VERSION ""

NS_ :

BS_:

BU_: IVI

BO_ 1629 AVM_A6: 6 Vector__XXX
  SG_ FAP_ChangeViewRequest : 0|1@0+ (1,0) [0|0] "" IVI
  SG_ FAP_FramePattern : 7|7@0+ (1,0) [0|127] "wu" IVI
  SG_ FAP_SwitchGrayOutRequest02 : 8|1@0+ (1,0) [0|0] "" IVI
  SG_ FAP_SwitchGrayOutRequest01 : 9|1@0+ (1,0) [0|0] "" IVI
  SG_ FAP_GuideDisplayRequest : 15|6@0+ (1,0) [0|63] "wu" IVI
  SG_ FAP_SwitchGrayOutRequest04 : 16|1@0+ (1,0) [0|0] "" IVI
  SG_ FAP_SwitchGrayOutRequest03 : 17|1@0+ (1,0) [0|0] "" IVI
  SG_ FAP_MessageDisplayRequest : 23|6@0+ (1,0) [0|63] "wu" IVI
  SG_ FAP_SwitchGrayOutRequest06 : 24|1@0+ (1,0) [0|0] "" IVI
  SG_ FAP_SwitchGrayOutRequest05 : 25|1@0+ (1,0) [0|0] "" IVI
  SG_ FAP_ParkingTypeRequest : 31|6@0+ (1,0) [0|63] "wu" IVI
  SG_ FAP_SwitchGrayOutRequest08 : 32|1@0+ (1,0) [0|0] "" IVI
  SG_ FAP_SwitchGrayOutRequest07 : 33|1@0+ (1,0) [0|0] "" IVI
  SG_ FAP_PopupDisplayRequest : 39|6@0+ (1,0) [0|63] "wu" IVI
  SG_ FAP_SwitchGrayOutRequest12 : 41|1@0+ (1,0) [0|0] "" IVI
  SG_ FAP_SwitchGrayOutRequest11 : 42|1@0+ (1,0) [0|0] "" IVI
  SG_ FAP_SwitchGrayOutRequest10 : 43|1@0+ (1,0) [0|0] "" IVI
  SG_ FAP_SwitchGrayOutRequest09 : 44|1@0+ (1,0) [0|0] "" IVI
  SG_ FAP_CameraIndicatorRequest : 47|3@0+ (1,0) [0|0] "" IVI

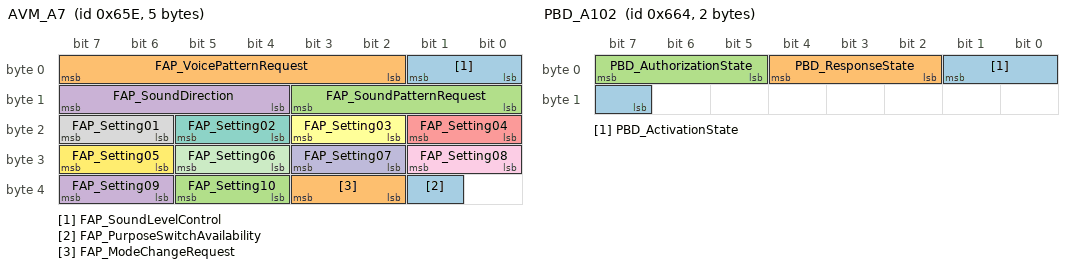
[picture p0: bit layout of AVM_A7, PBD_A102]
BO_ 1630 AVM_A7: 5 Vector__XXX
  SG_ FAP_SoundLevelControl : 1|2@0+ (1,0) [0|0] "" IVI
  SG_ FAP_VoicePatternRequest : 7|6@0+ (1,0) [0|63] "wu" IVI
  SG_ FAP_SoundPatternRequest : 11|4@0+ (1,0) [0|0] "" IVI
  SG_ FAP_SoundDirection : 15|4@0+ (1,0) [0|0] "" IVI
  SG_ FAP_Setting04 : 17|2@0+ (1,0) [0|0] "" IVI
  SG_ FAP_Setting03 : 19|2@0+ (1,0) [0|0] "" IVI
  SG_ FAP_Setting02 : 21|2@0+ (1,0) [0|0] "" IVI
  SG_ FAP_Setting01 : 23|2@0+ (1,0) [0|0] "" IVI
  SG_ FAP_Setting08 : 25|2@0+ (1,0) [0|0] "" IVI
  SG_ FAP_Setting07 : 27|2@0+ (1,0) [0|0] "" IVI
  SG_ FAP_Setting06 : 29|2@0+ (1,0) [0|0] "" IVI
  SG_ FAP_Setting05 : 31|2@0+ (1,0) [0|0] "" IVI
  SG_ FAP_PurposeSwitchAvailability : 33|1@0+ (1,0) [0|0] "" IVI
  SG_ FAP_ModeChangeRequest : 35|2@0+ (1,0) [0|0] "" IVI
  SG_ FAP_Setting10 : 37|2@0+ (1,0) [0|0] "" IVI
  SG_ FAP_Setting09 : 39|2@0+ (1,0) [0|0] "" IVI

BO_ 1634 VDC_R14: 6 Vector__XXX
  SG_ LateralTilt_MMI : 7|7@0+ (1,-60) [-60|60] "°" IVI
  SG_ LongitudinalTilt_MMI : 15|7@0+ (1,-60) [-60|60] "°" IVI

BO_ 1636 PBD_A102: 2 Vector__XXX
  SG_ PBD_ActivationState : 1|3@0+ (1,0) [0|0] "" IVI
  SG_ PBD_ResponseState : 4|3@0+ (1,0) [0|0] "" IVI
  SG_ PBD_AuthorizationState : 7|3@0+ (1,0) [0|0] "" IVI

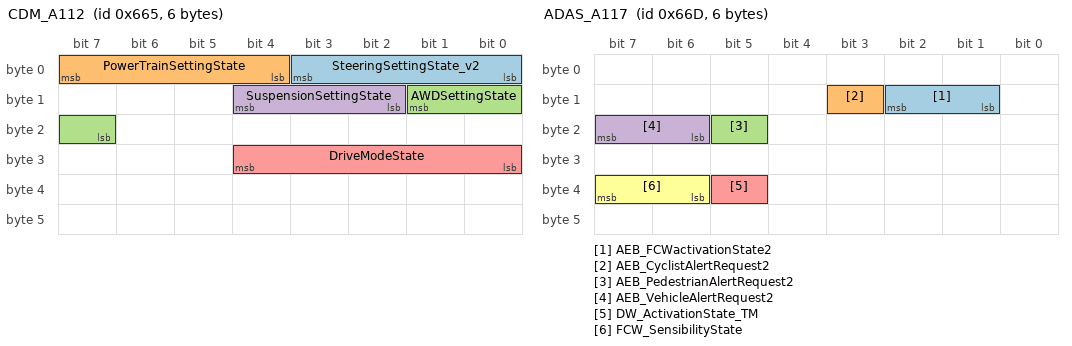
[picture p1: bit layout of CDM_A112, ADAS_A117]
BO_ 1637 CDM_A112: 6 Vector__XXX
  SG_ SteeringSettingState_v2 : 3|4@0+ (1,0) [0|0] "" IVI
  SG_ PowerTrainSettingState : 7|4@0+ (1,0) [0|0] "" IVI
  SG_ AWDSettingState : 9|3@0+ (1,0) [0|0] "" IVI
  SG_ SuspensionSettingState : 12|3@0+ (1,0) [0|0] "" IVI
  SG_ DriveModeState : 28|5@0+ (1,0) [0|0] "" IVI

BO_ 1639 HEVC_A113: 8 Vector__XXX
  SG_ AllRouteSegmentsRequest : 53|1@0+ (1,0) [0|0] "" IVI

BO_ 1640 HEVC_A114: 8 Vector__XXX
  SG_ ChargeSpotPowerLevel : 43|9@0+ (0.3,0) [0|150] "kW" IVI
  SG_ SCdurabilityInhibition : 57|1@0+ (1,0) [0|0] "" IVI

BO_ 1645 ADAS_A117: 6 Vector__XXX
  SG_ AEB_FCWactivationState2 : 10|2@0+ (1,0) [0|0] "" IVI
  SG_ AEB_CyclistAlertRequest2 : 11|1@0+ (1,0) [0|0] "" IVI
  SG_ AEB_PedestrianAlertRequest2 : 21|1@0+ (1,0) [0|0] "" IVI
  SG_ AEB_VehicleAlertRequest2 : 23|2@0+ (1,0) [0|0] "" IVI
  SG_ DW_ActivationState_TM : 37|1@0+ (1,0) [0|0] "" IVI
  SG_ FCW_SensibilityState : 39|2@0+ (1,0) [0|0] "" IVI

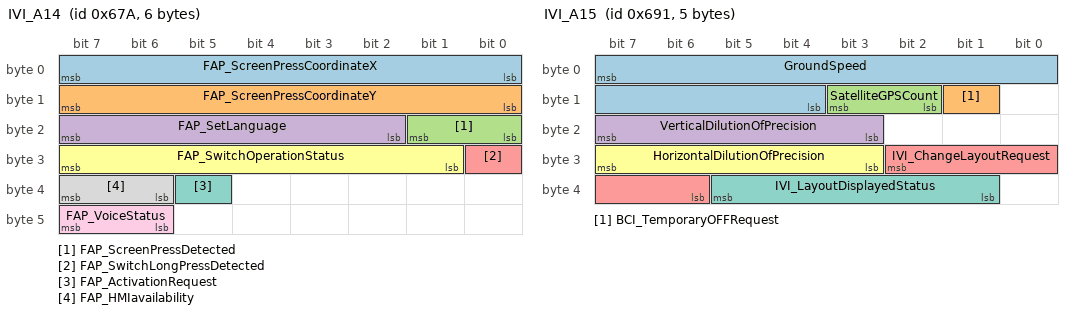
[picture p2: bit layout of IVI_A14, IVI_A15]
BO_ 1658 IVI_A14: 6 IVI
  SG_ FAP_ScreenPressCoordinateX : 7|8@0+ (1,0) [0|255] "wu" Vector__XXX
  SG_ FAP_ScreenPressCoordinateY : 15|8@0+ (1,0) [0|255] "wu" Vector__XXX
  SG_ FAP_ScreenPressDetected : 17|2@0+ (1,0) [0|0] "" Vector__XXX
  SG_ FAP_SetLanguage : 23|6@0+ (1,0) [0|63] "wu" Vector__XXX
  SG_ FAP_SwitchLongPressDetected : 24|1@0+ (1,0) [0|0] "" Vector__XXX
  SG_ FAP_SwitchOperationStatus : 31|7@0+ (1,0) [0|127] "wu" Vector__XXX
  SG_ FAP_ActivationRequest : 37|1@0+ (1,0) [0|0] "" Vector__XXX
  SG_ FAP_HMIavailability : 39|2@0+ (1,0) [0|0] "" Vector__XXX
  SG_ FAP_VoiceStatus : 47|2@0+ (1,0) [0|0] "" Vector__XXX

BO_ 1659 HFM_A102: 3 Vector__XXX
  SG_ UserIdentification_IKeyLink : 7|3@0+ (1,0) [0|0] "" IVI

BO_ 1660 HVAC_A102: 8 Vector__XXX
  SG_ RearSeatsLockStatus : 1|2@0+ (1,0) [0|0] "" IVI
  SG_ SecondRowRightSeatStatus : 4|3@0+ (1,0) [0|0] "" IVI
  SG_ SecondRowLeftSeatStatus : 7|3@0+ (1,0) [0|0] "" IVI
  SG_ ClimAutoRecyclingDisplayStatus : 8|1@0+ (1,0) [0|0] "" IVI
  SG_ ClimACDisplayStatus : 9|1@0+ (1,0) [0|0] "" IVI
  SG_ ThirdRowRightSeatStatus : 12|3@0+ (1,0) [0|0] "" IVI
  SG_ ThirdRowLeftSeatStatus : 15|3@0+ (1,0) [0|0] "" IVI
  SG_ ClimEVHeaterDisplayStatus : 16|1@0+ (1,0) [0|0] "" IVI
  SG_ ClimDriverZoneDisplayStatus : 17|1@0+ (1,0) [0|0] "" IVI
  SG_ ClimDriverZoneDisplay : 19|2@0+ (1,0) [0|0] "" IVI
  SG_ ClimClearnessDisplayStatus : 20|1@0+ (1,0) [0|0] "" IVI
  SG_ ClimBlowingLevelDisplayStatus : 21|1@0+ (1,0) [0|0] "" IVI
  SG_ ClimBlowingAutoDisplay : 23|2@0+ (1,0) [0|0] "" IVI
  SG_ ClimHumidityDisplayStatus : 24|1@0+ (1,0) [0|0] "" IVI
  SG_ ClimForestSettingDisplayStatus : 25|1@0+ (1,0) [0|0] "" IVI
  SG_ ClimForestDisplayStatus : 26|1@0+ (1,0) [0|0] "" IVI
  SG_ ClimForestDisplay : 28|2@0+ (1,0) [0|0] "" IVI
  SG_ ClimFlowDistrDisplayStatus : 29|1@0+ (1,0) [0|0] "" IVI
  SG_ ClimEVHeaterDisplay : 31|2@0+ (1,0) [0|0] "" IVI
  SG_ ClimLinkDefrostAndClearnesDisp : 33|2@0+ (1,0) [0|0] "" IVI
  SG_ ClimHumiditySensorSensitivDisp : 36|3@0+ (1,0) [0|0] "" IVI
  SG_ ClimHumidityDisplay : 39|3@0+ (1,0) [0|0] "" IVI
  SG_ ClimRightAutoDisplay : 41|2@0+ (1,0) [0|0] "" IVI
  SG_ ClimOFFModeDisplayStatus : 42|1@0+ (1,0) [0|0] "" IVI
  SG_ ClimLinkMaxFanSpeedAutoDisplay : 45|3@0+ (1,0) [0|0] "" IVI
  SG_ ClimLinkFreshRecyAndAutoDisplay : 47|2@0+ (1,0) [0|0] "" IVI
  SG_ ClimRightFlowDistrDisplayStatus : 48|1@0+ (1,0) [0|0] "" IVI
  SG_ ClimRightBlowingLevelDispStatus : 49|1@0+ (1,0) [0|0] "" IVI
  SG_ ClimRightBlowingLevelDisplay : 53|4@0+ (1,0) [0|0] "" IVI
  SG_ ClimRightBlowingAutoDisplay : 55|2@0+ (1,0) [0|0] "" IVI
  SG_ ClimTempDisplayStatus : 56|1@0+ (1,0) [0|0] "" IVI
  SG_ ClimSyncDisplayStatus : 57|1@0+ (1,0) [0|0] "" IVI
  SG_ ClimSyncDisplay : 59|2@0+ (1,0) [0|0] "" IVI
  SG_ ClimRightTempDisplayStatus : 60|1@0+ (1,0) [0|0] "" IVI
  SG_ ClimRightFlowDistrDisplay : 63|3@0+ (1,0) [0|0] "" IVI

BO_ 1661 IVI_N104: 7 IVI
  SG_ AltitudePosition : 7|16@0+ (0.1,-500) [-500|3000] "m" Vector__XXX
  SG_ ITM_FrontLeftSeatHeatPush : 16|1@0+ (1,0) [0|1] "-" Vector__XXX
  SG_ ITM_FrontLeftSeatDownPush : 17|1@0+ (1,0) [0|1] "" Vector__XXX
  SG_ ITM_ForcedRecyclingLongPush : 18|1@0+ (1,0) [0|1] "-" Vector__XXX
  SG_ ITM_ForcedFreshLongPush : 19|1@0+ (1,0) [0|1] "-" Vector__XXX
  SG_ ITM_AirIntakeOperationType : 21|2@0+ (1,0) [0|0] "" Vector__XXX
  SG_ ITM_AirIntakeModePush : 22|1@0+ (1,0) [0|1] "-" Vector__XXX
  SG_ ITM_AirIntakeModeLongPush : 23|1@0+ (1,0) [0|1] "-" Vector__XXX
  SG_ ITM_FrontRightSeatUpPush : 26|1@0+ (1,0) [0|1] "" Vector__XXX
  SG_ ITM_FrontRightSeatOFFPush : 27|1@0+ (1,0) [0|1] "-" Vector__XXX
  SG_ ITM_FrontRightSeatHeatPush : 28|1@0+ (1,0) [0|1] "-" Vector__XXX
  SG_ ITM_FrontRightSeatDownPush : 29|1@0+ (1,0) [0|1] "" Vector__XXX
  SG_ ITM_FrontLeftSeatUpPush : 30|1@0+ (1,0) [0|1] "" Vector__XXX
  SG_ ITM_FrontLeftSeatOFFPush : 31|1@0+ (1,0) [0|1] "-" Vector__XXX
  SG_ ITM_SecondRowRightSeatDownPush : 32|1@0+ (1,0) [0|1] "" Vector__XXX
  SG_ ITM_SecondRowLeftSeatUpPush : 33|1@0+ (1,0) [0|1] "" Vector__XXX
  SG_ ITM_SecondRowLeftSeatOFFPush : 34|1@0+ (1,0) [0|1] "-" Vector__XXX
  SG_ ITM_SecondRowLeftSeatHeatPush : 35|1@0+ (1,0) [0|1] "-" Vector__XXX
  SG_ ITM_SecondRowLeftSeatDownPush : 36|1@0+ (1,0) [0|1] "" Vector__XXX
  SG_ ITM_RecyclingModeRequest : 39|3@0+ (1,0) [0|0] "" Vector__XXX
  SG_ ITM_ThirdRowRightSeatDownPush : 40|1@0+ (1,0) [0|1] "" Vector__XXX
  SG_ ITM_ThirdRowLeftSeatUpPush : 41|1@0+ (1,0) [0|1] "" Vector__XXX
  SG_ ITM_ThirdRowLeftSeatOFFPush : 42|1@0+ (1,0) [0|1] "-" Vector__XXX
  SG_ ITM_ThirdRowLeftSeatHeatPush : 43|1@0+ (1,0) [0|1] "-" Vector__XXX
  SG_ ITM_ThirdRowLeftSeatDownPush : 44|1@0+ (1,0) [0|1] "" Vector__XXX
  SG_ ITM_SecondRowRightSeatUpPush : 45|1@0+ (1,0) [0|1] "" Vector__XXX
  SG_ ITM_SecondRowRightSeatOFFPush : 46|1@0+ (1,0) [0|1] "-" Vector__XXX
  SG_ ITM_SecondRowRightSeatHeatPush : 47|1@0+ (1,0) [0|1] "-" Vector__XXX
  SG_ ITM_ThirdRowRightSeatUpPush : 53|1@0+ (1,0) [0|1] "" Vector__XXX
  SG_ ITM_ThirdRowRightSeatOFFPush : 54|1@0+ (1,0) [0|1] "-" Vector__XXX
  SG_ ITM_ThirdRowRightSeatHeatPush : 55|1@0+ (1,0) [0|1] "-" Vector__XXX

BO_ 1662 IVI_A102: 8 IVI
  SG_ PassengerSeatMemoRecall : 4|3@0+ (1,0) [0|0] "" Vector__XXX
  SG_ PassengerSeatMemoRequest : 7|3@0+ (1,0) [0|0] "" Vector__XXX
  SG_ SecondRowRightSeatRequest : 11|4@0+ (1,0) [0|0] "" Vector__XXX
  SG_ SecondRowLeftSeatRequest : 15|4@0+ (1,0) [0|0] "" Vector__XXX
  SG_ ThirdRowRightSeatRequest : 19|4@0+ (1,0) [0|0] "" Vector__XXX
  SG_ ThirdRowLeftSeatRequest : 23|4@0+ (1,0) [0|0] "" Vector__XXX
  SG_ ClimClearnessPush : 24|1@0+ (1,0) [0|1] "-" Vector__XXX
  SG_ ClimACPush : 25|1@0+ (1,0) [0|1] "-" Vector__XXX
  SG_ WirelessChargeActivationReq : 27|2@0+ (1,0) [0|0] "" Vector__XXX
  SG_ RearSeatsLockRequest : 31|2@0+ (1,0) [0|0] "" Vector__XXX
  SG_ ClimHumiditySensorSensitivitReq : 34|3@0+ (1,0) [0|0] "" Vector__XXX
  SG_ ClimForestPush : 35|1@0+ (1,0) [0|1] "" Vector__XXX
  SG_ ClimForcedRecyclingPush : 36|1@0+ (1,0) [0|1] "-" Vector__XXX
  SG_ ClimForcedFreshPush : 37|1@0+ (1,0) [0|1] "-" Vector__XXX
  SG_ ClimEVHeaterPush : 38|1@0+ (1,0) [0|1] "-" Vector__XXX
  SG_ ClimDriverZonePush : 39|1@0+ (1,0) [0|1] "" Vector__XXX
  SG_ ClimRightFlowDistrDefPush : 40|1@0+ (1,0) [0|1] "-" Vector__XXX
  SG_ TimeFormatDisplay : 43|1@0+ (1,0) [0|0] "" Vector__XXX
  SG_ ClimFPrightBlowingRequest : 47|4@0+ (1,0) [0|0] "" Vector__XXX
  SG_ ClimRightFlowDistrVentPush : 48|1@0+ (1,0) [0|1] "-" Vector__XXX
  SG_ ClimRightFlowDistrFeetPush : 49|1@0+ (1,0) [0|1] "-" Vector__XXX
  SG_ ClimLinkPriorityFLSeatAutoReq : 52|3@0+ (1,0) [0|0] "" Vector__XXX
  SG_ ClimLinkMaxFanSpeedAutoReq : 55|3@0+ (1,0) [0|0] "" Vector__XXX
  SG_ ClimLinkDefrostAndClearnesPush : 56|1@0+ (1,0) [0|1] "" Vector__XXX
  SG_ ClimRightAutoNormalPush : 57|1@0+ (1,0) [0|1] "-" Vector__XXX
  SG_ FrontRightSeatAutoPush : 58|1@0+ (1,0) [0|1] "-" Vector__XXX
  SG_ FrontLeftSeatAutoPush : 59|1@0+ (1,0) [0|1] "-" Vector__XXX
  SG_ ClimSyncPush : 60|1@0+ (1,0) [0|1] "-" Vector__XXX
  SG_ ClimLinkPriorityFRSeatAutoReq : 63|3@0+ (1,0) [0|0] "" Vector__XXX

BO_ 1677 IVI_A6: 3 IVI
  SG_ DistanceToDestination : 7|12@0+ (20,0) [0|81880] "m" Vector__XXX
  SG_ TimeToDestination : 11|10@0+ (10,0) [0|10220] "s" Vector__XXX

BO_ 1681 IVI_A15: 5 IVI
  SG_ GroundSpeed : 7|12@0+ (0.05,0) [0|150] "Kph" Vector__XXX
  SG_ BCI_TemporaryOFFRequest : 9|1@0+ (1,0) [0|0] "" Vector__XXX
  SG_ SatelliteGPSCount : 11|2@0+ (1,0) [0|3] "wu" Vector__XXX
  SG_ VerticalDilutionOfPrecision : 23|5@0+ (0.1,0) [0|3.1] "wu" Vector__XXX
  SG_ IVI_ChangeLayoutRequest : 26|5@0+ (1,0) [0|0] "" Vector__XXX
  SG_ HorizontalDilutionOfPrecision : 31|5@0+ (0.1,0) [0|3.1] "wu" Vector__XXX
  SG_ IVI_LayoutDisplayedStatus : 37|5@0+ (1,0) [0|0] "" Vector__XXX

BO_ 1682 HVAC_A6: 2 Vector__XXX
  SG_ ClimHeatedSteeringWheelDisplay : 5|2@0+ (1,0) [0|0] "" IVI
  SG_ ClimDualModeDisplay_v2 : 7|2@0+ (1,0) [0|0] "" IVI

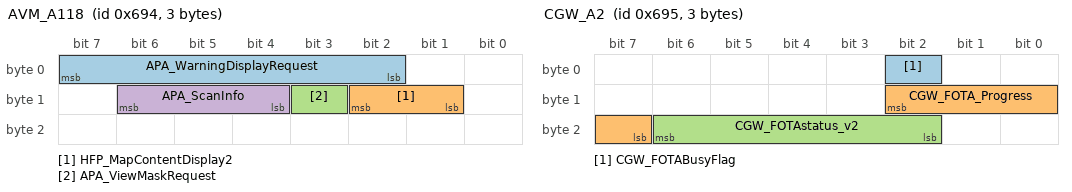
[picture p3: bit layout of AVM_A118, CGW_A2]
BO_ 1684 AVM_A118: 3 Vector__XXX
  SG_ APA_WarningDisplayRequest : 7|6@0+ (1,0) [0|0] "" IVI
  SG_ HFP_MapContentDisplay2 : 10|2@0+ (1,0) [0|0] "" IVI
  SG_ APA_ViewMaskRequest : 11|1@0+ (1,0) [0|0] "" IVI
  SG_ APA_ScanInfo : 14|3@0+ (1,0) [0|0] "" IVI

BO_ 1685 CGW_A2: 3 Vector__XXX
  SG_ CGW_FOTABusyFlag : 2|1@0+ (1,0) [0|0] "" IVI
  SG_ CGW_FOTA_Progress : 10|4@0+ (10,0) [0|100] "%" IVI
  SG_ CGW_FOTAstatus_v2 : 22|5@0+ (1,0) [0|0] "" IVI

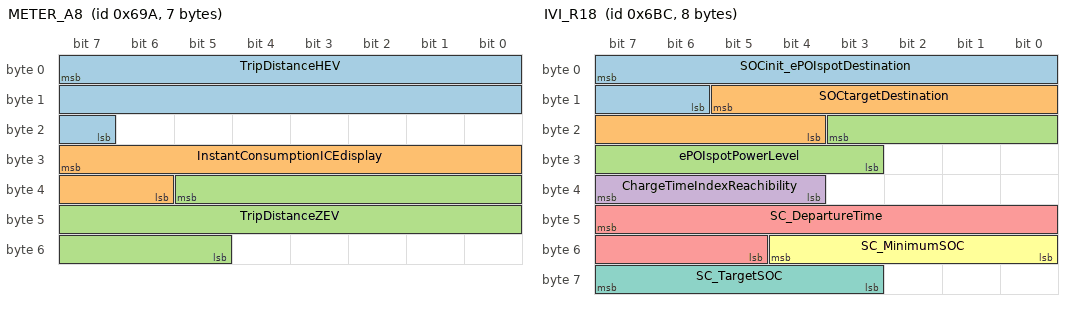
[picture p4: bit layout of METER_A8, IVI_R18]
BO_ 1690 METER_A8: 7 Vector__XXX
  SG_ TripDistanceHEV : 7|17@0+ (0.1,0) [0|10000] "-" IVI
  SG_ InstantConsumptionICEdisplay : 31|10@0+ (0.1,0) [0|102.3] "" IVI
  SG_ TripDistanceZEV : 37|17@0+ (0.1,0) [0|10000] "-" IVI

BO_ 1695 VehicleID_CANHS_R_01: 4 Vector__XXX
  SG_ VehicleID : 7|32@0+ (1,0) [0|0] "" IVI

BO_ 1697 ADASISv2_A106: 8 IVI
  SG_ ADASISv2_METADATA : 7|64@0+ (1,0) [0|0] "" Vector__XXX

BO_ 1703 BCM_R14: 6 Vector__XXX
  SG_ ProgrammedChargeStatus : 45|2@0+ (1,0) [0|0] "" IVI

BO_ 1724 IVI_R18: 8 IVI
  SG_ SOCinit_ePOIspotDestination : 7|10@0+ (0.1,0) [0|100] "%" Vector__XXX
  SG_ SOCtargetDestination : 13|10@0+ (0.1,0) [0|100] "%" Vector__XXX
  SG_ ePOIspotPowerLevel : 19|9@0+ (0.2,0) [0|100] "kW" Vector__XXX
  SG_ ChargeTimeIndexReachibility : 39|4@0+ (1,0) [0|0] "" Vector__XXX
  SG_ SC_DepartureTime : 47|11@0+ (5,0) [0|10080] "min" Vector__XXX
  SG_ SC_MinimumSOC : 52|5@0+ (5,0) [0|100] "%" Vector__XXX
  SG_ SC_TargetSOC : 63|5@0+ (5,0) [0|100] "%" Vector__XXX

BO_ 1742 ADAS_A124: 7 Vector__XXX
  SG_ PreferedLaneAssist_State : 37|2@0+ (1,0) [0|0] "" IVI

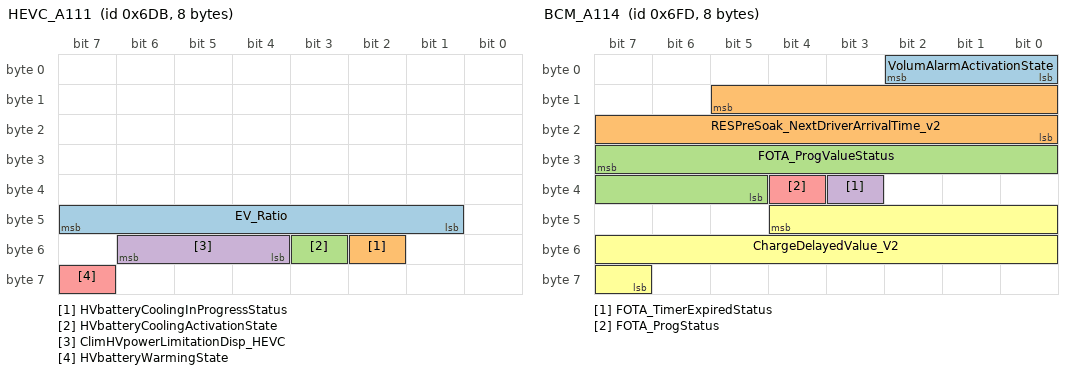
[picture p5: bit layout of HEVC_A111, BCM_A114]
BO_ 1755 HEVC_A111: 8 Vector__XXX
  SG_ EV_Ratio : 47|7@0+ (1,0) [0|100] "%" IVI
  SG_ HVbatteryCoolingInProgressStatus : 50|1@0+ (1,0) [0|0] "" IVI
  SG_ HVbatteryCoolingActivationState : 51|1@0+ (1,0) [0|0] "" IVI
  SG_ ClimHVpowerLimitationDisp_HEVC : 54|3@0+ (1,0) [0|0] "" IVI
  SG_ HVbatteryWarmingState : 63|1@0+ (1,0) [0|0] "" IVI

BO_ 1779 IVI_R8: 8 IVI
  SG_ ChargeCal1DurationChange_MMI : 7|11@0+ (1,0) [0|1440] "min" Vector__XXX
  SG_ ChargeCal1BeginHourChange_MMI : 12|5@0+ (1,0) [0|23] "h" Vector__XXX
  SG_ ChargeCal1TuesdayChange_MMI : 16|1@0+ (1,0) [0|0] "" Vector__XXX
  SG_ ChargeCal1MondayChange_MMI : 17|1@0+ (1,0) [0|0] "" Vector__XXX
  SG_ ChargeCal1BeginMinChange_MMI : 23|6@0+ (1,0) [0|59] "min" Vector__XXX
  SG_ ChargeCal1SundayChange_MMI : 27|1@0+ (1,0) [0|0] "" Vector__XXX
  SG_ ChargeCal1SaturdayChange_MMI : 28|1@0+ (1,0) [0|0] "" Vector__XXX
  SG_ ChargeCal1FridayChange_MMI : 29|1@0+ (1,0) [0|0] "" Vector__XXX
  SG_ ChargeCal1ThursdayChange_MMI : 30|1@0+ (1,0) [0|0] "" Vector__XXX
  SG_ ChargeCal1WednesdayChange_MMI : 31|1@0+ (1,0) [0|0] "" Vector__XXX
  SG_ ChargeCal2DurationChange_MMI : 39|11@0+ (1,0) [0|1440] "min" Vector__XXX
  SG_ ChargeCal2BeginHourChange_MMI : 44|5@0+ (1,0) [0|23] "h" Vector__XXX
  SG_ ChargeCal2TuesdayChange_MMI : 48|1@0+ (1,0) [0|0] "" Vector__XXX
  SG_ ChargeCal2MondayChange_MMI : 49|1@0+ (1,0) [0|0] "" Vector__XXX
  SG_ ChargeCal2BeginMinChange_MMI : 55|6@0+ (1,0) [0|59] "min" Vector__XXX
  SG_ ChargeCalAllChange_MMI : 58|2@0+ (1,0) [0|0] "" Vector__XXX
  SG_ ChargeCal2SundayChange_MMI : 59|1@0+ (1,0) [0|0] "" Vector__XXX
  SG_ ChargeCal2SaturdayChange_MMI : 60|1@0+ (1,0) [0|0] "" Vector__XXX
  SG_ ChargeCal2FridayChange_MMI : 61|1@0+ (1,0) [0|0] "" Vector__XXX
  SG_ ChargeCal2ThursdayChange_MMI : 62|1@0+ (1,0) [0|0] "" Vector__XXX
  SG_ ChargeCal2WednesdayChange_MMI : 63|1@0+ (1,0) [0|0] "" Vector__XXX

BO_ 1780 IVI_R9: 8 IVI
  SG_ ChargeCal3DurationChange_MMI : 7|11@0+ (1,0) [0|1440] "min" Vector__XXX
  SG_ ChargeCal3BeginHourChange_MMI : 12|5@0+ (1,0) [0|23] "h" Vector__XXX
  SG_ ChargeCal3TuesdayChange_MMI : 16|1@0+ (1,0) [0|0] "" Vector__XXX
  SG_ ChargeCal3MondayChange_MMI : 17|1@0+ (1,0) [0|0] "" Vector__XXX
  SG_ ChargeCal3BeginMinChange_MMI : 23|6@0+ (1,0) [0|59] "min" Vector__XXX
  SG_ ChargeCal3SundayChange_MMI : 27|1@0+ (1,0) [0|0] "" Vector__XXX
  SG_ ChargeCal3SaturdayChange_MMI : 28|1@0+ (1,0) [0|0] "" Vector__XXX
  SG_ ChargeCal3FridayChange_MMI : 29|1@0+ (1,0) [0|0] "" Vector__XXX
  SG_ ChargeCal3ThursdayChange_MMI : 30|1@0+ (1,0) [0|0] "" Vector__XXX
  SG_ ChargeCal3WednesdayChange_MMI : 31|1@0+ (1,0) [0|0] "" Vector__XXX
  SG_ ChargeCal4DurationChange_MMI : 39|11@0+ (1,0) [0|1440] "min" Vector__XXX
  SG_ ChargeCal4BeginHourChange_MMI : 44|5@0+ (1,0) [0|23] "h" Vector__XXX
  SG_ ChargeCal4TuesdayChange_MMI : 48|1@0+ (1,0) [0|0] "" Vector__XXX
  SG_ ChargeCal4MondayChange_MMI : 49|1@0+ (1,0) [0|0] "" Vector__XXX
  SG_ ChargeCal4BeginMinChange_MMI : 55|6@0+ (1,0) [0|59] "min" Vector__XXX
  SG_ ChargeCal4SundayChange_MMI : 59|1@0+ (1,0) [0|0] "" Vector__XXX
  SG_ ChargeCal4SaturdayChange_MMI : 60|1@0+ (1,0) [0|0] "" Vector__XXX
  SG_ ChargeCal4FridayChange_MMI : 61|1@0+ (1,0) [0|0] "" Vector__XXX
  SG_ ChargeCal4ThursdayChange_MMI : 62|1@0+ (1,0) [0|0] "" Vector__XXX
  SG_ ChargeCal4WednesdayChange_MMI : 63|1@0+ (1,0) [0|0] "" Vector__XXX

BO_ 1781 IVI_R10: 8 IVI
  SG_ ChargeCal5DurationChange_MMI : 7|11@0+ (1,0) [0|1440] "min" Vector__XXX
  SG_ ChargeCal5BeginHourChange_MMI : 12|5@0+ (1,0) [0|23] "h" Vector__XXX
  SG_ ChargeCal5TuesdayChange_MMI : 16|1@0+ (1,0) [0|0] "" Vector__XXX
  SG_ ChargeCal5MondayChange_MMI : 17|1@0+ (1,0) [0|0] "" Vector__XXX
  SG_ ChargeCal5BeginMinChange_MMI : 23|6@0+ (1,0) [0|59] "min" Vector__XXX
  SG_ ChargeDelayedRequestValue : 26|11@0+ (1,1) [1|1440] "min" Vector__XXX
  SG_ ChargeCal5SundayChange_MMI : 27|1@0+ (1,0) [0|0] "" Vector__XXX
  SG_ ChargeCal5SaturdayChange_MMI : 28|1@0+ (1,0) [0|0] "" Vector__XXX
  SG_ ChargeCal5FridayChange_MMI : 29|1@0+ (1,0) [0|0] "" Vector__XXX
  SG_ ChargeCal5ThursdayChange_MMI : 30|1@0+ (1,0) [0|0] "" Vector__XXX
  SG_ ChargeCal5WednesdayChange_MMI : 31|1@0+ (1,0) [0|0] "" Vector__XXX
  SG_ EcoTripResetRequest : 40|1@0+ (1,0) [0|0] "" Vector__XXX
  SG_ SC_UserElecPriceSetNbSlot : 45|5@0+ (1,0) [0|24] "" Vector__XXX
  SG_ ChargeDelayedRequest : 46|1@0+ (1,0) [0|0] "" Vector__XXX
  SG_ ChargeAlwaysRequest : 47|1@0+ (1,0) [0|0] "" Vector__XXX
  SG_ SC_UserElecPriceSetSlotDuration : 55|5@0+ (30,0) [0|720] "min" Vector__XXX
  SG_ SC_UserElecPriceSetRelativeCost : 62|4@0+ (1,0) [0|15] "" Vector__XXX
  SG_ FuelSaveClearHistoRequest : 63|1@0+ (1,0) [0|0] "" Vector__XXX

BO_ 1782 IVI_R11: 7 IVI
  SG_ PreSoakCal1ArrivalHourChange_MMI : 1|5@0+ (1,0) [0|23] "h" Vector__XXX
  SG_ PreSoakCal1ArrivalMinChange_MMI : 7|6@0+ (1,0) [0|59] "min" Vector__XXX
  SG_ PreSoakCal1FridayChange_MMI : 8|1@0+ (1,0) [0|0] "" Vector__XXX
  SG_ PreSoakCal1ThursdayChange_MMI : 9|1@0+ (1,0) [0|0] "" Vector__XXX
  SG_ PreSoakCal1WednesdayChange_MMI : 10|1@0+ (1,0) [0|0] "" Vector__XXX
  SG_ PreSoakCal1TuesdayChange_MMI : 11|1@0+ (1,0) [0|0] "" Vector__XXX
  SG_ PreSoakCal1MondayChange_MMI : 12|1@0+ (1,0) [0|0] "" Vector__XXX
  SG_ PreSoakCal2ArrivalMinChange_MMI : 21|6@0+ (1,0) [0|59] "min" Vector__XXX
  SG_ PreSoakCal1SundayChange_MMI : 22|1@0+ (1,0) [0|0] "" Vector__XXX
  SG_ PreSoakCal1SaturdayChange_MMI : 23|1@0+ (1,0) [0|0] "" Vector__XXX
  SG_ PreSoakCal2WednesdayChange_MMI : 24|1@0+ (1,0) [0|0] "" Vector__XXX
  SG_ PreSoakCal2TuesdayChange_MMI : 25|1@0+ (1,0) [0|0] "" Vector__XXX
  SG_ PreSoakCal2MondayChange_MMI : 26|1@0+ (1,0) [0|0] "" Vector__XXX
  SG_ PreSoakCal2ArrivalHourChange_MMI : 31|5@0+ (1,0) [0|23] "h" Vector__XXX
  SG_ PreSoakCal3ArrivalMinChange_MMI : 35|6@0+ (1,0) [0|59] "min" Vector__XXX
  SG_ PreSoakCal2SundayChange_MMI : 36|1@0+ (1,0) [0|0] "" Vector__XXX
  SG_ PreSoakCal2SaturdayChange_MMI : 37|1@0+ (1,0) [0|0] "" Vector__XXX
  SG_ PreSoakCal2FridayChange_MMI : 38|1@0+ (1,0) [0|0] "" Vector__XXX
  SG_ PreSoakCal2ThursdayChange_MMI : 39|1@0+ (1,0) [0|0] "" Vector__XXX
  SG_ PreSoakCal3MondayChange_MMI : 40|1@0+ (1,0) [0|0] "" Vector__XXX
  SG_ PreSoakCal3ArrivalHourChange_MMI : 45|5@0+ (1,0) [0|23] "h" Vector__XXX
  SG_ PreSoakCalAllChange_MMI : 49|2@0+ (1,0) [0|0] "" Vector__XXX
  SG_ PreSoakCal3SundayChange_MMI : 50|1@0+ (1,0) [0|0] "" Vector__XXX
  SG_ PreSoakCal3SaturdayChange_MMI : 51|1@0+ (1,0) [0|0] "" Vector__XXX
  SG_ PreSoakCal3FridayChange_MMI : 52|1@0+ (1,0) [0|0] "" Vector__XXX
  SG_ PreSoakCal3ThursdayChange_MMI : 53|1@0+ (1,0) [0|0] "" Vector__XXX
  SG_ PreSoakCal3WednesdayChange_MMI : 54|1@0+ (1,0) [0|0] "" Vector__XXX
  SG_ PreSoakCal3TuesdayChange_MMI : 55|1@0+ (1,0) [0|0] "" Vector__XXX

BO_ 1783 IVI_R12: 7 IVI
  SG_ PreSoakCal4ArrivalHourChange_MMI : 1|5@0+ (1,0) [0|23] "h" Vector__XXX
  SG_ PreSoakCal4ArrivalMinChange_MMI : 7|6@0+ (1,0) [0|59] "min" Vector__XXX
  SG_ PreSoakCal4FridayChange_MMI : 8|1@0+ (1,0) [0|0] "" Vector__XXX
  SG_ PreSoakCal4ThursdayChange_MMI : 9|1@0+ (1,0) [0|0] "" Vector__XXX
  SG_ PreSoakCal4WednesdayChange_MMI : 10|1@0+ (1,0) [0|0] "" Vector__XXX
  SG_ PreSoakCal4TuesdayChange_MMI : 11|1@0+ (1,0) [0|0] "" Vector__XXX
  SG_ PreSoakCal4MondayChange_MMI : 12|1@0+ (1,0) [0|0] "" Vector__XXX
  SG_ PreSoakCal5ArrivalMinChange_MMI : 21|6@0+ (1,0) [0|59] "min" Vector__XXX
  SG_ PreSoakCal4SundayChange_MMI : 22|1@0+ (1,0) [0|0] "" Vector__XXX
  SG_ PreSoakCal4SaturdayChange_MMI : 23|1@0+ (1,0) [0|0] "" Vector__XXX
  SG_ PreSoakCal5WednesdayChange_MMI : 24|1@0+ (1,0) [0|0] "" Vector__XXX
  SG_ PreSoakCal5TuesdayChange_MMI : 25|1@0+ (1,0) [0|0] "" Vector__XXX
  SG_ PreSoakCal5MondayChange_MMI : 26|1@0+ (1,0) [0|0] "" Vector__XXX
  SG_ PreSoakCal5ArrivalHourChange_MMI : 31|5@0+ (1,0) [0|23] "h" Vector__XXX
  SG_ GainECOdistanceDisplay : 35|13@0+ (0.1,0) [0|800] "wu" Vector__XXX
  SG_ PreSoakCal5SundayChange_MMI : 36|1@0+ (1,0) [0|0] "" Vector__XXX
  SG_ PreSoakCal5SaturdayChange_MMI : 37|1@0+ (1,0) [0|0] "" Vector__XXX
  SG_ PreSoakCal5FridayChange_MMI : 38|1@0+ (1,0) [0|0] "" Vector__XXX
  SG_ PreSoakCal5ThursdayChange_MMI : 39|1@0+ (1,0) [0|0] "" Vector__XXX

BO_ 1789 BCM_A114: 8 Vector__XXX
  SG_ VolumAlarmActivationState : 2|3@0+ (1,0) [0|0] "" IVI
  SG_ RESPreSoak_NextDriverArrivalTime_v2 : 13|14@0+ (1,0) [0|10080] "min" IVI
  SG_ FOTA_ProgValueStatus : 31|11@0+ (1,0) [0|1440] "min" IVI
  SG_ FOTA_TimerExpiredStatus : 35|1@0+ (1,0) [0|0] "" IVI
  SG_ FOTA_ProgStatus : 36|1@0+ (1,0) [0|0] "" IVI
  SG_ ChargeDelayedValue_V2 : 44|14@0+ (1,0) [0|10080] "min" IVI

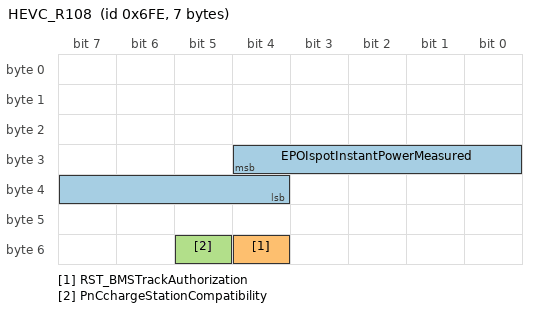
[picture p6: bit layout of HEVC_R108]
BO_ 1790 HEVC_R108: 7 Vector__XXX
  SG_ EPOIspotInstantPowerMeasured : 28|9@0+ (0.2,0) [0|100] "kW" IVI
  SG_ RST_BMSTrackAuthorization : 52|1@0+ (1,0) [0|0] "" IVI
  SG_ PnCchargeStationCompatibility : 53|1@0+ (1,0) [0|0] "" IVI

BO_ 1791 HEVC_R109: 8 Vector__XXX
  SG_ FuelSaveSinceClearHistoZEV : 28|14@0+ (0.1,0) [0|1024] "" IVI

BO_ 1812 DTOOL_to_CPANEL: 8 Vector__XXX
  SG_ DTOOL_to_CPANEL : 7|64@0+ (1,0) [0|0] "" IVI

BO_ 1844 CPANEL_to_DTOOL: 8 IVI
  SG_ CPANEL_to_DTOOL : 7|64@0+ (1,0) [0|0] "" Vector__XXX

BO_ 1863 DTOOL_to_NAV: 8 Vector__XXX
  SG_ DTOOL_to_NAV : 7|64@0+ (1,0) [0|0] "" IVI

BO_ 1895 NAV_to_DTOOL: 8 IVI
  SG_ NAV_to_DTOOL : 7|64@0+ (1,0) [0|0] "" Vector__XXX

BO_ 2563507968 SIGMA_CDMTriggerFrame: 7 Vector__XXX
  SG_ SIGMA_CDM : 4|29@0+ (1,0) [0|0] "" IVI
  SG_ SIGMA_DTCCDM : 39|24@0+ (1,0) [0|0] "" IVI

BO_ 2563508019 SIGMA_PBDTriggerFrame: 7 Vector__XXX
  SG_ SIGMA_PBD : 4|29@0+ (1,0) [0|0] "" IVI
  SG_ SIGMA_DTCPBD : 39|24@0+ (1,0) [0|0] "" IVI

BO_ 2563508021 SIGMA_RADARTriggerFrame: 7 Vector__XXX
  SG_ SIGMA_RADAR : 4|29@0+ (1,0) [0|0] "" IVI
  SG_ SIGMA_DTCRADAR : 39|24@0+ (1,0) [0|0] "" IVI

BO_ 2563508022 SIGMA_PSCUTriggerFrame: 7 Vector__XXX
  SG_ SIGMA_PSCU : 4|29@0+ (1,0) [0|0] "" IVI
  SG_ SIGMA_DTCPSCU : 39|24@0+ (1,0) [0|0] "" IVI

BO_ 2563508030 SIGMA_SRad_RLTriggerFrame: 7 Vector__XXX
  SG_ SIGMA_SRad_RL : 4|29@0+ (1,0) [0|0] "" IVI
  SG_ SIGMA_DTCSRad_RL : 39|24@0+ (1,0) [0|0] "" IVI

BO_ 2563508042 SIGMA_ANCTriggerFrame: 7 Vector__XXX
  SG_ SIGMA_ANC : 4|29@0+ (1,0) [0|0] "" IVI
  SG_ SIGMA_DTCANC : 39|24@0+ (1,0) [0|0] "" IVI

BO_ 2563508064 SIGMA_VDCTriggerFrame: 7 Vector__XXX
  SG_ SIGMA_VDC : 4|29@0+ (1,0) [0|0] "" IVI
  SG_ SIGMA_DTCVDC : 39|24@0+ (1,0) [0|0] "" IVI

BO_ 2563508066 SIGMA_EPSTriggerFrame: 7 Vector__XXX
  SG_ SIGMA_EPS : 4|29@0+ (1,0) [0|0] "" IVI
  SG_ SIGMA_DTCEPS : 39|24@0+ (1,0) [0|0] "" IVI

BO_ 2563508067 SIGMA_METERTriggerFrame: 7 Vector__XXX
  SG_ SIGMA_METER : 4|29@0+ (1,0) [0|0] "" IVI
  SG_ SIGMA_DTCMETER : 39|24@0+ (1,0) [0|0] "" IVI

BO_ 2563508068 SIGMA_HVACTriggerFrame: 7 Vector__XXX
  SG_ SIGMA_HVAC : 4|29@0+ (1,0) [0|0] "" IVI
  SG_ SIGMA_DTCHVAC : 39|24@0+ (1,0) [0|0] "" IVI

BO_ 2563508069 SIGMA_BCMTriggerFrame: 7 Vector__XXX
  SG_ SIGMA_BCM : 4|29@0+ (1,0) [0|0] "" IVI
  SG_ SIGMA_DTCBCM : 39|24@0+ (1,0) [0|0] "" IVI

BO_ 2563508071 SIGMA_IVITriggerFrame: 7 IVI
  SG_ SIGMA_IVI : 4|29@0+ (1,0) [0|0] "" Vector__XXX
  SG_ SIGMA_DTCIVI : 39|24@0+ (1,0) [0|0] "" Vector__XXX

BO_ 2563508072 SIGMA_4WDTriggerFrame: 7 Vector__XXX
  SG_ SIGMA_4WD : 4|29@0+ (1,0) [0|0] "" IVI
  SG_ SIGMA_DTC4WD : 39|24@0+ (1,0) [0|0] "" IVI

BO_ 2563508077 SIGMA_USMTriggerFrame: 7 Vector__XXX
  SG_ SIGMA_USM : 4|29@0+ (1,0) [0|0] "" IVI
  SG_ SIGMA_DTCUSM : 39|24@0+ (1,0) [0|0] "" IVI

BO_ 2563508078 SIGMA_SONARTriggerFrame: 7 Vector__XXX
  SG_ SIGMA_SONAR : 4|29@0+ (1,0) [0|0] "" IVI
  SG_ SIGMA_DTCSONAR : 39|24@0+ (1,0) [0|0] "" IVI

BO_ 2563508079 SIGMA_DSMUTriggerFrame: 7 Vector__XXX
  SG_ SIGMA_DSMU : 4|29@0+ (1,0) [0|0] "" IVI
  SG_ SIGMA_DTCDSMU : 39|24@0+ (1,0) [0|0] "" IVI

BO_ 2563508082 SIGMA_ACUTriggerFrame: 7 Vector__XXX
  SG_ SIGMA_ACU : 4|29@0+ (1,0) [0|0] "" IVI
  SG_ SIGMA_DTCACU : 39|24@0+ (1,0) [0|0] "" IVI

BO_ 2563508093 SIGMA_ADASTriggerFrame: 7 Vector__XXX
  SG_ SIGMA_ADAS : 4|29@0+ (1,0) [0|0] "" IVI
  SG_ SIGMA_DTCADAS : 39|24@0+ (1,0) [0|0] "" IVI

BO_ 2563508099 SIGMA_A_IVCTriggerFrame: 7 Vector__XXX
  SG_ SIGMA_A_IVC : 4|29@0+ (1,0) [0|0] "" IVI
  SG_ SIGMA_DTCA_IVC : 39|24@0+ (1,0) [0|0] "" IVI

BO_ 2563508108 SIGMA_INV_METriggerFrame: 7 Vector__XXX
  SG_ SIGMA_INV_ME : 4|29@0+ (1,0) [0|0] "" IVI
  SG_ SIGMA_DTCINV_ME : 39|24@0+ (1,0) [0|0] "" IVI

BO_ 2563508115 SIGMA_OBC_ACTriggerFrame: 7 Vector__XXX
  SG_ SIGMA_OBC_AC : 4|29@0+ (1,0) [0|0] "" IVI
  SG_ SIGMA_DTCOBC_AC : 39|24@0+ (1,0) [0|0] "" IVI

BO_ 2563508122 SIGMA_HEVCTriggerFrame: 7 Vector__XXX
  SG_ SIGMA_HEVC : 4|29@0+ (1,0) [0|0] "" IVI
  SG_ SIGMA_DTCHEVC : 39|24@0+ (1,0) [0|0] "" IVI

BO_ 2563508130 SIGMA_AUDIOampTriggerFrame: 7 Vector__XXX
  SG_ SIGMA_AUDIOamp : 4|29@0+ (1,0) [0|0] "" IVI
  SG_ SIGMA_DTCAUDIOamp : 39|24@0+ (1,0) [0|0] "" IVI

BO_ 2563508133 SIGMA_HNSTriggerFrame: 7 Vector__XXX
  SG_ SIGMA_HNS : 4|29@0+ (1,0) [0|0] "" IVI
  SG_ SIGMA_DTCHNS : 39|24@0+ (1,0) [0|0] "" IVI

BO_ 2563508153 SIGMA_HFMTriggerFrame: 7 Vector__XXX
  SG_ SIGMA_HFM : 4|29@0+ (1,0) [0|0] "" IVI
  SG_ SIGMA_DTCHFM : 39|24@0+ (1,0) [0|0] "" IVI

BO_ 2563508154 SIGMA_AVMTriggerFrame: 7 Vector__XXX
  SG_ SIGMA_AVM : 4|29@0+ (1,0) [0|0] "" IVI
  SG_ SIGMA_DTCAVM : 39|24@0+ (1,0) [0|0] "" IVI

BO_ 2563508157 SIGMA_SCUTriggerFrame: 7 Vector__XXX
  SG_ SIGMA_SCU : 4|29@0+ (1,0) [0|0] "" IVI
  SG_ SIGMA_DTCSCU : 39|24@0+ (1,0) [0|0] "" IVI

BO_ 2563508181 SIGMA_SRad_RRTriggerFrame: 7 Vector__XXX
  SG_ SIGMA_SRad_RR : 4|29@0+ (1,0) [0|0] "" IVI
  SG_ SIGMA_DTCSRad_RR : 39|24@0+ (1,0) [0|0] "" IVI

BO_ 2563508189 SIGMA_FrCameraTriggerFrame: 7 Vector__XXX
  SG_ SIGMA_FrCamera : 4|29@0+ (1,0) [0|0] "" IVI
  SG_ SIGMA_DTCFrCamera : 39|24@0+ (1,0) [0|0] "" IVI

BO_ 2563508200 SIGMA_ECMTriggerFrame: 7 Vector__XXX
  SG_ SIGMA_ECM : 4|29@0+ (1,0) [0|0] "" IVI
  SG_ SIGMA_DTCECM : 39|24@0+ (1,0) [0|0] "" IVI

BO_ 2563508201 SIGMA_ATCUTriggerFrame: 7 Vector__XXX
  SG_ SIGMA_ATCU : 4|29@0+ (1,0) [0|0] "" IVI
  SG_ SIGMA_DTCATCU : 39|24@0+ (1,0) [0|0] "" IVI

BO_ 2563508205 SIGMA_BMS_HVTriggerFrame: 7 Vector__XXX
  SG_ SIGMA_BMS_HV : 4|29@0+ (1,0) [0|0] "" IVI
  SG_ SIGMA_DTCBMS_HV : 39|24@0+ (1,0) [0|0] "" IVI

BO_ 2563508207 SIGMA_INV_HSGTriggerFrame: 7 Vector__XXX
  SG_ SIGMA_INV_HSG : 4|29@0+ (1,0) [0|0] "" IVI
  SG_ SIGMA_DTCINV_HSG : 39|24@0+ (1,0) [0|0] "" IVI

BO_ 2563567883 SIGMA_BMS_12VTriggerFrame: 7 Vector__XXX
  SG_ SIGMA_BMS_12V : 4|29@0+ (1,0) [0|0] "" IVI
  SG_ SIGMA_DTCBMS_12V : 39|24@0+ (1,0) [0|0] "" IVI

BO_ 2563567951 SIGMA_EPS_subTriggerFrame: 7 Vector__XXX
  SG_ SIGMA_EPS_sub : 4|29@0+ (1,0) [0|0] "" IVI
  SG_ SIGMA_DTCEPS_sub : 39|24@0+ (1,0) [0|0] "" IVI

BO_ 2563567968 SIGMA_HUDTriggerFrame: 7 Vector__XXX
  SG_ SIGMA_HUD : 4|29@0+ (1,0) [0|0] "" IVI
  SG_ SIGMA_DTCHUD : 39|24@0+ (1,0) [0|0] "" IVI

BO_ 2563568024 SIGMA_HPCUTriggerFrame: 7 Vector__XXX
  SG_ SIGMA_HPCU : 4|29@0+ (1,0) [0|0] "" IVI
  SG_ SIGMA_DTCHPCU : 39|24@0+ (1,0) [0|0] "" IVI

BO_ 2563568093 SIGMA_DCDC_HVTriggerFrame: 7 Vector__XXX
  SG_ SIGMA_DCDC_HV : 4|29@0+ (1,0) [0|0] "" IVI
  SG_ SIGMA_DTCDCDC_HV : 39|24@0+ (1,0) [0|0] "" IVI

BO_ 2563568098 SIGMA_EBATriggerFrame: 7 Vector__XXX
  SG_ SIGMA_EBA : 4|29@0+ (1,0) [0|0] "" IVI
  SG_ SIGMA_DTCEBA : 39|24@0+ (1,0) [0|0] "" IVI

BO_ 2563568101 SIGMA_INV_RETriggerFrame: 7 Vector__XXX
  SG_ SIGMA_INV_RE : 4|29@0+ (1,0) [0|0] "" IVI
  SG_ SIGMA_DTCINV_RE : 39|24@0+ (1,0) [0|0] "" IVI

BO_ 2563568148 SIGMA_BSGTriggerFrame: 7 Vector__XXX
  SG_ SIGMA_BSG : 4|29@0+ (1,0) [0|0] "" IVI
  SG_ SIGMA_DTCBSG : 39|24@0+ (1,0) [0|0] "" IVI

BO_ 2563568163 SIGMA_SRad_FL_TriggerFrame: 7 Vector__XXX
  SG_ SIGMA_SRad_FL : 4|29@0+ (1,0) [0|0] "" IVI
  SG_ SIGMA_DTCSRad_FL : 39|24@0+ (1,0) [0|0] "" IVI

BO_ 2563568164 SIGMA_SRad_FRTriggerFrame: 7 Vector__XXX
  SG_ SIGMA_SRad_FR : 4|29@0+ (1,0) [0|0] "" IVI
  SG_ SIGMA_DTCSRad_FR : 39|24@0+ (1,0) [0|0] "" IVI

BO_ 2563568233 SIGMA_DMCTriggerFrame: 7 Vector__XXX
  SG_ SIGMA_DMC : 4|29@0+ (1,0) [0|0] "" IVI
  SG_ SIGMA_DTCDMC : 39|24@0+ (1,0) [0|0] "" IVI

BO_ 2563568236 SIGMA_SRVMTriggerFrame: 7 Vector__XXX
  SG_ SIGMA_SRVM : 4|29@0+ (1,0) [0|0] "" IVI
  SG_ SIGMA_DTCSRVM : 39|24@0+ (1,0) [0|0] "" IVI

BO_ 2563568288 SIGMA_BLM_RPKTriggerFrame: 7 Vector__XXX
  SG_ SIGMA_BLM_RPK : 4|29@0+ (1,0) [0|0] "" IVI
  SG_ SIGMA_DTCBLM_RPK : 39|24@0+ (1,0) [0|0] "" IVI

BO_ 2563568290 SIGMA_SCCMTriggerFrame: 7 Vector__XXX
  SG_ SIGMA_SCCM : 4|29@0+ (1,0) [0|0] "" IVI
  SG_ SIGMA_DTCSCCM : 39|24@0+ (1,0) [0|0] "" IVI

BO_ 2609102848 CGW_WakeUpFrame_extd: 2 Vector__XXX
  SG_ CGW_WakeUp_Signal : 7|16@0+ (1,0) [0|0] "" IVI

BO_ 2615050482 FTOOLS_IVCtoSWMC: 8 Vector__XXX
  SG_ FTOOLS_IVCtoSWMC : 7|64@0+ (1,0) [0|0] "" IVI

BO_ 2615070962 FTOOLS_SWMCtoCGW: 8 IVI
  SG_ FTOOLS_SWMCtoCGW : 7|64@0+ (1,0) [0|0] "" Vector__XXX

BO_ 2615079552 FTOOLS_SWMCtoIVC: 8 IVI
  SG_ FTOOLS_SWMCtoIVC : 7|64@0+ (1,0) [0|0] "" Vector__XXX

BO_ 2615079632 FTOOLS_CGWtoSWMC: 8 Vector__XXX
  SG_ FTOOLS_CGWtoSWMC : 7|64@0+ (1,0) [0|0] "" IVI

BA_DEF_ BO_  "CANFD_BRS" ENUM "0","1";
BA_DEF_ BO_  "GenMsgSendType" STRING;
BA_DEF_ SG_  "Unavailable_Value" STRING;
BA_DEF_ BO_  "VFrameFormat" ENUM "StandardCAN","ExtendedCAN","reserved","reserved","reserved","reserved","reserved","reserved","reserved","reserved","reserved","reserved","reserved","reserved","StandardCAN_FD","ExtendedCAN_FD";
BA_DEF_ BO_  "GenMsgCycleTime" INT 0 50000;
BA_DEF_ BO_  "Exclusion_time" INT 0 50000;
BA_DEF_ SG_  "Event" STRING;
BA_DEF_ BO_  "Optional_Frame" STRING;

BA_DEF_DEF_  "CANFD_BRS" "0";
BA_DEF_DEF_  "Event" "false";
BA_DEF_DEF_  "GenMsgCycleTime" 0;
BA_DEF_DEF_  "Optional_Frame" "false";
BA_DEF_DEF_  "VFrameFormat" "StandardCAN";
BA_ "Exclusion_time" BO_ 1629 20;
BA_ "GenMsgCycleTime" BO_ 1629 500;
BA_ "GenMsgSendType" BO_ 1629 "Periodic and Event";
BA_ "Exclusion_time" BO_ 1630 20;
BA_ "GenMsgCycleTime" BO_ 1630 500;
BA_ "GenMsgSendType" BO_ 1630 "Periodic and Event";
BA_ "Exclusion_time" BO_ 1634 100;
BA_ "GenMsgCycleTime" BO_ 1634 500;
BA_ "GenMsgSendType" BO_ 1634 "Periodic and Event";
BA_ "Exclusion_time" BO_ 1636 100;
BA_ "GenMsgCycleTime" BO_ 1636 1000;
BA_ "GenMsgSendType" BO_ 1636 "Periodic and Event";
BA_ "Exclusion_time" BO_ 1637 20;
BA_ "GenMsgCycleTime" BO_ 1637 1000;
BA_ "GenMsgSendType" BO_ 1637 "Periodic and Event";
BA_ "Exclusion_time" BO_ 1639 100;
BA_ "GenMsgCycleTime" BO_ 1639 1000;
BA_ "GenMsgSendType" BO_ 1639 "Periodic and Event";
BA_ "Exclusion_time" BO_ 1640 100;
BA_ "GenMsgCycleTime" BO_ 1640 1000;
BA_ "GenMsgSendType" BO_ 1640 "Periodic and Event";
BA_ "Exclusion_time" BO_ 1645 20;
BA_ "GenMsgCycleTime" BO_ 1645 1000;
BA_ "GenMsgSendType" BO_ 1645 "Periodic and Event";
BA_ "Exclusion_time" BO_ 1658 20;
BA_ "GenMsgCycleTime" BO_ 1658 500;
BA_ "GenMsgSendType" BO_ 1658 "Periodic and Event";
BA_ "Exclusion_time" BO_ 1659 20;
BA_ "GenMsgCycleTime" BO_ 1659 1000;
BA_ "GenMsgSendType" BO_ 1659 "Periodic and Event";
BA_ "Exclusion_time" BO_ 1660 50;
BA_ "GenMsgCycleTime" BO_ 1660 1000;
BA_ "GenMsgSendType" BO_ 1660 "Periodic and Event";
BA_ "Exclusion_time" BO_ 1661 20;
BA_ "GenMsgCycleTime" BO_ 1661 1000;
BA_ "GenMsgSendType" BO_ 1661 "Periodic and Event";
BA_ "Exclusion_time" BO_ 1662 50;
BA_ "GenMsgCycleTime" BO_ 1662 1000;
BA_ "GenMsgSendType" BO_ 1662 "Periodic and Event";
BA_ "GenMsgCycleTime" BO_ 1677 500;
BA_ "GenMsgSendType" BO_ 1677 "Periodic";
BA_ "Exclusion_time" BO_ 1681 20;
BA_ "GenMsgCycleTime" BO_ 1681 500;
BA_ "GenMsgSendType" BO_ 1681 "Periodic and Event";
BA_ "Exclusion_time" BO_ 1682 100;
BA_ "GenMsgCycleTime" BO_ 1682 1000;
BA_ "GenMsgSendType" BO_ 1682 "Periodic and Event";
BA_ "Exclusion_time" BO_ 1684 100;
BA_ "GenMsgCycleTime" BO_ 1684 3000;
BA_ "GenMsgSendType" BO_ 1684 "Periodic and Event";
BA_ "Exclusion_time" BO_ 1685 100;
BA_ "GenMsgCycleTime" BO_ 1685 500;
BA_ "GenMsgSendType" BO_ 1685 "Periodic and Event";
BA_ "GenMsgCycleTime" BO_ 1690 500;
BA_ "GenMsgSendType" BO_ 1690 "Periodic";
BA_ "GenMsgCycleTime" BO_ 1695 1000;
BA_ "GenMsgSendType" BO_ 1695 "Periodic";
BA_ "GenMsgCycleTime" BO_ 1697 3000;
BA_ "GenMsgSendType" BO_ 1697 "Periodic";
BA_ "Exclusion_time" BO_ 1703 100;
BA_ "GenMsgCycleTime" BO_ 1703 3000;
BA_ "GenMsgSendType" BO_ 1703 "Periodic and Event";
BA_ "Exclusion_time" BO_ 1724 100;
BA_ "GenMsgCycleTime" BO_ 1724 3000;
BA_ "GenMsgSendType" BO_ 1724 "Periodic and Event";
BA_ "Exclusion_time" BO_ 1742 20;
BA_ "GenMsgCycleTime" BO_ 1742 3000;
BA_ "GenMsgSendType" BO_ 1742 "Periodic and Event";
BA_ "Exclusion_time" BO_ 1755 100;
BA_ "GenMsgCycleTime" BO_ 1755 3000;
BA_ "GenMsgSendType" BO_ 1755 "Periodic and Event";
BA_ "Exclusion_time" BO_ 1779 100;
BA_ "GenMsgCycleTime" BO_ 1779 3000;
BA_ "GenMsgSendType" BO_ 1779 "Periodic and Event";
BA_ "Exclusion_time" BO_ 1780 100;
BA_ "GenMsgCycleTime" BO_ 1780 3000;
BA_ "GenMsgSendType" BO_ 1780 "Periodic and Event";
BA_ "Exclusion_time" BO_ 1781 100;
BA_ "GenMsgCycleTime" BO_ 1781 3000;
BA_ "GenMsgSendType" BO_ 1781 "Periodic and Event";
BA_ "Exclusion_time" BO_ 1782 100;
BA_ "GenMsgCycleTime" BO_ 1782 3000;
BA_ "GenMsgSendType" BO_ 1782 "Periodic and Event";
BA_ "Exclusion_time" BO_ 1783 100;
BA_ "GenMsgCycleTime" BO_ 1783 3000;
BA_ "GenMsgSendType" BO_ 1783 "Periodic and Event";
BA_ "Exclusion_time" BO_ 1789 100;
BA_ "GenMsgCycleTime" BO_ 1789 3000;
BA_ "GenMsgSendType" BO_ 1789 "Periodic and Event";
BA_ "Exclusion_time" BO_ 1790 10;
BA_ "GenMsgCycleTime" BO_ 1790 3000;
BA_ "GenMsgSendType" BO_ 1790 "Periodic and Event";
BA_ "Exclusion_time" BO_ 1791 100;
BA_ "GenMsgCycleTime" BO_ 1791 3000;
BA_ "GenMsgSendType" BO_ 1791 "Periodic and Event";
BA_ "GenMsgSendType" BO_ 1812 "Diagnostic";
BA_ "GenMsgSendType" BO_ 1844 "Diagnostic";
BA_ "GenMsgSendType" BO_ 1863 "Diagnostic";
BA_ "GenMsgSendType" BO_ 1895 "Diagnostic";
BA_ "GenMsgSendType" BO_ 2563507968 "Event";
BA_ "VFrameFormat" BO_ 2563507968 1;
BA_ "GenMsgSendType" BO_ 2563508019 "Event";
BA_ "VFrameFormat" BO_ 2563508019 1;
BA_ "GenMsgSendType" BO_ 2563508021 "Event";
BA_ "VFrameFormat" BO_ 2563508021 1;
BA_ "GenMsgSendType" BO_ 2563508022 "Event";
BA_ "VFrameFormat" BO_ 2563508022 1;
BA_ "GenMsgSendType" BO_ 2563508030 "Event";
BA_ "VFrameFormat" BO_ 2563508030 1;
BA_ "GenMsgSendType" BO_ 2563508042 "Event";
BA_ "VFrameFormat" BO_ 2563508042 1;
BA_ "GenMsgSendType" BO_ 2563508064 "Event";
BA_ "VFrameFormat" BO_ 2563508064 1;
BA_ "GenMsgSendType" BO_ 2563508066 "Event";
BA_ "VFrameFormat" BO_ 2563508066 1;
BA_ "GenMsgSendType" BO_ 2563508067 "Event";
BA_ "VFrameFormat" BO_ 2563508067 1;
BA_ "GenMsgSendType" BO_ 2563508068 "Event";
BA_ "GenMsgSendType" BO_ 2563508069 "Event";
BA_ "VFrameFormat" BO_ 2563508069 1;
BA_ "GenMsgSendType" BO_ 2563508071 "Event";
BA_ "VFrameFormat" BO_ 2563508071 1;
BA_ "GenMsgSendType" BO_ 2563508072 "Event";
BA_ "GenMsgSendType" BO_ 2563508077 "Event";
BA_ "VFrameFormat" BO_ 2563508077 1;
BA_ "GenMsgSendType" BO_ 2563508078 "Event";
BA_ "GenMsgSendType" BO_ 2563508079 "Event";
BA_ "VFrameFormat" BO_ 2563508079 1;
BA_ "GenMsgSendType" BO_ 2563508082 "Event";
BA_ "VFrameFormat" BO_ 2563508082 1;
BA_ "GenMsgSendType" BO_ 2563508093 "Event";
BA_ "VFrameFormat" BO_ 2563508093 1;
BA_ "GenMsgSendType" BO_ 2563508099 "Event";
BA_ "VFrameFormat" BO_ 2563508099 1;
BA_ "GenMsgSendType" BO_ 2563508108 "Event";
BA_ "GenMsgSendType" BO_ 2563508115 "Event";
BA_ "GenMsgSendType" BO_ 2563508122 "Event";
BA_ "GenMsgSendType" BO_ 2563508130 "Event";
BA_ "VFrameFormat" BO_ 2563508130 1;
BA_ "GenMsgSendType" BO_ 2563508133 "Event";
BA_ "GenMsgSendType" BO_ 2563508153 "Event";
BA_ "VFrameFormat" BO_ 2563508153 1;
BA_ "GenMsgSendType" BO_ 2563508154 "Event";
BA_ "GenMsgSendType" BO_ 2563508157 "Event";
BA_ "GenMsgSendType" BO_ 2563508181 "Event";
BA_ "VFrameFormat" BO_ 2563508181 1;
BA_ "GenMsgSendType" BO_ 2563508189 "Event";
BA_ "VFrameFormat" BO_ 2563508189 1;
BA_ "GenMsgSendType" BO_ 2563508200 "Event";
BA_ "VFrameFormat" BO_ 2563508200 1;
BA_ "GenMsgSendType" BO_ 2563508201 "Event";
BA_ "VFrameFormat" BO_ 2563508201 1;
BA_ "GenMsgSendType" BO_ 2563508205 "Event";
BA_ "GenMsgSendType" BO_ 2563508207 "Event";
BA_ "GenMsgSendType" BO_ 2563567883 "Event";
BA_ "VFrameFormat" BO_ 2563567883 1;
BA_ "GenMsgSendType" BO_ 2563567951 "Event";
BA_ "GenMsgSendType" BO_ 2563567968 "Event";
BA_ "GenMsgSendType" BO_ 2563568024 "Event";
BA_ "GenMsgSendType" BO_ 2563568093 "Event";
BA_ "GenMsgSendType" BO_ 2563568098 "Event";
BA_ "VFrameFormat" BO_ 2563568098 1;
BA_ "GenMsgSendType" BO_ 2563568101 "Event";
BA_ "GenMsgSendType" BO_ 2563568148 "Event";
BA_ "GenMsgSendType" BO_ 2563568163 "Event";
BA_ "VFrameFormat" BO_ 2563568163 1;
BA_ "GenMsgSendType" BO_ 2563568164 "Event";
BA_ "VFrameFormat" BO_ 2563568164 1;
BA_ "GenMsgSendType" BO_ 2563568233 "Event";
BA_ "GenMsgSendType" BO_ 2563568236 "Event";
BA_ "VFrameFormat" BO_ 2563568236 1;
BA_ "GenMsgSendType" BO_ 2563568288 "Event";
BA_ "GenMsgSendType" BO_ 2563568290 "Event";
BA_ "VFrameFormat" BO_ 2563568290 1;
BA_ "GenMsgSendType" BO_ 2609102848 "Event";
BA_ "VFrameFormat" BO_ 2609102848 1;
BA_ "Exclusion_time" BO_ 2615050482 10;
BA_ "GenMsgSendType" BO_ 2615050482 "Event";
BA_ "VFrameFormat" BO_ 2615050482 1;
BA_ "Exclusion_time" BO_ 2615070962 10;
BA_ "GenMsgSendType" BO_ 2615070962 "Event";
BA_ "VFrameFormat" BO_ 2615070962 1;
BA_ "Exclusion_time" BO_ 2615079552 10;
BA_ "GenMsgSendType" BO_ 2615079552 "Event";
BA_ "VFrameFormat" BO_ 2615079552 1;
BA_ "Exclusion_time" BO_ 2615079632 10;
BA_ "GenMsgSendType" BO_ 2615079632 "Event";
BA_ "VFrameFormat" BO_ 2615079632 1;
BA_ "Event" SG_ 1629 FAP_ChangeViewRequest "true";
BA_ "Event" SG_ 1629 FAP_ChangeViewRequest "true";
BA_ "Event" SG_ 1629 FAP_ChangeViewRequest "true";
BA_ "Event" SG_ 1629 FAP_ChangeViewRequest "true";
BA_ "Unavailable_Value" SG_ 1629 FAP_ChangeViewRequest "0b0";
BA_ "Event" SG_ 1629 FAP_FramePattern "true";
BA_ "Event" SG_ 1629 FAP_FramePattern "true";
BA_ "Event" SG_ 1629 FAP_FramePattern "true";
BA_ "Event" SG_ 1629 FAP_FramePattern "true";
BA_ "Unavailable_Value" SG_ 1629 FAP_FramePattern "0x00";
BA_ "Event" SG_ 1629 FAP_SwitchGrayOutRequest02 "true";
BA_ "Event" SG_ 1629 FAP_SwitchGrayOutRequest02 "true";
BA_ "Event" SG_ 1629 FAP_SwitchGrayOutRequest02 "true";
BA_ "Event" SG_ 1629 FAP_SwitchGrayOutRequest02 "true";
BA_ "Unavailable_Value" SG_ 1629 FAP_SwitchGrayOutRequest02 "0b0";
BA_ "Event" SG_ 1629 FAP_SwitchGrayOutRequest01 "true";
BA_ "Event" SG_ 1629 FAP_SwitchGrayOutRequest01 "true";
BA_ "Event" SG_ 1629 FAP_SwitchGrayOutRequest01 "true";
BA_ "Event" SG_ 1629 FAP_SwitchGrayOutRequest01 "true";
BA_ "Unavailable_Value" SG_ 1629 FAP_SwitchGrayOutRequest01 "0b0";
BA_ "Event" SG_ 1629 FAP_GuideDisplayRequest "true";
BA_ "Event" SG_ 1629 FAP_GuideDisplayRequest "true";
BA_ "Event" SG_ 1629 FAP_GuideDisplayRequest "true";
BA_ "Event" SG_ 1629 FAP_GuideDisplayRequest "true";
BA_ "Unavailable_Value" SG_ 1629 FAP_GuideDisplayRequest "0x00";
BA_ "Event" SG_ 1629 FAP_SwitchGrayOutRequest04 "true";
BA_ "Event" SG_ 1629 FAP_SwitchGrayOutRequest04 "true";
BA_ "Event" SG_ 1629 FAP_SwitchGrayOutRequest04 "true";
BA_ "Event" SG_ 1629 FAP_SwitchGrayOutRequest04 "true";
BA_ "Unavailable_Value" SG_ 1629 FAP_SwitchGrayOutRequest04 "0b0";
BA_ "Event" SG_ 1629 FAP_SwitchGrayOutRequest03 "true";
BA_ "Event" SG_ 1629 FAP_SwitchGrayOutRequest03 "true";
BA_ "Event" SG_ 1629 FAP_SwitchGrayOutRequest03 "true";
BA_ "Event" SG_ 1629 FAP_SwitchGrayOutRequest03 "true";
BA_ "Unavailable_Value" SG_ 1629 FAP_SwitchGrayOutRequest03 "0b0";
BA_ "Event" SG_ 1629 FAP_MessageDisplayRequest "true";
BA_ "Event" SG_ 1629 FAP_MessageDisplayRequest "true";
BA_ "Event" SG_ 1629 FAP_MessageDisplayRequest "true";
BA_ "Event" SG_ 1629 FAP_MessageDisplayRequest "true";
BA_ "Unavailable_Value" SG_ 1629 FAP_MessageDisplayRequest "0x00";
BA_ "Event" SG_ 1629 FAP_SwitchGrayOutRequest06 "true";
BA_ "Event" SG_ 1629 FAP_SwitchGrayOutRequest06 "true";
BA_ "Event" SG_ 1629 FAP_SwitchGrayOutRequest06 "true";
BA_ "Event" SG_ 1629 FAP_SwitchGrayOutRequest06 "true";
BA_ "Unavailable_Value" SG_ 1629 FAP_SwitchGrayOutRequest06 "0b0";
BA_ "Event" SG_ 1629 FAP_SwitchGrayOutRequest05 "true";
BA_ "Event" SG_ 1629 FAP_SwitchGrayOutRequest05 "true";
BA_ "Event" SG_ 1629 FAP_SwitchGrayOutRequest05 "true";
BA_ "Event" SG_ 1629 FAP_SwitchGrayOutRequest05 "true";
BA_ "Unavailable_Value" SG_ 1629 FAP_SwitchGrayOutRequest05 "0b0";
BA_ "Event" SG_ 1629 FAP_ParkingTypeRequest "true";
BA_ "Event" SG_ 1629 FAP_ParkingTypeRequest "true";
BA_ "Event" SG_ 1629 FAP_ParkingTypeRequest "true";
BA_ "Event" SG_ 1629 FAP_ParkingTypeRequest "true";
BA_ "Unavailable_Value" SG_ 1629 FAP_ParkingTypeRequest "0x00";
BA_ "Event" SG_ 1629 FAP_SwitchGrayOutRequest08 "true";
BA_ "Event" SG_ 1629 FAP_SwitchGrayOutRequest08 "true";
BA_ "Event" SG_ 1629 FAP_SwitchGrayOutRequest08 "true";
BA_ "Event" SG_ 1629 FAP_SwitchGrayOutRequest08 "true";
BA_ "Unavailable_Value" SG_ 1629 FAP_SwitchGrayOutRequest08 "0b0";
BA_ "Event" SG_ 1629 FAP_SwitchGrayOutRequest07 "true";
BA_ "Event" SG_ 1629 FAP_SwitchGrayOutRequest07 "true";
BA_ "Event" SG_ 1629 FAP_SwitchGrayOutRequest07 "true";
BA_ "Event" SG_ 1629 FAP_SwitchGrayOutRequest07 "true";
BA_ "Unavailable_Value" SG_ 1629 FAP_SwitchGrayOutRequest07 "0b0";
BA_ "Event" SG_ 1629 FAP_PopupDisplayRequest "true";
BA_ "Event" SG_ 1629 FAP_PopupDisplayRequest "true";
BA_ "Event" SG_ 1629 FAP_PopupDisplayRequest "true";
BA_ "Event" SG_ 1629 FAP_PopupDisplayRequest "true";
BA_ "Unavailable_Value" SG_ 1629 FAP_PopupDisplayRequest "0x00";
BA_ "Event" SG_ 1629 FAP_SwitchGrayOutRequest12 "true";
BA_ "Event" SG_ 1629 FAP_SwitchGrayOutRequest12 "true";
BA_ "Event" SG_ 1629 FAP_SwitchGrayOutRequest12 "true";
BA_ "Event" SG_ 1629 FAP_SwitchGrayOutRequest12 "true";
BA_ "Unavailable_Value" SG_ 1629 FAP_SwitchGrayOutRequest12 "0b0";
BA_ "Event" SG_ 1629 FAP_SwitchGrayOutRequest11 "true";
BA_ "Event" SG_ 1629 FAP_SwitchGrayOutRequest11 "true";
BA_ "Event" SG_ 1629 FAP_SwitchGrayOutRequest11 "true";
BA_ "Event" SG_ 1629 FAP_SwitchGrayOutRequest11 "true";
BA_ "Unavailable_Value" SG_ 1629 FAP_SwitchGrayOutRequest11 "0b0";
BA_ "Event" SG_ 1629 FAP_SwitchGrayOutRequest10 "true";
BA_ "Event" SG_ 1629 FAP_SwitchGrayOutRequest10 "true";
BA_ "Event" SG_ 1629 FAP_SwitchGrayOutRequest10 "true";
BA_ "Event" SG_ 1629 FAP_SwitchGrayOutRequest10 "true";
BA_ "Unavailable_Value" SG_ 1629 FAP_SwitchGrayOutRequest10 "0b0";
BA_ "Event" SG_ 1629 FAP_SwitchGrayOutRequest09 "true";
BA_ "Event" SG_ 1629 FAP_SwitchGrayOutRequest09 "true";
BA_ "Event" SG_ 1629 FAP_SwitchGrayOutRequest09 "true";
BA_ "Event" SG_ 1629 FAP_SwitchGrayOutRequest09 "true";
BA_ "Unavailable_Value" SG_ 1629 FAP_SwitchGrayOutRequest09 "0b0";
BA_ "Event" SG_ 1629 FAP_CameraIndicatorRequest "true";
BA_ "Event" SG_ 1629 FAP_CameraIndicatorRequest "true";
BA_ "Event" SG_ 1629 FAP_CameraIndicatorRequest "true";
BA_ "Event" SG_ 1629 FAP_CameraIndicatorRequest "true";
BA_ "Unavailable_Value" SG_ 1629 FAP_CameraIndicatorRequest "0b000";
BA_ "Event" SG_ 1630 FAP_SoundLevelControl "true";
BA_ "Event" SG_ 1630 FAP_SoundLevelControl "true";
BA_ "Event" SG_ 1630 FAP_SoundLevelControl "true";
BA_ "Event" SG_ 1630 FAP_SoundLevelControl "true";
BA_ "Unavailable_Value" SG_ 1630 FAP_SoundLevelControl "0b00";
BA_ "Event" SG_ 1630 FAP_VoicePatternRequest "true";
BA_ "Event" SG_ 1630 FAP_VoicePatternRequest "true";
BA_ "Event" SG_ 1630 FAP_VoicePatternRequest "true";
BA_ "Event" SG_ 1630 FAP_VoicePatternRequest "true";
BA_ "Unavailable_Value" SG_ 1630 FAP_VoicePatternRequest "0x00";
BA_ "Event" SG_ 1630 FAP_SoundPatternRequest "true";
BA_ "Event" SG_ 1630 FAP_SoundPatternRequest "true";
BA_ "Event" SG_ 1630 FAP_SoundPatternRequest "true";
BA_ "Event" SG_ 1630 FAP_SoundPatternRequest "true";
BA_ "Unavailable_Value" SG_ 1630 FAP_SoundPatternRequest "0x0";
BA_ "Event" SG_ 1630 FAP_SoundDirection "true";
BA_ "Event" SG_ 1630 FAP_SoundDirection "true";
BA_ "Event" SG_ 1630 FAP_SoundDirection "true";
BA_ "Event" SG_ 1630 FAP_SoundDirection "true";
BA_ "Unavailable_Value" SG_ 1630 FAP_SoundDirection "0x0";
BA_ "Event" SG_ 1630 FAP_Setting04 "true";
BA_ "Event" SG_ 1630 FAP_Setting04 "true";
BA_ "Event" SG_ 1630 FAP_Setting04 "true";
BA_ "Event" SG_ 1630 FAP_Setting04 "true";
BA_ "Unavailable_Value" SG_ 1630 FAP_Setting04 "0b00";
BA_ "Event" SG_ 1630 FAP_Setting03 "true";
BA_ "Event" SG_ 1630 FAP_Setting03 "true";
BA_ "Event" SG_ 1630 FAP_Setting03 "true";
BA_ "Event" SG_ 1630 FAP_Setting03 "true";
BA_ "Unavailable_Value" SG_ 1630 FAP_Setting03 "0b00";
BA_ "Event" SG_ 1630 FAP_Setting02 "true";
BA_ "Event" SG_ 1630 FAP_Setting02 "true";
BA_ "Event" SG_ 1630 FAP_Setting02 "true";
BA_ "Event" SG_ 1630 FAP_Setting02 "true";
BA_ "Unavailable_Value" SG_ 1630 FAP_Setting02 "0b00";
BA_ "Event" SG_ 1630 FAP_Setting01 "true";
BA_ "Event" SG_ 1630 FAP_Setting01 "true";
BA_ "Event" SG_ 1630 FAP_Setting01 "true";
BA_ "Event" SG_ 1630 FAP_Setting01 "true";
BA_ "Unavailable_Value" SG_ 1630 FAP_Setting01 "0b00";
BA_ "Event" SG_ 1630 FAP_Setting08 "true";
BA_ "Event" SG_ 1630 FAP_Setting08 "true";
BA_ "Event" SG_ 1630 FAP_Setting08 "true";
BA_ "Event" SG_ 1630 FAP_Setting08 "true";
BA_ "Unavailable_Value" SG_ 1630 FAP_Setting08 "0b00";
BA_ "Event" SG_ 1630 FAP_Setting07 "true";
BA_ "Event" SG_ 1630 FAP_Setting07 "true";
BA_ "Event" SG_ 1630 FAP_Setting07 "true";
BA_ "Event" SG_ 1630 FAP_Setting07 "true";
BA_ "Unavailable_Value" SG_ 1630 FAP_Setting07 "0b00";
BA_ "Event" SG_ 1630 FAP_Setting06 "true";
BA_ "Event" SG_ 1630 FAP_Setting06 "true";
BA_ "Event" SG_ 1630 FAP_Setting06 "true";
BA_ "Event" SG_ 1630 FAP_Setting06 "true";
BA_ "Unavailable_Value" SG_ 1630 FAP_Setting06 "0b00";
BA_ "Event" SG_ 1630 FAP_Setting05 "true";
BA_ "Event" SG_ 1630 FAP_Setting05 "true";
BA_ "Event" SG_ 1630 FAP_Setting05 "true";
BA_ "Event" SG_ 1630 FAP_Setting05 "true";
BA_ "Unavailable_Value" SG_ 1630 FAP_Setting05 "0b00";
BA_ "Event" SG_ 1630 FAP_PurposeSwitchAvailability "true";
BA_ "Event" SG_ 1630 FAP_PurposeSwitchAvailability "true";
BA_ "Event" SG_ 1630 FAP_PurposeSwitchAvailability "true";
BA_ "Event" SG_ 1630 FAP_PurposeSwitchAvailability "true";
BA_ "Unavailable_Value" SG_ 1630 FAP_PurposeSwitchAvailability "0b0";
BA_ "Event" SG_ 1630 FAP_ModeChangeRequest "true";
BA_ "Event" SG_ 1630 FAP_ModeChangeRequest "true";
BA_ "Event" SG_ 1630 FAP_ModeChangeRequest "true";
BA_ "Event" SG_ 1630 FAP_ModeChangeRequest "true";
BA_ "Unavailable_Value" SG_ 1630 FAP_ModeChangeRequest "0b00";
BA_ "Event" SG_ 1630 FAP_Setting10 "true";
BA_ "Event" SG_ 1630 FAP_Setting10 "true";
BA_ "Event" SG_ 1630 FAP_Setting10 "true";
BA_ "Event" SG_ 1630 FAP_Setting10 "true";
BA_ "Unavailable_Value" SG_ 1630 FAP_Setting10 "0b00";
BA_ "Event" SG_ 1630 FAP_Setting09 "true";
BA_ "Event" SG_ 1630 FAP_Setting09 "true";
BA_ "Event" SG_ 1630 FAP_Setting09 "true";
BA_ "Event" SG_ 1630 FAP_Setting09 "true";
BA_ "Unavailable_Value" SG_ 1630 FAP_Setting09 "0b00";
BA_ "Event" SG_ 1634 LateralTilt_MMI "true";
BA_ "Event" SG_ 1634 LateralTilt_MMI "true";
BA_ "Event" SG_ 1634 LateralTilt_MMI "true";
BA_ "Event" SG_ 1634 LateralTilt_MMI "true";
BA_ "Unavailable_Value" SG_ 1634 LateralTilt_MMI "0x7F";
BA_ "Event" SG_ 1634 LongitudinalTilt_MMI "true";
BA_ "Event" SG_ 1634 LongitudinalTilt_MMI "true";
BA_ "Event" SG_ 1634 LongitudinalTilt_MMI "true";
BA_ "Event" SG_ 1634 LongitudinalTilt_MMI "true";
BA_ "Unavailable_Value" SG_ 1634 LongitudinalTilt_MMI "0x7F";
BA_ "Event" SG_ 1636 PBD_ActivationState "true";
BA_ "Event" SG_ 1636 PBD_ActivationState "true";
BA_ "Event" SG_ 1636 PBD_ActivationState "true";
BA_ "Event" SG_ 1636 PBD_ActivationState "true";
BA_ "Unavailable_Value" SG_ 1636 PBD_ActivationState "0b000";
BA_ "Event" SG_ 1636 PBD_ResponseState "true";
BA_ "Event" SG_ 1636 PBD_ResponseState "true";
BA_ "Event" SG_ 1636 PBD_ResponseState "true";
BA_ "Event" SG_ 1636 PBD_ResponseState "true";
BA_ "Unavailable_Value" SG_ 1636 PBD_ResponseState "0b000";
BA_ "Event" SG_ 1636 PBD_AuthorizationState "true";
BA_ "Event" SG_ 1636 PBD_AuthorizationState "true";
BA_ "Event" SG_ 1636 PBD_AuthorizationState "true";
BA_ "Event" SG_ 1636 PBD_AuthorizationState "true";
BA_ "Unavailable_Value" SG_ 1636 PBD_AuthorizationState "0b000";
BA_ "Event" SG_ 1637 SteeringSettingState_v2 "true";
BA_ "Event" SG_ 1637 SteeringSettingState_v2 "true";
BA_ "Event" SG_ 1637 SteeringSettingState_v2 "true";
BA_ "Event" SG_ 1637 SteeringSettingState_v2 "true";
BA_ "Unavailable_Value" SG_ 1637 SteeringSettingState_v2 "0b0000";
BA_ "Event" SG_ 1637 PowerTrainSettingState "true";
BA_ "Event" SG_ 1637 PowerTrainSettingState "true";
BA_ "Event" SG_ 1637 PowerTrainSettingState "true";
BA_ "Event" SG_ 1637 PowerTrainSettingState "true";
BA_ "Unavailable_Value" SG_ 1637 PowerTrainSettingState "0b0000";
BA_ "Event" SG_ 1637 AWDSettingState "true";
BA_ "Event" SG_ 1637 AWDSettingState "true";
BA_ "Event" SG_ 1637 AWDSettingState "true";
BA_ "Event" SG_ 1637 AWDSettingState "true";
BA_ "Unavailable_Value" SG_ 1637 AWDSettingState "0b000";
BA_ "Event" SG_ 1637 SuspensionSettingState "true";
BA_ "Event" SG_ 1637 SuspensionSettingState "true";
BA_ "Event" SG_ 1637 SuspensionSettingState "true";
BA_ "Event" SG_ 1637 SuspensionSettingState "true";
BA_ "Unavailable_Value" SG_ 1637 SuspensionSettingState "0b000";
BA_ "Event" SG_ 1637 DriveModeState "true";
BA_ "Event" SG_ 1637 DriveModeState "true";
BA_ "Event" SG_ 1637 DriveModeState "true";
BA_ "Event" SG_ 1637 DriveModeState "true";
BA_ "Unavailable_Value" SG_ 1637 DriveModeState "0x1F";
BA_ "Event" SG_ 1639 AllRouteSegmentsRequest "true";
BA_ "Event" SG_ 1639 AllRouteSegmentsRequest "true";
BA_ "Event" SG_ 1639 AllRouteSegmentsRequest "true";
BA_ "Event" SG_ 1639 AllRouteSegmentsRequest "true";
BA_ "Unavailable_Value" SG_ 1639 AllRouteSegmentsRequest "0b0";
BA_ "Unavailable_Value" SG_ 1640 ChargeSpotPowerLevel "0x1FF";
BA_ "Event" SG_ 1640 SCdurabilityInhibition "true";
BA_ "Event" SG_ 1640 SCdurabilityInhibition "true";
BA_ "Event" SG_ 1640 SCdurabilityInhibition "true";
BA_ "Event" SG_ 1640 SCdurabilityInhibition "true";
BA_ "Unavailable_Value" SG_ 1640 SCdurabilityInhibition "0b0";
BA_ "Event" SG_ 1645 AEB_FCWactivationState2 "true";
BA_ "Event" SG_ 1645 AEB_FCWactivationState2 "true";
BA_ "Event" SG_ 1645 AEB_FCWactivationState2 "true";
BA_ "Event" SG_ 1645 AEB_FCWactivationState2 "true";
BA_ "Unavailable_Value" SG_ 1645 AEB_FCWactivationState2 "0b00";
BA_ "Event" SG_ 1645 AEB_CyclistAlertRequest2 "true";
BA_ "Event" SG_ 1645 AEB_CyclistAlertRequest2 "true";
BA_ "Event" SG_ 1645 AEB_CyclistAlertRequest2 "true";
BA_ "Event" SG_ 1645 AEB_CyclistAlertRequest2 "true";
BA_ "Unavailable_Value" SG_ 1645 AEB_CyclistAlertRequest2 "0b0";
BA_ "Event" SG_ 1645 AEB_PedestrianAlertRequest2 "true";
BA_ "Event" SG_ 1645 AEB_PedestrianAlertRequest2 "true";
BA_ "Event" SG_ 1645 AEB_PedestrianAlertRequest2 "true";
BA_ "Event" SG_ 1645 AEB_PedestrianAlertRequest2 "true";
BA_ "Unavailable_Value" SG_ 1645 AEB_PedestrianAlertRequest2 "0b0";
BA_ "Event" SG_ 1645 AEB_VehicleAlertRequest2 "true";
BA_ "Event" SG_ 1645 AEB_VehicleAlertRequest2 "true";
BA_ "Event" SG_ 1645 AEB_VehicleAlertRequest2 "true";
BA_ "Event" SG_ 1645 AEB_VehicleAlertRequest2 "true";
BA_ "Unavailable_Value" SG_ 1645 AEB_VehicleAlertRequest2 "0b00";
BA_ "Event" SG_ 1645 DW_ActivationState_TM "true";
BA_ "Event" SG_ 1645 DW_ActivationState_TM "true";
BA_ "Event" SG_ 1645 DW_ActivationState_TM "true";
BA_ "Event" SG_ 1645 DW_ActivationState_TM "true";
BA_ "Unavailable_Value" SG_ 1645 DW_ActivationState_TM "0b0";
BA_ "Event" SG_ 1645 FCW_SensibilityState "true";
BA_ "Event" SG_ 1645 FCW_SensibilityState "true";
BA_ "Event" SG_ 1645 FCW_SensibilityState "true";
BA_ "Event" SG_ 1645 FCW_SensibilityState "true";
BA_ "Unavailable_Value" SG_ 1645 FCW_SensibilityState "0b00";
BA_ "Event" SG_ 1658 FAP_ScreenPressCoordinateX "true";
BA_ "Event" SG_ 1658 FAP_ScreenPressCoordinateX "true";
BA_ "Event" SG_ 1658 FAP_ScreenPressCoordinateX "true";
BA_ "Event" SG_ 1658 FAP_ScreenPressCoordinateX "true";
BA_ "Unavailable_Value" SG_ 1658 FAP_ScreenPressCoordinateX "0xFF";
BA_ "Event" SG_ 1658 FAP_ScreenPressCoordinateY "true";
BA_ "Event" SG_ 1658 FAP_ScreenPressCoordinateY "true";
BA_ "Event" SG_ 1658 FAP_ScreenPressCoordinateY "true";
BA_ "Event" SG_ 1658 FAP_ScreenPressCoordinateY "true";
BA_ "Unavailable_Value" SG_ 1658 FAP_ScreenPressCoordinateY "0xFF";
BA_ "Event" SG_ 1658 FAP_ScreenPressDetected "true";
BA_ "Event" SG_ 1658 FAP_ScreenPressDetected "true";
BA_ "Event" SG_ 1658 FAP_ScreenPressDetected "true";
BA_ "Event" SG_ 1658 FAP_ScreenPressDetected "true";
BA_ "Unavailable_Value" SG_ 1658 FAP_ScreenPressDetected "0b00";
BA_ "Unavailable_Value" SG_ 1658 FAP_SetLanguage "Not applicable";
BA_ "Event" SG_ 1658 FAP_SwitchLongPressDetected "true";
BA_ "Event" SG_ 1658 FAP_SwitchLongPressDetected "true";
BA_ "Event" SG_ 1658 FAP_SwitchLongPressDetected "true";
BA_ "Event" SG_ 1658 FAP_SwitchLongPressDetected "true";
BA_ "Unavailable_Value" SG_ 1658 FAP_SwitchLongPressDetected "0b0";
BA_ "Event" SG_ 1658 FAP_SwitchOperationStatus "true";
BA_ "Event" SG_ 1658 FAP_SwitchOperationStatus "true";
BA_ "Event" SG_ 1658 FAP_SwitchOperationStatus "true";
BA_ "Event" SG_ 1658 FAP_SwitchOperationStatus "true";
BA_ "Unavailable_Value" SG_ 1658 FAP_SwitchOperationStatus "0x00";
BA_ "Event" SG_ 1658 FAP_ActivationRequest "true";
BA_ "Event" SG_ 1658 FAP_ActivationRequest "true";
BA_ "Event" SG_ 1658 FAP_ActivationRequest "true";
BA_ "Event" SG_ 1658 FAP_ActivationRequest "true";
BA_ "Unavailable_Value" SG_ 1658 FAP_ActivationRequest "0b0";
BA_ "Event" SG_ 1658 FAP_HMIavailability "true";
BA_ "Event" SG_ 1658 FAP_HMIavailability "true";
BA_ "Event" SG_ 1658 FAP_HMIavailability "true";
BA_ "Event" SG_ 1658 FAP_HMIavailability "true";
BA_ "Unavailable_Value" SG_ 1658 FAP_HMIavailability "0b00";
BA_ "Event" SG_ 1658 FAP_VoiceStatus "true";
BA_ "Event" SG_ 1658 FAP_VoiceStatus "true";
BA_ "Event" SG_ 1658 FAP_VoiceStatus "true";
BA_ "Event" SG_ 1658 FAP_VoiceStatus "true";
BA_ "Unavailable_Value" SG_ 1658 FAP_VoiceStatus "0b00";
BA_ "Event" SG_ 1659 UserIdentification_IKeyLink "true";
BA_ "Event" SG_ 1659 UserIdentification_IKeyLink "true";
BA_ "Event" SG_ 1659 UserIdentification_IKeyLink "true";
BA_ "Event" SG_ 1659 UserIdentification_IKeyLink "true";
BA_ "Unavailable_Value" SG_ 1659 UserIdentification_IKeyLink "0b000";
BA_ "Event" SG_ 1660 RearSeatsLockStatus "true";
BA_ "Event" SG_ 1660 RearSeatsLockStatus "true";
BA_ "Event" SG_ 1660 RearSeatsLockStatus "true";
BA_ "Event" SG_ 1660 RearSeatsLockStatus "true";
BA_ "Unavailable_Value" SG_ 1660 RearSeatsLockStatus "0b00";
BA_ "Event" SG_ 1660 SecondRowRightSeatStatus "true";
BA_ "Event" SG_ 1660 SecondRowRightSeatStatus "true";
BA_ "Event" SG_ 1660 SecondRowRightSeatStatus "true";
BA_ "Event" SG_ 1660 SecondRowRightSeatStatus "true";
BA_ "Unavailable_Value" SG_ 1660 SecondRowRightSeatStatus "0b000";
BA_ "Event" SG_ 1660 SecondRowLeftSeatStatus "true";
BA_ "Event" SG_ 1660 SecondRowLeftSeatStatus "true";
BA_ "Event" SG_ 1660 SecondRowLeftSeatStatus "true";
BA_ "Event" SG_ 1660 SecondRowLeftSeatStatus "true";
BA_ "Unavailable_Value" SG_ 1660 SecondRowLeftSeatStatus "0b000";
BA_ "Event" SG_ 1660 ClimAutoRecyclingDisplayStatus "true";
BA_ "Event" SG_ 1660 ClimAutoRecyclingDisplayStatus "true";
BA_ "Event" SG_ 1660 ClimAutoRecyclingDisplayStatus "true";
BA_ "Event" SG_ 1660 ClimAutoRecyclingDisplayStatus "true";
BA_ "Unavailable_Value" SG_ 1660 ClimAutoRecyclingDisplayStatus "0b0";
BA_ "Event" SG_ 1660 ClimACDisplayStatus "true";
BA_ "Event" SG_ 1660 ClimACDisplayStatus "true";
BA_ "Event" SG_ 1660 ClimACDisplayStatus "true";
BA_ "Event" SG_ 1660 ClimACDisplayStatus "true";
BA_ "Unavailable_Value" SG_ 1660 ClimACDisplayStatus "0b0";
BA_ "Event" SG_ 1660 ThirdRowRightSeatStatus "true";
BA_ "Event" SG_ 1660 ThirdRowRightSeatStatus "true";
BA_ "Event" SG_ 1660 ThirdRowRightSeatStatus "true";
BA_ "Event" SG_ 1660 ThirdRowRightSeatStatus "true";
BA_ "Unavailable_Value" SG_ 1660 ThirdRowRightSeatStatus "0b000";
BA_ "Event" SG_ 1660 ThirdRowLeftSeatStatus "true";
BA_ "Event" SG_ 1660 ThirdRowLeftSeatStatus "true";
BA_ "Event" SG_ 1660 ThirdRowLeftSeatStatus "true";
BA_ "Event" SG_ 1660 ThirdRowLeftSeatStatus "true";
BA_ "Unavailable_Value" SG_ 1660 ThirdRowLeftSeatStatus "0b000";
BA_ "Event" SG_ 1660 ClimEVHeaterDisplayStatus "true";
BA_ "Event" SG_ 1660 ClimEVHeaterDisplayStatus "true";
BA_ "Event" SG_ 1660 ClimEVHeaterDisplayStatus "true";
BA_ "Event" SG_ 1660 ClimEVHeaterDisplayStatus "true";
BA_ "Unavailable_Value" SG_ 1660 ClimEVHeaterDisplayStatus "0b0";
BA_ "Event" SG_ 1660 ClimDriverZoneDisplayStatus "true";
BA_ "Event" SG_ 1660 ClimDriverZoneDisplayStatus "true";
BA_ "Event" SG_ 1660 ClimDriverZoneDisplayStatus "true";
BA_ "Event" SG_ 1660 ClimDriverZoneDisplayStatus "true";
BA_ "Unavailable_Value" SG_ 1660 ClimDriverZoneDisplayStatus "0b0";
BA_ "Event" SG_ 1660 ClimDriverZoneDisplay "true";
BA_ "Event" SG_ 1660 ClimDriverZoneDisplay "true";
BA_ "Event" SG_ 1660 ClimDriverZoneDisplay "true";
BA_ "Event" SG_ 1660 ClimDriverZoneDisplay "true";
BA_ "Unavailable_Value" SG_ 1660 ClimDriverZoneDisplay "0b00";
BA_ "Event" SG_ 1660 ClimClearnessDisplayStatus "true";
BA_ "Event" SG_ 1660 ClimClearnessDisplayStatus "true";
BA_ "Event" SG_ 1660 ClimClearnessDisplayStatus "true";
BA_ "Event" SG_ 1660 ClimClearnessDisplayStatus "true";
BA_ "Unavailable_Value" SG_ 1660 ClimClearnessDisplayStatus "0b0";
BA_ "Event" SG_ 1660 ClimBlowingLevelDisplayStatus "true";
BA_ "Event" SG_ 1660 ClimBlowingLevelDisplayStatus "true";
BA_ "Event" SG_ 1660 ClimBlowingLevelDisplayStatus "true";
BA_ "Event" SG_ 1660 ClimBlowingLevelDisplayStatus "true";
BA_ "Unavailable_Value" SG_ 1660 ClimBlowingLevelDisplayStatus "0b0";
BA_ "Event" SG_ 1660 ClimBlowingAutoDisplay "true";
BA_ "Event" SG_ 1660 ClimBlowingAutoDisplay "true";
BA_ "Event" SG_ 1660 ClimBlowingAutoDisplay "true";
BA_ "Event" SG_ 1660 ClimBlowingAutoDisplay "true";
BA_ "Unavailable_Value" SG_ 1660 ClimBlowingAutoDisplay "0b00";
BA_ "Event" SG_ 1660 ClimHumidityDisplayStatus "true";
BA_ "Event" SG_ 1660 ClimHumidityDisplayStatus "true";
BA_ "Event" SG_ 1660 ClimHumidityDisplayStatus "true";
BA_ "Event" SG_ 1660 ClimHumidityDisplayStatus "true";
BA_ "Unavailable_Value" SG_ 1660 ClimHumidityDisplayStatus "0b0";
BA_ "Event" SG_ 1660 ClimForestSettingDisplayStatus "true";
BA_ "Event" SG_ 1660 ClimForestSettingDisplayStatus "true";
BA_ "Event" SG_ 1660 ClimForestSettingDisplayStatus "true";
BA_ "Event" SG_ 1660 ClimForestSettingDisplayStatus "true";
BA_ "Unavailable_Value" SG_ 1660 ClimForestSettingDisplayStatus "0b0";
BA_ "Event" SG_ 1660 ClimForestDisplayStatus "true";
BA_ "Event" SG_ 1660 ClimForestDisplayStatus "true";
BA_ "Event" SG_ 1660 ClimForestDisplayStatus "true";
BA_ "Event" SG_ 1660 ClimForestDisplayStatus "true";
BA_ "Unavailable_Value" SG_ 1660 ClimForestDisplayStatus "0b0";
BA_ "Event" SG_ 1660 ClimForestDisplay "true";
BA_ "Event" SG_ 1660 ClimForestDisplay "true";
BA_ "Event" SG_ 1660 ClimForestDisplay "true";
BA_ "Event" SG_ 1660 ClimForestDisplay "true";
BA_ "Unavailable_Value" SG_ 1660 ClimForestDisplay "0b00";
BA_ "Event" SG_ 1660 ClimFlowDistrDisplayStatus "true";
BA_ "Event" SG_ 1660 ClimFlowDistrDisplayStatus "true";
BA_ "Event" SG_ 1660 ClimFlowDistrDisplayStatus "true";
BA_ "Event" SG_ 1660 ClimFlowDistrDisplayStatus "true";
BA_ "Unavailable_Value" SG_ 1660 ClimFlowDistrDisplayStatus "0b0";
BA_ "Event" SG_ 1660 ClimEVHeaterDisplay "true";
BA_ "Event" SG_ 1660 ClimEVHeaterDisplay "true";
BA_ "Event" SG_ 1660 ClimEVHeaterDisplay "true";
BA_ "Event" SG_ 1660 ClimEVHeaterDisplay "true";
BA_ "Unavailable_Value" SG_ 1660 ClimEVHeaterDisplay "0b00";
BA_ "Event" SG_ 1660 ClimLinkDefrostAndClearnesDisp "true";
BA_ "Event" SG_ 1660 ClimLinkDefrostAndClearnesDisp "true";
BA_ "Event" SG_ 1660 ClimLinkDefrostAndClearnesDisp "true";
BA_ "Event" SG_ 1660 ClimLinkDefrostAndClearnesDisp "true";
BA_ "Unavailable_Value" SG_ 1660 ClimLinkDefrostAndClearnesDisp "0b00";
BA_ "Event" SG_ 1660 ClimHumiditySensorSensitivDisp "true";
BA_ "Event" SG_ 1660 ClimHumiditySensorSensitivDisp "true";
BA_ "Event" SG_ 1660 ClimHumiditySensorSensitivDisp "true";
BA_ "Event" SG_ 1660 ClimHumiditySensorSensitivDisp "true";
BA_ "Unavailable_Value" SG_ 1660 ClimHumiditySensorSensitivDisp "0b000";
BA_ "Event" SG_ 1660 ClimHumidityDisplay "true";
BA_ "Event" SG_ 1660 ClimHumidityDisplay "true";
BA_ "Event" SG_ 1660 ClimHumidityDisplay "true";
BA_ "Event" SG_ 1660 ClimHumidityDisplay "true";
BA_ "Unavailable_Value" SG_ 1660 ClimHumidityDisplay "0b000";
BA_ "Event" SG_ 1660 ClimRightAutoDisplay "true";
BA_ "Event" SG_ 1660 ClimRightAutoDisplay "true";
BA_ "Event" SG_ 1660 ClimRightAutoDisplay "true";
BA_ "Event" SG_ 1660 ClimRightAutoDisplay "true";
BA_ "Unavailable_Value" SG_ 1660 ClimRightAutoDisplay "0b00";
BA_ "Event" SG_ 1660 ClimOFFModeDisplayStatus "true";
BA_ "Event" SG_ 1660 ClimOFFModeDisplayStatus "true";
BA_ "Event" SG_ 1660 ClimOFFModeDisplayStatus "true";
BA_ "Event" SG_ 1660 ClimOFFModeDisplayStatus "true";
BA_ "Unavailable_Value" SG_ 1660 ClimOFFModeDisplayStatus "0b0";
BA_ "Event" SG_ 1660 ClimLinkMaxFanSpeedAutoDisplay "true";
BA_ "Event" SG_ 1660 ClimLinkMaxFanSpeedAutoDisplay "true";
BA_ "Event" SG_ 1660 ClimLinkMaxFanSpeedAutoDisplay "true";
BA_ "Event" SG_ 1660 ClimLinkMaxFanSpeedAutoDisplay "true";
BA_ "Unavailable_Value" SG_ 1660 ClimLinkMaxFanSpeedAutoDisplay "0b000";
BA_ "Event" SG_ 1660 ClimLinkFreshRecyAndAutoDisplay "true";
BA_ "Event" SG_ 1660 ClimLinkFreshRecyAndAutoDisplay "true";
BA_ "Event" SG_ 1660 ClimLinkFreshRecyAndAutoDisplay "true";
BA_ "Event" SG_ 1660 ClimLinkFreshRecyAndAutoDisplay "true";
BA_ "Unavailable_Value" SG_ 1660 ClimLinkFreshRecyAndAutoDisplay "0b00";
BA_ "Event" SG_ 1660 ClimRightFlowDistrDisplayStatus "true";
BA_ "Event" SG_ 1660 ClimRightFlowDistrDisplayStatus "true";
BA_ "Event" SG_ 1660 ClimRightFlowDistrDisplayStatus "true";
BA_ "Event" SG_ 1660 ClimRightFlowDistrDisplayStatus "true";
BA_ "Unavailable_Value" SG_ 1660 ClimRightFlowDistrDisplayStatus "0b0";
BA_ "Event" SG_ 1660 ClimRightBlowingLevelDispStatus "true";
BA_ "Event" SG_ 1660 ClimRightBlowingLevelDispStatus "true";
BA_ "Event" SG_ 1660 ClimRightBlowingLevelDispStatus "true";
BA_ "Event" SG_ 1660 ClimRightBlowingLevelDispStatus "true";
BA_ "Unavailable_Value" SG_ 1660 ClimRightBlowingLevelDispStatus "0b0";
BA_ "Event" SG_ 1660 ClimRightBlowingLevelDisplay "true";
BA_ "Event" SG_ 1660 ClimRightBlowingLevelDisplay "true";
BA_ "Event" SG_ 1660 ClimRightBlowingLevelDisplay "true";
BA_ "Event" SG_ 1660 ClimRightBlowingLevelDisplay "true";
BA_ "Unavailable_Value" SG_ 1660 ClimRightBlowingLevelDisplay "0b0000";
BA_ "Event" SG_ 1660 ClimRightBlowingAutoDisplay "true";
BA_ "Event" SG_ 1660 ClimRightBlowingAutoDisplay "true";
BA_ "Event" SG_ 1660 ClimRightBlowingAutoDisplay "true";
BA_ "Event" SG_ 1660 ClimRightBlowingAutoDisplay "true";
BA_ "Unavailable_Value" SG_ 1660 ClimRightBlowingAutoDisplay "0b00";
BA_ "Event" SG_ 1660 ClimTempDisplayStatus "true";
BA_ "Event" SG_ 1660 ClimTempDisplayStatus "true";
BA_ "Event" SG_ 1660 ClimTempDisplayStatus "true";
BA_ "Event" SG_ 1660 ClimTempDisplayStatus "true";
BA_ "Unavailable_Value" SG_ 1660 ClimTempDisplayStatus "0b0";
BA_ "Event" SG_ 1660 ClimSyncDisplayStatus "true";
BA_ "Event" SG_ 1660 ClimSyncDisplayStatus "true";
BA_ "Event" SG_ 1660 ClimSyncDisplayStatus "true";
BA_ "Event" SG_ 1660 ClimSyncDisplayStatus "true";
BA_ "Unavailable_Value" SG_ 1660 ClimSyncDisplayStatus "0b0";
BA_ "Event" SG_ 1660 ClimSyncDisplay "true";
BA_ "Event" SG_ 1660 ClimSyncDisplay "true";
BA_ "Event" SG_ 1660 ClimSyncDisplay "true";
BA_ "Event" SG_ 1660 ClimSyncDisplay "true";
BA_ "Unavailable_Value" SG_ 1660 ClimSyncDisplay "0b00";
BA_ "Event" SG_ 1660 ClimRightTempDisplayStatus "true";
BA_ "Event" SG_ 1660 ClimRightTempDisplayStatus "true";
BA_ "Event" SG_ 1660 ClimRightTempDisplayStatus "true";
BA_ "Event" SG_ 1660 ClimRightTempDisplayStatus "true";
BA_ "Unavailable_Value" SG_ 1660 ClimRightTempDisplayStatus "0b0";
BA_ "Event" SG_ 1660 ClimRightFlowDistrDisplay "true";
BA_ "Event" SG_ 1660 ClimRightFlowDistrDisplay "true";
BA_ "Event" SG_ 1660 ClimRightFlowDistrDisplay "true";
BA_ "Event" SG_ 1660 ClimRightFlowDistrDisplay "true";
BA_ "Unavailable_Value" SG_ 1660 ClimRightFlowDistrDisplay "0b000";
BA_ "Event" SG_ 1661 AltitudePosition "true";
BA_ "Event" SG_ 1661 AltitudePosition "true";
BA_ "Event" SG_ 1661 AltitudePosition "true";
BA_ "Event" SG_ 1661 AltitudePosition "true";
BA_ "Unavailable_Value" SG_ 1661 AltitudePosition "0x0000";
BA_ "Event" SG_ 1661 ITM_FrontLeftSeatHeatPush "true";
BA_ "Event" SG_ 1661 ITM_FrontLeftSeatHeatPush "true";
BA_ "Event" SG_ 1661 ITM_FrontLeftSeatHeatPush "true";
BA_ "Event" SG_ 1661 ITM_FrontLeftSeatHeatPush "true";
BA_ "Unavailable_Value" SG_ 1661 ITM_FrontLeftSeatHeatPush "0b0";
BA_ "Event" SG_ 1661 ITM_FrontLeftSeatDownPush "true";
BA_ "Event" SG_ 1661 ITM_FrontLeftSeatDownPush "true";
BA_ "Event" SG_ 1661 ITM_FrontLeftSeatDownPush "true";
BA_ "Event" SG_ 1661 ITM_FrontLeftSeatDownPush "true";
BA_ "Unavailable_Value" SG_ 1661 ITM_FrontLeftSeatDownPush "0b0";
BA_ "Event" SG_ 1661 ITM_ForcedRecyclingLongPush "true";
BA_ "Event" SG_ 1661 ITM_ForcedRecyclingLongPush "true";
BA_ "Event" SG_ 1661 ITM_ForcedRecyclingLongPush "true";
BA_ "Event" SG_ 1661 ITM_ForcedRecyclingLongPush "true";
BA_ "Unavailable_Value" SG_ 1661 ITM_ForcedRecyclingLongPush "0b0";
BA_ "Event" SG_ 1661 ITM_ForcedFreshLongPush "true";
BA_ "Event" SG_ 1661 ITM_ForcedFreshLongPush "true";
BA_ "Event" SG_ 1661 ITM_ForcedFreshLongPush "true";
BA_ "Event" SG_ 1661 ITM_ForcedFreshLongPush "true";
BA_ "Unavailable_Value" SG_ 1661 ITM_ForcedFreshLongPush "0b0";
BA_ "Event" SG_ 1661 ITM_AirIntakeOperationType "true";
BA_ "Event" SG_ 1661 ITM_AirIntakeOperationType "true";
BA_ "Event" SG_ 1661 ITM_AirIntakeOperationType "true";
BA_ "Event" SG_ 1661 ITM_AirIntakeOperationType "true";
BA_ "Event" SG_ 1661 ITM_AirIntakeModePush "true";
BA_ "Event" SG_ 1661 ITM_AirIntakeModePush "true";
BA_ "Event" SG_ 1661 ITM_AirIntakeModePush "true";
BA_ "Event" SG_ 1661 ITM_AirIntakeModePush "true";
BA_ "Unavailable_Value" SG_ 1661 ITM_AirIntakeModePush "0b0";
BA_ "Event" SG_ 1661 ITM_AirIntakeModeLongPush "true";
BA_ "Event" SG_ 1661 ITM_AirIntakeModeLongPush "true";
BA_ "Event" SG_ 1661 ITM_AirIntakeModeLongPush "true";
BA_ "Event" SG_ 1661 ITM_AirIntakeModeLongPush "true";
BA_ "Unavailable_Value" SG_ 1661 ITM_AirIntakeModeLongPush "0b0";
BA_ "Event" SG_ 1661 ITM_FrontRightSeatUpPush "true";
BA_ "Event" SG_ 1661 ITM_FrontRightSeatUpPush "true";
BA_ "Event" SG_ 1661 ITM_FrontRightSeatUpPush "true";
BA_ "Event" SG_ 1661 ITM_FrontRightSeatUpPush "true";
BA_ "Unavailable_Value" SG_ 1661 ITM_FrontRightSeatUpPush "0b0";
BA_ "Event" SG_ 1661 ITM_FrontRightSeatOFFPush "true";
BA_ "Event" SG_ 1661 ITM_FrontRightSeatOFFPush "true";
BA_ "Event" SG_ 1661 ITM_FrontRightSeatOFFPush "true";
BA_ "Event" SG_ 1661 ITM_FrontRightSeatOFFPush "true";
BA_ "Unavailable_Value" SG_ 1661 ITM_FrontRightSeatOFFPush "0b0";
BA_ "Event" SG_ 1661 ITM_FrontRightSeatHeatPush "true";
BA_ "Event" SG_ 1661 ITM_FrontRightSeatHeatPush "true";
BA_ "Event" SG_ 1661 ITM_FrontRightSeatHeatPush "true";
BA_ "Event" SG_ 1661 ITM_FrontRightSeatHeatPush "true";
BA_ "Unavailable_Value" SG_ 1661 ITM_FrontRightSeatHeatPush "0b0";
BA_ "Event" SG_ 1661 ITM_FrontRightSeatDownPush "true";
BA_ "Event" SG_ 1661 ITM_FrontRightSeatDownPush "true";
BA_ "Event" SG_ 1661 ITM_FrontRightSeatDownPush "true";
BA_ "Event" SG_ 1661 ITM_FrontRightSeatDownPush "true";
BA_ "Unavailable_Value" SG_ 1661 ITM_FrontRightSeatDownPush "0b0";
BA_ "Event" SG_ 1661 ITM_FrontLeftSeatUpPush "true";
BA_ "Event" SG_ 1661 ITM_FrontLeftSeatUpPush "true";
BA_ "Event" SG_ 1661 ITM_FrontLeftSeatUpPush "true";
BA_ "Event" SG_ 1661 ITM_FrontLeftSeatUpPush "true";
BA_ "Unavailable_Value" SG_ 1661 ITM_FrontLeftSeatUpPush "0b0";
BA_ "Event" SG_ 1661 ITM_FrontLeftSeatOFFPush "true";
BA_ "Event" SG_ 1661 ITM_FrontLeftSeatOFFPush "true";
BA_ "Event" SG_ 1661 ITM_FrontLeftSeatOFFPush "true";
BA_ "Event" SG_ 1661 ITM_FrontLeftSeatOFFPush "true";
BA_ "Unavailable_Value" SG_ 1661 ITM_FrontLeftSeatOFFPush "0b0";
BA_ "Event" SG_ 1661 ITM_SecondRowRightSeatDownPush "true";
BA_ "Event" SG_ 1661 ITM_SecondRowRightSeatDownPush "true";
BA_ "Event" SG_ 1661 ITM_SecondRowRightSeatDownPush "true";
BA_ "Event" SG_ 1661 ITM_SecondRowRightSeatDownPush "true";
BA_ "Unavailable_Value" SG_ 1661 ITM_SecondRowRightSeatDownPush "0b0";
BA_ "Event" SG_ 1661 ITM_SecondRowLeftSeatUpPush "true";
BA_ "Event" SG_ 1661 ITM_SecondRowLeftSeatUpPush "true";
BA_ "Event" SG_ 1661 ITM_SecondRowLeftSeatUpPush "true";
BA_ "Event" SG_ 1661 ITM_SecondRowLeftSeatUpPush "true";
BA_ "Unavailable_Value" SG_ 1661 ITM_SecondRowLeftSeatUpPush "0b0";
BA_ "Event" SG_ 1661 ITM_SecondRowLeftSeatOFFPush "true";
BA_ "Event" SG_ 1661 ITM_SecondRowLeftSeatOFFPush "true";
BA_ "Event" SG_ 1661 ITM_SecondRowLeftSeatOFFPush "true";
BA_ "Event" SG_ 1661 ITM_SecondRowLeftSeatOFFPush "true";
BA_ "Unavailable_Value" SG_ 1661 ITM_SecondRowLeftSeatOFFPush "0b0";
BA_ "Event" SG_ 1661 ITM_SecondRowLeftSeatHeatPush "true";
BA_ "Event" SG_ 1661 ITM_SecondRowLeftSeatHeatPush "true";
BA_ "Event" SG_ 1661 ITM_SecondRowLeftSeatHeatPush "true";
BA_ "Event" SG_ 1661 ITM_SecondRowLeftSeatHeatPush "true";
BA_ "Unavailable_Value" SG_ 1661 ITM_SecondRowLeftSeatHeatPush "0b0";
BA_ "Event" SG_ 1661 ITM_SecondRowLeftSeatDownPush "true";
BA_ "Event" SG_ 1661 ITM_SecondRowLeftSeatDownPush "true";
BA_ "Event" SG_ 1661 ITM_SecondRowLeftSeatDownPush "true";
BA_ "Event" SG_ 1661 ITM_SecondRowLeftSeatDownPush "true";
BA_ "Unavailable_Value" SG_ 1661 ITM_SecondRowLeftSeatDownPush "0b0";
BA_ "Event" SG_ 1661 ITM_RecyclingModeRequest "true";
BA_ "Event" SG_ 1661 ITM_RecyclingModeRequest "true";
BA_ "Event" SG_ 1661 ITM_RecyclingModeRequest "true";
BA_ "Event" SG_ 1661 ITM_RecyclingModeRequest "true";
BA_ "Unavailable_Value" SG_ 1661 ITM_RecyclingModeRequest "0b000";
BA_ "Event" SG_ 1661 ITM_ThirdRowRightSeatDownPush "true";
BA_ "Event" SG_ 1661 ITM_ThirdRowRightSeatDownPush "true";
BA_ "Event" SG_ 1661 ITM_ThirdRowRightSeatDownPush "true";
BA_ "Event" SG_ 1661 ITM_ThirdRowRightSeatDownPush "true";
BA_ "Unavailable_Value" SG_ 1661 ITM_ThirdRowRightSeatDownPush "0b0";
BA_ "Event" SG_ 1661 ITM_ThirdRowLeftSeatUpPush "true";
BA_ "Event" SG_ 1661 ITM_ThirdRowLeftSeatUpPush "true";
BA_ "Event" SG_ 1661 ITM_ThirdRowLeftSeatUpPush "true";
BA_ "Event" SG_ 1661 ITM_ThirdRowLeftSeatUpPush "true";
BA_ "Unavailable_Value" SG_ 1661 ITM_ThirdRowLeftSeatUpPush "0b0";
BA_ "Event" SG_ 1661 ITM_ThirdRowLeftSeatOFFPush "true";
BA_ "Event" SG_ 1661 ITM_ThirdRowLeftSeatOFFPush "true";
BA_ "Event" SG_ 1661 ITM_ThirdRowLeftSeatOFFPush "true";
BA_ "Event" SG_ 1661 ITM_ThirdRowLeftSeatOFFPush "true";
BA_ "Unavailable_Value" SG_ 1661 ITM_ThirdRowLeftSeatOFFPush "0b0";
BA_ "Event" SG_ 1661 ITM_ThirdRowLeftSeatHeatPush "true";
BA_ "Event" SG_ 1661 ITM_ThirdRowLeftSeatHeatPush "true";
BA_ "Event" SG_ 1661 ITM_ThirdRowLeftSeatHeatPush "true";
BA_ "Event" SG_ 1661 ITM_ThirdRowLeftSeatHeatPush "true";
BA_ "Unavailable_Value" SG_ 1661 ITM_ThirdRowLeftSeatHeatPush "0b0";
BA_ "Event" SG_ 1661 ITM_ThirdRowLeftSeatDownPush "true";
BA_ "Event" SG_ 1661 ITM_ThirdRowLeftSeatDownPush "true";
BA_ "Event" SG_ 1661 ITM_ThirdRowLeftSeatDownPush "true";
BA_ "Event" SG_ 1661 ITM_ThirdRowLeftSeatDownPush "true";
BA_ "Unavailable_Value" SG_ 1661 ITM_ThirdRowLeftSeatDownPush "0b0";
BA_ "Event" SG_ 1661 ITM_SecondRowRightSeatUpPush "true";
BA_ "Event" SG_ 1661 ITM_SecondRowRightSeatUpPush "true";
BA_ "Event" SG_ 1661 ITM_SecondRowRightSeatUpPush "true";
BA_ "Event" SG_ 1661 ITM_SecondRowRightSeatUpPush "true";
BA_ "Unavailable_Value" SG_ 1661 ITM_SecondRowRightSeatUpPush "0b0";
BA_ "Event" SG_ 1661 ITM_SecondRowRightSeatOFFPush "true";
BA_ "Event" SG_ 1661 ITM_SecondRowRightSeatOFFPush "true";
BA_ "Event" SG_ 1661 ITM_SecondRowRightSeatOFFPush "true";
BA_ "Event" SG_ 1661 ITM_SecondRowRightSeatOFFPush "true";
BA_ "Unavailable_Value" SG_ 1661 ITM_SecondRowRightSeatOFFPush "0b0";
BA_ "Event" SG_ 1661 ITM_SecondRowRightSeatHeatPush "true";
BA_ "Event" SG_ 1661 ITM_SecondRowRightSeatHeatPush "true";
BA_ "Event" SG_ 1661 ITM_SecondRowRightSeatHeatPush "true";
BA_ "Event" SG_ 1661 ITM_SecondRowRightSeatHeatPush "true";
BA_ "Unavailable_Value" SG_ 1661 ITM_SecondRowRightSeatHeatPush "0b0";
BA_ "Event" SG_ 1661 ITM_ThirdRowRightSeatUpPush "true";
BA_ "Event" SG_ 1661 ITM_ThirdRowRightSeatUpPush "true";
BA_ "Event" SG_ 1661 ITM_ThirdRowRightSeatUpPush "true";
BA_ "Event" SG_ 1661 ITM_ThirdRowRightSeatUpPush "true";
BA_ "Unavailable_Value" SG_ 1661 ITM_ThirdRowRightSeatUpPush "0b0";
BA_ "Event" SG_ 1661 ITM_ThirdRowRightSeatOFFPush "true";
BA_ "Event" SG_ 1661 ITM_ThirdRowRightSeatOFFPush "true";
BA_ "Event" SG_ 1661 ITM_ThirdRowRightSeatOFFPush "true";
BA_ "Event" SG_ 1661 ITM_ThirdRowRightSeatOFFPush "true";
BA_ "Unavailable_Value" SG_ 1661 ITM_ThirdRowRightSeatOFFPush "0b0";
BA_ "Event" SG_ 1661 ITM_ThirdRowRightSeatHeatPush "true";
BA_ "Event" SG_ 1661 ITM_ThirdRowRightSeatHeatPush "true";
BA_ "Event" SG_ 1661 ITM_ThirdRowRightSeatHeatPush "true";
BA_ "Event" SG_ 1661 ITM_ThirdRowRightSeatHeatPush "true";
BA_ "Unavailable_Value" SG_ 1661 ITM_ThirdRowRightSeatHeatPush "0b0";
BA_ "Event" SG_ 1662 PassengerSeatMemoRecall "true";
BA_ "Event" SG_ 1662 PassengerSeatMemoRecall "true";
BA_ "Event" SG_ 1662 PassengerSeatMemoRecall "true";
BA_ "Event" SG_ 1662 PassengerSeatMemoRecall "true";
BA_ "Unavailable_Value" SG_ 1662 PassengerSeatMemoRecall "0b000";
BA_ "Event" SG_ 1662 PassengerSeatMemoRequest "true";
BA_ "Event" SG_ 1662 PassengerSeatMemoRequest "true";
BA_ "Event" SG_ 1662 PassengerSeatMemoRequest "true";
BA_ "Event" SG_ 1662 PassengerSeatMemoRequest "true";
BA_ "Unavailable_Value" SG_ 1662 PassengerSeatMemoRequest "0b000";
BA_ "Event" SG_ 1662 SecondRowRightSeatRequest "true";
BA_ "Event" SG_ 1662 SecondRowRightSeatRequest "true";
BA_ "Event" SG_ 1662 SecondRowRightSeatRequest "true";
BA_ "Event" SG_ 1662 SecondRowRightSeatRequest "true";
BA_ "Unavailable_Value" SG_ 1662 SecondRowRightSeatRequest "0b0000";
BA_ "Event" SG_ 1662 SecondRowLeftSeatRequest "true";
BA_ "Event" SG_ 1662 SecondRowLeftSeatRequest "true";
BA_ "Event" SG_ 1662 SecondRowLeftSeatRequest "true";
BA_ "Event" SG_ 1662 SecondRowLeftSeatRequest "true";
BA_ "Unavailable_Value" SG_ 1662 SecondRowLeftSeatRequest "0b0000";
BA_ "Event" SG_ 1662 ThirdRowRightSeatRequest "true";
BA_ "Event" SG_ 1662 ThirdRowRightSeatRequest "true";
BA_ "Event" SG_ 1662 ThirdRowRightSeatRequest "true";
BA_ "Event" SG_ 1662 ThirdRowRightSeatRequest "true";
BA_ "Unavailable_Value" SG_ 1662 ThirdRowRightSeatRequest "0b0000";
BA_ "Event" SG_ 1662 ThirdRowLeftSeatRequest "true";
BA_ "Event" SG_ 1662 ThirdRowLeftSeatRequest "true";
BA_ "Event" SG_ 1662 ThirdRowLeftSeatRequest "true";
BA_ "Event" SG_ 1662 ThirdRowLeftSeatRequest "true";
BA_ "Unavailable_Value" SG_ 1662 ThirdRowLeftSeatRequest "0b0000";
BA_ "Event" SG_ 1662 ClimClearnessPush "true";
BA_ "Event" SG_ 1662 ClimClearnessPush "true";
BA_ "Event" SG_ 1662 ClimClearnessPush "true";
BA_ "Event" SG_ 1662 ClimClearnessPush "true";
BA_ "Unavailable_Value" SG_ 1662 ClimClearnessPush "0b0";
BA_ "Event" SG_ 1662 ClimACPush "true";
BA_ "Event" SG_ 1662 ClimACPush "true";
BA_ "Event" SG_ 1662 ClimACPush "true";
BA_ "Event" SG_ 1662 ClimACPush "true";
BA_ "Unavailable_Value" SG_ 1662 ClimACPush "0b0";
BA_ "Event" SG_ 1662 WirelessChargeActivationReq "true";
BA_ "Event" SG_ 1662 WirelessChargeActivationReq "true";
BA_ "Event" SG_ 1662 WirelessChargeActivationReq "true";
BA_ "Event" SG_ 1662 WirelessChargeActivationReq "true";
BA_ "Unavailable_Value" SG_ 1662 WirelessChargeActivationReq "0b0";
BA_ "Event" SG_ 1662 RearSeatsLockRequest "true";
BA_ "Event" SG_ 1662 RearSeatsLockRequest "true";
BA_ "Event" SG_ 1662 RearSeatsLockRequest "true";
BA_ "Event" SG_ 1662 RearSeatsLockRequest "true";
BA_ "Unavailable_Value" SG_ 1662 RearSeatsLockRequest "0b00";
BA_ "Event" SG_ 1662 ClimHumiditySensorSensitivitReq "true";
BA_ "Event" SG_ 1662 ClimHumiditySensorSensitivitReq "true";
BA_ "Event" SG_ 1662 ClimHumiditySensorSensitivitReq "true";
BA_ "Event" SG_ 1662 ClimHumiditySensorSensitivitReq "true";
BA_ "Unavailable_Value" SG_ 1662 ClimHumiditySensorSensitivitReq "0b000";
BA_ "Event" SG_ 1662 ClimForestPush "true";
BA_ "Event" SG_ 1662 ClimForestPush "true";
BA_ "Event" SG_ 1662 ClimForestPush "true";
BA_ "Event" SG_ 1662 ClimForestPush "true";
BA_ "Unavailable_Value" SG_ 1662 ClimForestPush "0b0";
BA_ "Event" SG_ 1662 ClimForcedRecyclingPush "true";
BA_ "Event" SG_ 1662 ClimForcedRecyclingPush "true";
BA_ "Event" SG_ 1662 ClimForcedRecyclingPush "true";
BA_ "Event" SG_ 1662 ClimForcedRecyclingPush "true";
BA_ "Unavailable_Value" SG_ 1662 ClimForcedRecyclingPush "0b0";
BA_ "Event" SG_ 1662 ClimForcedFreshPush "true";
BA_ "Event" SG_ 1662 ClimForcedFreshPush "true";
BA_ "Event" SG_ 1662 ClimForcedFreshPush "true";
BA_ "Event" SG_ 1662 ClimForcedFreshPush "true";
BA_ "Unavailable_Value" SG_ 1662 ClimForcedFreshPush "0b0";
BA_ "Event" SG_ 1662 ClimEVHeaterPush "true";
BA_ "Event" SG_ 1662 ClimEVHeaterPush "true";
BA_ "Event" SG_ 1662 ClimEVHeaterPush "true";
BA_ "Event" SG_ 1662 ClimEVHeaterPush "true";
BA_ "Unavailable_Value" SG_ 1662 ClimEVHeaterPush "0b0";
BA_ "Event" SG_ 1662 ClimDriverZonePush "true";
BA_ "Event" SG_ 1662 ClimDriverZonePush "true";
BA_ "Event" SG_ 1662 ClimDriverZonePush "true";
BA_ "Event" SG_ 1662 ClimDriverZonePush "true";
BA_ "Unavailable_Value" SG_ 1662 ClimDriverZonePush "0b0";
BA_ "Event" SG_ 1662 ClimRightFlowDistrDefPush "true";
BA_ "Event" SG_ 1662 ClimRightFlowDistrDefPush "true";
BA_ "Event" SG_ 1662 ClimRightFlowDistrDefPush "true";
BA_ "Event" SG_ 1662 ClimRightFlowDistrDefPush "true";
BA_ "Unavailable_Value" SG_ 1662 ClimRightFlowDistrDefPush "0b0";
BA_ "Event" SG_ 1662 TimeFormatDisplay "true";
BA_ "Event" SG_ 1662 TimeFormatDisplay "true";
BA_ "Event" SG_ 1662 TimeFormatDisplay "true";
BA_ "Event" SG_ 1662 TimeFormatDisplay "true";
BA_ "Unavailable_Value" SG_ 1662 TimeFormatDisplay "null";
BA_ "Event" SG_ 1662 ClimFPrightBlowingRequest "true";
BA_ "Event" SG_ 1662 ClimFPrightBlowingRequest "true";
BA_ "Event" SG_ 1662 ClimFPrightBlowingRequest "true";
BA_ "Event" SG_ 1662 ClimFPrightBlowingRequest "true";
BA_ "Unavailable_Value" SG_ 1662 ClimFPrightBlowingRequest "0b0000";
BA_ "Event" SG_ 1662 ClimRightFlowDistrVentPush "true";
BA_ "Event" SG_ 1662 ClimRightFlowDistrVentPush "true";
BA_ "Event" SG_ 1662 ClimRightFlowDistrVentPush "true";
BA_ "Event" SG_ 1662 ClimRightFlowDistrVentPush "true";
BA_ "Unavailable_Value" SG_ 1662 ClimRightFlowDistrVentPush "0b0";
BA_ "Event" SG_ 1662 ClimRightFlowDistrFeetPush "true";
BA_ "Event" SG_ 1662 ClimRightFlowDistrFeetPush "true";
BA_ "Event" SG_ 1662 ClimRightFlowDistrFeetPush "true";
BA_ "Event" SG_ 1662 ClimRightFlowDistrFeetPush "true";
BA_ "Unavailable_Value" SG_ 1662 ClimRightFlowDistrFeetPush "0b0";
BA_ "Event" SG_ 1662 ClimLinkPriorityFLSeatAutoReq "true";
BA_ "Event" SG_ 1662 ClimLinkPriorityFLSeatAutoReq "true";
BA_ "Event" SG_ 1662 ClimLinkPriorityFLSeatAutoReq "true";
BA_ "Event" SG_ 1662 ClimLinkPriorityFLSeatAutoReq "true";
BA_ "Unavailable_Value" SG_ 1662 ClimLinkPriorityFLSeatAutoReq "0b000";
BA_ "Event" SG_ 1662 ClimLinkMaxFanSpeedAutoReq "true";
BA_ "Event" SG_ 1662 ClimLinkMaxFanSpeedAutoReq "true";
BA_ "Event" SG_ 1662 ClimLinkMaxFanSpeedAutoReq "true";
BA_ "Event" SG_ 1662 ClimLinkMaxFanSpeedAutoReq "true";
BA_ "Unavailable_Value" SG_ 1662 ClimLinkMaxFanSpeedAutoReq "0b000";
BA_ "Event" SG_ 1662 ClimLinkDefrostAndClearnesPush "true";
BA_ "Event" SG_ 1662 ClimLinkDefrostAndClearnesPush "true";
BA_ "Event" SG_ 1662 ClimLinkDefrostAndClearnesPush "true";
BA_ "Event" SG_ 1662 ClimLinkDefrostAndClearnesPush "true";
BA_ "Unavailable_Value" SG_ 1662 ClimLinkDefrostAndClearnesPush "0b0";
BA_ "Event" SG_ 1662 ClimRightAutoNormalPush "true";
BA_ "Event" SG_ 1662 ClimRightAutoNormalPush "true";
BA_ "Event" SG_ 1662 ClimRightAutoNormalPush "true";
BA_ "Event" SG_ 1662 ClimRightAutoNormalPush "true";
BA_ "Unavailable_Value" SG_ 1662 ClimRightAutoNormalPush "0b0";
BA_ "Event" SG_ 1662 FrontRightSeatAutoPush "true";
BA_ "Event" SG_ 1662 FrontRightSeatAutoPush "true";
BA_ "Event" SG_ 1662 FrontRightSeatAutoPush "true";
BA_ "Event" SG_ 1662 FrontRightSeatAutoPush "true";
BA_ "Unavailable_Value" SG_ 1662 FrontRightSeatAutoPush "0b0";
BA_ "Event" SG_ 1662 FrontLeftSeatAutoPush "true";
BA_ "Event" SG_ 1662 FrontLeftSeatAutoPush "true";
BA_ "Event" SG_ 1662 FrontLeftSeatAutoPush "true";
BA_ "Event" SG_ 1662 FrontLeftSeatAutoPush "true";
BA_ "Unavailable_Value" SG_ 1662 FrontLeftSeatAutoPush "0b0";
BA_ "Event" SG_ 1662 ClimSyncPush "true";
BA_ "Event" SG_ 1662 ClimSyncPush "true";
BA_ "Event" SG_ 1662 ClimSyncPush "true";
BA_ "Event" SG_ 1662 ClimSyncPush "true";
BA_ "Unavailable_Value" SG_ 1662 ClimSyncPush "0b0";
BA_ "Event" SG_ 1662 ClimLinkPriorityFRSeatAutoReq "true";
BA_ "Event" SG_ 1662 ClimLinkPriorityFRSeatAutoReq "true";
BA_ "Event" SG_ 1662 ClimLinkPriorityFRSeatAutoReq "true";
BA_ "Event" SG_ 1662 ClimLinkPriorityFRSeatAutoReq "true";
BA_ "Unavailable_Value" SG_ 1662 ClimLinkPriorityFRSeatAutoReq "0b000";
BA_ "Unavailable_Value" SG_ 1677 DistanceToDestination "0xFFF";
BA_ "Unavailable_Value" SG_ 1677 TimeToDestination "0x3FF";
BA_ "Event" SG_ 1681 GroundSpeed "true";
BA_ "Event" SG_ 1681 GroundSpeed "true";
BA_ "Event" SG_ 1681 GroundSpeed "true";
BA_ "Event" SG_ 1681 GroundSpeed "true";
BA_ "Unavailable_Value" SG_ 1681 GroundSpeed "0xFFF";
BA_ "Event" SG_ 1681 BCI_TemporaryOFFRequest "true";
BA_ "Event" SG_ 1681 BCI_TemporaryOFFRequest "true";
BA_ "Event" SG_ 1681 BCI_TemporaryOFFRequest "true";
BA_ "Event" SG_ 1681 BCI_TemporaryOFFRequest "true";
BA_ "Unavailable_Value" SG_ 1681 BCI_TemporaryOFFRequest "0b0";
BA_ "Event" SG_ 1681 SatelliteGPSCount "true";
BA_ "Event" SG_ 1681 SatelliteGPSCount "true";
BA_ "Event" SG_ 1681 SatelliteGPSCount "true";
BA_ "Event" SG_ 1681 SatelliteGPSCount "true";
BA_ "Unavailable_Value" SG_ 1681 SatelliteGPSCount "null";
BA_ "Event" SG_ 1681 VerticalDilutionOfPrecision "true";
BA_ "Event" SG_ 1681 VerticalDilutionOfPrecision "true";
BA_ "Event" SG_ 1681 VerticalDilutionOfPrecision "true";
BA_ "Event" SG_ 1681 VerticalDilutionOfPrecision "true";
BA_ "Unavailable_Value" SG_ 1681 VerticalDilutionOfPrecision "0x1F";
BA_ "Event" SG_ 1681 IVI_ChangeLayoutRequest "true";
BA_ "Event" SG_ 1681 IVI_ChangeLayoutRequest "true";
BA_ "Event" SG_ 1681 IVI_ChangeLayoutRequest "true";
BA_ "Event" SG_ 1681 IVI_ChangeLayoutRequest "true";
BA_ "Unavailable_Value" SG_ 1681 IVI_ChangeLayoutRequest "0x00";
BA_ "Event" SG_ 1681 HorizontalDilutionOfPrecision "true";
BA_ "Event" SG_ 1681 HorizontalDilutionOfPrecision "true";
BA_ "Event" SG_ 1681 HorizontalDilutionOfPrecision "true";
BA_ "Event" SG_ 1681 HorizontalDilutionOfPrecision "true";
BA_ "Unavailable_Value" SG_ 1681 HorizontalDilutionOfPrecision "0x1F";
BA_ "Event" SG_ 1681 IVI_LayoutDisplayedStatus "true";
BA_ "Event" SG_ 1681 IVI_LayoutDisplayedStatus "true";
BA_ "Event" SG_ 1681 IVI_LayoutDisplayedStatus "true";
BA_ "Event" SG_ 1681 IVI_LayoutDisplayedStatus "true";
BA_ "Unavailable_Value" SG_ 1681 IVI_LayoutDisplayedStatus "0x00";
BA_ "Event" SG_ 1682 ClimHeatedSteeringWheelDisplay "true";
BA_ "Event" SG_ 1682 ClimHeatedSteeringWheelDisplay "true";
BA_ "Event" SG_ 1682 ClimHeatedSteeringWheelDisplay "true";
BA_ "Event" SG_ 1682 ClimHeatedSteeringWheelDisplay "true";
BA_ "Unavailable_Value" SG_ 1682 ClimHeatedSteeringWheelDisplay "0b00";
BA_ "Unavailable_Value" SG_ 1682 ClimDualModeDisplay_v2 "0b00";
BA_ "Event" SG_ 1684 APA_WarningDisplayRequest "true";
BA_ "Event" SG_ 1684 APA_WarningDisplayRequest "true";
BA_ "Event" SG_ 1684 APA_WarningDisplayRequest "true";
BA_ "Event" SG_ 1684 APA_WarningDisplayRequest "true";
BA_ "Unavailable_Value" SG_ 1684 APA_WarningDisplayRequest "0x00";
BA_ "Event" SG_ 1684 HFP_MapContentDisplay2 "true";
BA_ "Event" SG_ 1684 HFP_MapContentDisplay2 "true";
BA_ "Event" SG_ 1684 HFP_MapContentDisplay2 "true";
BA_ "Event" SG_ 1684 HFP_MapContentDisplay2 "true";
BA_ "Unavailable_Value" SG_ 1684 HFP_MapContentDisplay2 "0b00";
BA_ "Event" SG_ 1684 APA_ViewMaskRequest "true";
BA_ "Event" SG_ 1684 APA_ViewMaskRequest "true";
BA_ "Event" SG_ 1684 APA_ViewMaskRequest "true";
BA_ "Event" SG_ 1684 APA_ViewMaskRequest "true";
BA_ "Unavailable_Value" SG_ 1684 APA_ViewMaskRequest "0b0";
BA_ "Event" SG_ 1684 APA_ScanInfo "true";
BA_ "Event" SG_ 1684 APA_ScanInfo "true";
BA_ "Event" SG_ 1684 APA_ScanInfo "true";
BA_ "Event" SG_ 1684 APA_ScanInfo "true";
BA_ "Unavailable_Value" SG_ 1684 APA_ScanInfo "0b000";
BA_ "Event" SG_ 1685 CGW_FOTABusyFlag "true";
BA_ "Event" SG_ 1685 CGW_FOTABusyFlag "true";
BA_ "Event" SG_ 1685 CGW_FOTABusyFlag "true";
BA_ "Event" SG_ 1685 CGW_FOTABusyFlag "true";
BA_ "Unavailable_Value" SG_ 1685 CGW_FOTABusyFlag "0b0";
BA_ "Event" SG_ 1685 CGW_FOTA_Progress "true";
BA_ "Event" SG_ 1685 CGW_FOTA_Progress "true";
BA_ "Event" SG_ 1685 CGW_FOTA_Progress "true";
BA_ "Event" SG_ 1685 CGW_FOTA_Progress "true";
BA_ "Unavailable_Value" SG_ 1685 CGW_FOTA_Progress "0xF";
BA_ "Event" SG_ 1685 CGW_FOTAstatus_v2 "true";
BA_ "Event" SG_ 1685 CGW_FOTAstatus_v2 "true";
BA_ "Event" SG_ 1685 CGW_FOTAstatus_v2 "true";
BA_ "Event" SG_ 1685 CGW_FOTAstatus_v2 "true";
BA_ "Unavailable_Value" SG_ 1685 CGW_FOTAstatus_v2 "0x1F";
BA_ "Unavailable_Value" SG_ 1690 TripDistanceHEV "0x1FFFF";
BA_ "Unavailable_Value" SG_ 1690 InstantConsumptionICEdisplay "0x3FF";
BA_ "Unavailable_Value" SG_ 1690 TripDistanceZEV "0x1FFFF";
BA_ "Unavailable_Value" SG_ 1695 VehicleID "0xFFFFFFFF";
BA_ "Event" SG_ 1703 ProgrammedChargeStatus "true";
BA_ "Event" SG_ 1703 ProgrammedChargeStatus "true";
BA_ "Event" SG_ 1703 ProgrammedChargeStatus "true";
BA_ "Event" SG_ 1703 ProgrammedChargeStatus "true";
BA_ "Unavailable_Value" SG_ 1703 ProgrammedChargeStatus "0b00";
BA_ "Event" SG_ 1724 SOCinit_ePOIspotDestination "true";
BA_ "Event" SG_ 1724 SOCinit_ePOIspotDestination "true";
BA_ "Event" SG_ 1724 SOCinit_ePOIspotDestination "true";
BA_ "Event" SG_ 1724 SOCinit_ePOIspotDestination "true";
BA_ "Unavailable_Value" SG_ 1724 SOCinit_ePOIspotDestination "0x3FF";
BA_ "Event" SG_ 1724 SOCtargetDestination "true";
BA_ "Event" SG_ 1724 SOCtargetDestination "true";
BA_ "Event" SG_ 1724 SOCtargetDestination "true";
BA_ "Event" SG_ 1724 SOCtargetDestination "true";
BA_ "Unavailable_Value" SG_ 1724 SOCtargetDestination "0x3FF";
BA_ "Event" SG_ 1724 ePOIspotPowerLevel "true";
BA_ "Event" SG_ 1724 ePOIspotPowerLevel "true";
BA_ "Event" SG_ 1724 ePOIspotPowerLevel "true";
BA_ "Event" SG_ 1724 ePOIspotPowerLevel "true";
BA_ "Unavailable_Value" SG_ 1724 ePOIspotPowerLevel "0x1FF";
BA_ "Event" SG_ 1724 ChargeTimeIndexReachibility "true";
BA_ "Event" SG_ 1724 ChargeTimeIndexReachibility "true";
BA_ "Event" SG_ 1724 ChargeTimeIndexReachibility "true";
BA_ "Event" SG_ 1724 ChargeTimeIndexReachibility "true";
BA_ "Unavailable_Value" SG_ 1724 ChargeTimeIndexReachibility "0x0";
BA_ "Unavailable_Value" SG_ 1724 SC_DepartureTime "0x7FF";
BA_ "Event" SG_ 1724 SC_MinimumSOC "true";
BA_ "Event" SG_ 1724 SC_MinimumSOC "true";
BA_ "Event" SG_ 1724 SC_MinimumSOC "true";
BA_ "Event" SG_ 1724 SC_MinimumSOC "true";
BA_ "Unavailable_Value" SG_ 1724 SC_MinimumSOC "0x1F";
BA_ "Event" SG_ 1724 SC_TargetSOC "true";
BA_ "Event" SG_ 1724 SC_TargetSOC "true";
BA_ "Event" SG_ 1724 SC_TargetSOC "true";
BA_ "Event" SG_ 1724 SC_TargetSOC "true";
BA_ "Unavailable_Value" SG_ 1724 SC_TargetSOC "0x1F";
BA_ "Event" SG_ 1742 PreferedLaneAssist_State "true";
BA_ "Event" SG_ 1742 PreferedLaneAssist_State "true";
BA_ "Event" SG_ 1742 PreferedLaneAssist_State "true";
BA_ "Event" SG_ 1742 PreferedLaneAssist_State "true";
BA_ "Unavailable_Value" SG_ 1742 PreferedLaneAssist_State "0b11";
BA_ "Event" SG_ 1755 EV_Ratio "true";
BA_ "Event" SG_ 1755 EV_Ratio "true";
BA_ "Event" SG_ 1755 EV_Ratio "true";
BA_ "Event" SG_ 1755 EV_Ratio "true";
BA_ "Event" SG_ 1755 HVbatteryCoolingInProgressStatus "true";
BA_ "Event" SG_ 1755 HVbatteryCoolingInProgressStatus "true";
BA_ "Event" SG_ 1755 HVbatteryCoolingInProgressStatus "true";
BA_ "Event" SG_ 1755 HVbatteryCoolingInProgressStatus "true";
BA_ "Unavailable_Value" SG_ 1755 HVbatteryCoolingInProgressStatus "0b0";
BA_ "Event" SG_ 1755 HVbatteryCoolingActivationState "true";
BA_ "Event" SG_ 1755 HVbatteryCoolingActivationState "true";
BA_ "Event" SG_ 1755 HVbatteryCoolingActivationState "true";
BA_ "Event" SG_ 1755 HVbatteryCoolingActivationState "true";
BA_ "Unavailable_Value" SG_ 1755 HVbatteryCoolingActivationState "0b0";
BA_ "Event" SG_ 1755 ClimHVpowerLimitationDisp_HEVC "true";
BA_ "Event" SG_ 1755 ClimHVpowerLimitationDisp_HEVC "true";
BA_ "Event" SG_ 1755 ClimHVpowerLimitationDisp_HEVC "true";
BA_ "Event" SG_ 1755 ClimHVpowerLimitationDisp_HEVC "true";
BA_ "Unavailable_Value" SG_ 1755 ClimHVpowerLimitationDisp_HEVC "0b000";
BA_ "Event" SG_ 1755 HVbatteryWarmingState "true";
BA_ "Event" SG_ 1755 HVbatteryWarmingState "true";
BA_ "Event" SG_ 1755 HVbatteryWarmingState "true";
BA_ "Event" SG_ 1755 HVbatteryWarmingState "true";
BA_ "Unavailable_Value" SG_ 1755 HVbatteryWarmingState "0b0";
BA_ "Event" SG_ 1779 ChargeCal1DurationChange_MMI "true";
BA_ "Event" SG_ 1779 ChargeCal1DurationChange_MMI "true";
BA_ "Event" SG_ 1779 ChargeCal1DurationChange_MMI "true";
BA_ "Event" SG_ 1779 ChargeCal1DurationChange_MMI "true";
BA_ "Unavailable_Value" SG_ 1779 ChargeCal1DurationChange_MMI "0x7FF";
BA_ "Event" SG_ 1779 ChargeCal1BeginHourChange_MMI "true";
BA_ "Event" SG_ 1779 ChargeCal1BeginHourChange_MMI "true";
BA_ "Event" SG_ 1779 ChargeCal1BeginHourChange_MMI "true";
BA_ "Event" SG_ 1779 ChargeCal1BeginHourChange_MMI "true";
BA_ "Unavailable_Value" SG_ 1779 ChargeCal1BeginHourChange_MMI "0x1F";
BA_ "Event" SG_ 1779 ChargeCal1TuesdayChange_MMI "true";
BA_ "Event" SG_ 1779 ChargeCal1TuesdayChange_MMI "true";
BA_ "Event" SG_ 1779 ChargeCal1TuesdayChange_MMI "true";
BA_ "Event" SG_ 1779 ChargeCal1TuesdayChange_MMI "true";
BA_ "Unavailable_Value" SG_ 1779 ChargeCal1TuesdayChange_MMI "0b0";
BA_ "Event" SG_ 1779 ChargeCal1MondayChange_MMI "true";
BA_ "Event" SG_ 1779 ChargeCal1MondayChange_MMI "true";
BA_ "Event" SG_ 1779 ChargeCal1MondayChange_MMI "true";
BA_ "Event" SG_ 1779 ChargeCal1MondayChange_MMI "true";
BA_ "Unavailable_Value" SG_ 1779 ChargeCal1MondayChange_MMI "0b0";
BA_ "Event" SG_ 1779 ChargeCal1BeginMinChange_MMI "true";
BA_ "Event" SG_ 1779 ChargeCal1BeginMinChange_MMI "true";
BA_ "Event" SG_ 1779 ChargeCal1BeginMinChange_MMI "true";
BA_ "Event" SG_ 1779 ChargeCal1BeginMinChange_MMI "true";
BA_ "Unavailable_Value" SG_ 1779 ChargeCal1BeginMinChange_MMI "0x3F";
BA_ "Event" SG_ 1779 ChargeCal1SundayChange_MMI "true";
BA_ "Event" SG_ 1779 ChargeCal1SundayChange_MMI "true";
BA_ "Event" SG_ 1779 ChargeCal1SundayChange_MMI "true";
BA_ "Event" SG_ 1779 ChargeCal1SundayChange_MMI "true";
BA_ "Unavailable_Value" SG_ 1779 ChargeCal1SundayChange_MMI "0b0";
BA_ "Event" SG_ 1779 ChargeCal1SaturdayChange_MMI "true";
BA_ "Event" SG_ 1779 ChargeCal1SaturdayChange_MMI "true";
BA_ "Event" SG_ 1779 ChargeCal1SaturdayChange_MMI "true";
BA_ "Event" SG_ 1779 ChargeCal1SaturdayChange_MMI "true";
BA_ "Unavailable_Value" SG_ 1779 ChargeCal1SaturdayChange_MMI "0b0";
BA_ "Event" SG_ 1779 ChargeCal1FridayChange_MMI "true";
BA_ "Event" SG_ 1779 ChargeCal1FridayChange_MMI "true";
BA_ "Event" SG_ 1779 ChargeCal1FridayChange_MMI "true";
BA_ "Event" SG_ 1779 ChargeCal1FridayChange_MMI "true";
BA_ "Unavailable_Value" SG_ 1779 ChargeCal1FridayChange_MMI "0b0";
BA_ "Event" SG_ 1779 ChargeCal1ThursdayChange_MMI "true";
BA_ "Event" SG_ 1779 ChargeCal1ThursdayChange_MMI "true";
BA_ "Event" SG_ 1779 ChargeCal1ThursdayChange_MMI "true";
BA_ "Event" SG_ 1779 ChargeCal1ThursdayChange_MMI "true";
BA_ "Unavailable_Value" SG_ 1779 ChargeCal1ThursdayChange_MMI "0b0";
BA_ "Event" SG_ 1779 ChargeCal1WednesdayChange_MMI "true";
BA_ "Event" SG_ 1779 ChargeCal1WednesdayChange_MMI "true";
BA_ "Event" SG_ 1779 ChargeCal1WednesdayChange_MMI "true";
BA_ "Event" SG_ 1779 ChargeCal1WednesdayChange_MMI "true";
BA_ "Unavailable_Value" SG_ 1779 ChargeCal1WednesdayChange_MMI "0b0";
BA_ "Event" SG_ 1779 ChargeCal2DurationChange_MMI "true";
BA_ "Event" SG_ 1779 ChargeCal2DurationChange_MMI "true";
BA_ "Event" SG_ 1779 ChargeCal2DurationChange_MMI "true";
BA_ "Event" SG_ 1779 ChargeCal2DurationChange_MMI "true";
BA_ "Unavailable_Value" SG_ 1779 ChargeCal2DurationChange_MMI "0x7FF";
BA_ "Event" SG_ 1779 ChargeCal2BeginHourChange_MMI "true";
BA_ "Event" SG_ 1779 ChargeCal2BeginHourChange_MMI "true";
BA_ "Event" SG_ 1779 ChargeCal2BeginHourChange_MMI "true";
BA_ "Event" SG_ 1779 ChargeCal2BeginHourChange_MMI "true";
BA_ "Unavailable_Value" SG_ 1779 ChargeCal2BeginHourChange_MMI "0x1F";
BA_ "Event" SG_ 1779 ChargeCal2TuesdayChange_MMI "true";
BA_ "Event" SG_ 1779 ChargeCal2TuesdayChange_MMI "true";
BA_ "Event" SG_ 1779 ChargeCal2TuesdayChange_MMI "true";
BA_ "Event" SG_ 1779 ChargeCal2TuesdayChange_MMI "true";
BA_ "Unavailable_Value" SG_ 1779 ChargeCal2TuesdayChange_MMI "0b0";
BA_ "Event" SG_ 1779 ChargeCal2MondayChange_MMI "true";
BA_ "Event" SG_ 1779 ChargeCal2MondayChange_MMI "true";
BA_ "Event" SG_ 1779 ChargeCal2MondayChange_MMI "true";
BA_ "Event" SG_ 1779 ChargeCal2MondayChange_MMI "true";
BA_ "Unavailable_Value" SG_ 1779 ChargeCal2MondayChange_MMI "0b0";
BA_ "Event" SG_ 1779 ChargeCal2BeginMinChange_MMI "true";
BA_ "Event" SG_ 1779 ChargeCal2BeginMinChange_MMI "true";
BA_ "Event" SG_ 1779 ChargeCal2BeginMinChange_MMI "true";
BA_ "Event" SG_ 1779 ChargeCal2BeginMinChange_MMI "true";
BA_ "Unavailable_Value" SG_ 1779 ChargeCal2BeginMinChange_MMI "0x3F";
BA_ "Event" SG_ 1779 ChargeCalAllChange_MMI "true";
BA_ "Event" SG_ 1779 ChargeCalAllChange_MMI "true";
BA_ "Event" SG_ 1779 ChargeCalAllChange_MMI "true";
BA_ "Event" SG_ 1779 ChargeCalAllChange_MMI "true";
BA_ "Unavailable_Value" SG_ 1779 ChargeCalAllChange_MMI "0b00";
BA_ "Event" SG_ 1779 ChargeCal2SundayChange_MMI "true";
BA_ "Event" SG_ 1779 ChargeCal2SundayChange_MMI "true";
BA_ "Event" SG_ 1779 ChargeCal2SundayChange_MMI "true";
BA_ "Event" SG_ 1779 ChargeCal2SundayChange_MMI "true";
BA_ "Unavailable_Value" SG_ 1779 ChargeCal2SundayChange_MMI "0b0";
BA_ "Event" SG_ 1779 ChargeCal2SaturdayChange_MMI "true";
BA_ "Event" SG_ 1779 ChargeCal2SaturdayChange_MMI "true";
BA_ "Event" SG_ 1779 ChargeCal2SaturdayChange_MMI "true";
BA_ "Event" SG_ 1779 ChargeCal2SaturdayChange_MMI "true";
BA_ "Unavailable_Value" SG_ 1779 ChargeCal2SaturdayChange_MMI "0b0";
BA_ "Event" SG_ 1779 ChargeCal2FridayChange_MMI "true";
BA_ "Event" SG_ 1779 ChargeCal2FridayChange_MMI "true";
BA_ "Event" SG_ 1779 ChargeCal2FridayChange_MMI "true";
BA_ "Event" SG_ 1779 ChargeCal2FridayChange_MMI "true";
BA_ "Unavailable_Value" SG_ 1779 ChargeCal2FridayChange_MMI "0b0";
BA_ "Event" SG_ 1779 ChargeCal2ThursdayChange_MMI "true";
BA_ "Event" SG_ 1779 ChargeCal2ThursdayChange_MMI "true";
BA_ "Event" SG_ 1779 ChargeCal2ThursdayChange_MMI "true";
BA_ "Event" SG_ 1779 ChargeCal2ThursdayChange_MMI "true";
BA_ "Unavailable_Value" SG_ 1779 ChargeCal2ThursdayChange_MMI "0b0";
BA_ "Event" SG_ 1779 ChargeCal2WednesdayChange_MMI "true";
BA_ "Event" SG_ 1779 ChargeCal2WednesdayChange_MMI "true";
BA_ "Event" SG_ 1779 ChargeCal2WednesdayChange_MMI "true";
BA_ "Event" SG_ 1779 ChargeCal2WednesdayChange_MMI "true";
BA_ "Unavailable_Value" SG_ 1779 ChargeCal2WednesdayChange_MMI "0b0";
BA_ "Event" SG_ 1780 ChargeCal3DurationChange_MMI "true";
BA_ "Event" SG_ 1780 ChargeCal3DurationChange_MMI "true";
BA_ "Event" SG_ 1780 ChargeCal3DurationChange_MMI "true";
BA_ "Event" SG_ 1780 ChargeCal3DurationChange_MMI "true";
BA_ "Unavailable_Value" SG_ 1780 ChargeCal3DurationChange_MMI "0x7FF";
BA_ "Event" SG_ 1780 ChargeCal3BeginHourChange_MMI "true";
BA_ "Event" SG_ 1780 ChargeCal3BeginHourChange_MMI "true";
BA_ "Event" SG_ 1780 ChargeCal3BeginHourChange_MMI "true";
BA_ "Event" SG_ 1780 ChargeCal3BeginHourChange_MMI "true";
BA_ "Unavailable_Value" SG_ 1780 ChargeCal3BeginHourChange_MMI "0x1F";
BA_ "Event" SG_ 1780 ChargeCal3TuesdayChange_MMI "true";
BA_ "Event" SG_ 1780 ChargeCal3TuesdayChange_MMI "true";
BA_ "Event" SG_ 1780 ChargeCal3TuesdayChange_MMI "true";
BA_ "Event" SG_ 1780 ChargeCal3TuesdayChange_MMI "true";
BA_ "Unavailable_Value" SG_ 1780 ChargeCal3TuesdayChange_MMI "0b0";
BA_ "Event" SG_ 1780 ChargeCal3MondayChange_MMI "true";
BA_ "Event" SG_ 1780 ChargeCal3MondayChange_MMI "true";
BA_ "Event" SG_ 1780 ChargeCal3MondayChange_MMI "true";
BA_ "Event" SG_ 1780 ChargeCal3MondayChange_MMI "true";
BA_ "Unavailable_Value" SG_ 1780 ChargeCal3MondayChange_MMI "0b0";
BA_ "Event" SG_ 1780 ChargeCal3BeginMinChange_MMI "true";
BA_ "Event" SG_ 1780 ChargeCal3BeginMinChange_MMI "true";
BA_ "Event" SG_ 1780 ChargeCal3BeginMinChange_MMI "true";
BA_ "Event" SG_ 1780 ChargeCal3BeginMinChange_MMI "true";
BA_ "Unavailable_Value" SG_ 1780 ChargeCal3BeginMinChange_MMI "0x3F";
BA_ "Event" SG_ 1780 ChargeCal3SundayChange_MMI "true";
BA_ "Event" SG_ 1780 ChargeCal3SundayChange_MMI "true";
BA_ "Event" SG_ 1780 ChargeCal3SundayChange_MMI "true";
BA_ "Event" SG_ 1780 ChargeCal3SundayChange_MMI "true";
BA_ "Unavailable_Value" SG_ 1780 ChargeCal3SundayChange_MMI "0b0";
BA_ "Event" SG_ 1780 ChargeCal3SaturdayChange_MMI "true";
BA_ "Event" SG_ 1780 ChargeCal3SaturdayChange_MMI "true";
BA_ "Event" SG_ 1780 ChargeCal3SaturdayChange_MMI "true";
BA_ "Event" SG_ 1780 ChargeCal3SaturdayChange_MMI "true";
BA_ "Unavailable_Value" SG_ 1780 ChargeCal3SaturdayChange_MMI "0b0";
BA_ "Event" SG_ 1780 ChargeCal3FridayChange_MMI "true";
BA_ "Event" SG_ 1780 ChargeCal3FridayChange_MMI "true";
BA_ "Event" SG_ 1780 ChargeCal3FridayChange_MMI "true";
BA_ "Event" SG_ 1780 ChargeCal3FridayChange_MMI "true";
BA_ "Unavailable_Value" SG_ 1780 ChargeCal3FridayChange_MMI "0b0";
BA_ "Event" SG_ 1780 ChargeCal3ThursdayChange_MMI "true";
BA_ "Event" SG_ 1780 ChargeCal3ThursdayChange_MMI "true";
BA_ "Event" SG_ 1780 ChargeCal3ThursdayChange_MMI "true";
BA_ "Event" SG_ 1780 ChargeCal3ThursdayChange_MMI "true";
BA_ "Unavailable_Value" SG_ 1780 ChargeCal3ThursdayChange_MMI "0b0";
BA_ "Event" SG_ 1780 ChargeCal3WednesdayChange_MMI "true";
BA_ "Event" SG_ 1780 ChargeCal3WednesdayChange_MMI "true";
BA_ "Event" SG_ 1780 ChargeCal3WednesdayChange_MMI "true";
BA_ "Event" SG_ 1780 ChargeCal3WednesdayChange_MMI "true";
BA_ "Unavailable_Value" SG_ 1780 ChargeCal3WednesdayChange_MMI "0b0";
BA_ "Event" SG_ 1780 ChargeCal4DurationChange_MMI "true";
BA_ "Event" SG_ 1780 ChargeCal4DurationChange_MMI "true";
BA_ "Event" SG_ 1780 ChargeCal4DurationChange_MMI "true";
BA_ "Event" SG_ 1780 ChargeCal4DurationChange_MMI "true";
BA_ "Unavailable_Value" SG_ 1780 ChargeCal4DurationChange_MMI "0x7FF";
BA_ "Event" SG_ 1780 ChargeCal4BeginHourChange_MMI "true";
BA_ "Event" SG_ 1780 ChargeCal4BeginHourChange_MMI "true";
BA_ "Event" SG_ 1780 ChargeCal4BeginHourChange_MMI "true";
BA_ "Event" SG_ 1780 ChargeCal4BeginHourChange_MMI "true";
BA_ "Unavailable_Value" SG_ 1780 ChargeCal4BeginHourChange_MMI "0x1F";
BA_ "Event" SG_ 1780 ChargeCal4TuesdayChange_MMI "true";
BA_ "Event" SG_ 1780 ChargeCal4TuesdayChange_MMI "true";
BA_ "Event" SG_ 1780 ChargeCal4TuesdayChange_MMI "true";
BA_ "Event" SG_ 1780 ChargeCal4TuesdayChange_MMI "true";
BA_ "Unavailable_Value" SG_ 1780 ChargeCal4TuesdayChange_MMI "0b0";
BA_ "Event" SG_ 1780 ChargeCal4MondayChange_MMI "true";
BA_ "Event" SG_ 1780 ChargeCal4MondayChange_MMI "true";
BA_ "Event" SG_ 1780 ChargeCal4MondayChange_MMI "true";
BA_ "Event" SG_ 1780 ChargeCal4MondayChange_MMI "true";
BA_ "Unavailable_Value" SG_ 1780 ChargeCal4MondayChange_MMI "0b0";
BA_ "Event" SG_ 1780 ChargeCal4BeginMinChange_MMI "true";
BA_ "Event" SG_ 1780 ChargeCal4BeginMinChange_MMI "true";
BA_ "Event" SG_ 1780 ChargeCal4BeginMinChange_MMI "true";
BA_ "Event" SG_ 1780 ChargeCal4BeginMinChange_MMI "true";
BA_ "Unavailable_Value" SG_ 1780 ChargeCal4BeginMinChange_MMI "0x3F";
BA_ "Event" SG_ 1780 ChargeCal4SundayChange_MMI "true";
BA_ "Event" SG_ 1780 ChargeCal4SundayChange_MMI "true";
BA_ "Event" SG_ 1780 ChargeCal4SundayChange_MMI "true";
BA_ "Event" SG_ 1780 ChargeCal4SundayChange_MMI "true";
BA_ "Unavailable_Value" SG_ 1780 ChargeCal4SundayChange_MMI "0b0";
BA_ "Event" SG_ 1780 ChargeCal4SaturdayChange_MMI "true";
BA_ "Event" SG_ 1780 ChargeCal4SaturdayChange_MMI "true";
BA_ "Event" SG_ 1780 ChargeCal4SaturdayChange_MMI "true";
BA_ "Event" SG_ 1780 ChargeCal4SaturdayChange_MMI "true";
BA_ "Unavailable_Value" SG_ 1780 ChargeCal4SaturdayChange_MMI "0b0";
BA_ "Event" SG_ 1780 ChargeCal4FridayChange_MMI "true";
BA_ "Event" SG_ 1780 ChargeCal4FridayChange_MMI "true";
BA_ "Event" SG_ 1780 ChargeCal4FridayChange_MMI "true";
BA_ "Event" SG_ 1780 ChargeCal4FridayChange_MMI "true";
BA_ "Unavailable_Value" SG_ 1780 ChargeCal4FridayChange_MMI "0b0";
BA_ "Event" SG_ 1780 ChargeCal4ThursdayChange_MMI "true";
BA_ "Event" SG_ 1780 ChargeCal4ThursdayChange_MMI "true";
BA_ "Event" SG_ 1780 ChargeCal4ThursdayChange_MMI "true";
BA_ "Event" SG_ 1780 ChargeCal4ThursdayChange_MMI "true";
BA_ "Unavailable_Value" SG_ 1780 ChargeCal4ThursdayChange_MMI "0b0";
BA_ "Event" SG_ 1780 ChargeCal4WednesdayChange_MMI "true";
BA_ "Event" SG_ 1780 ChargeCal4WednesdayChange_MMI "true";
BA_ "Event" SG_ 1780 ChargeCal4WednesdayChange_MMI "true";
BA_ "Event" SG_ 1780 ChargeCal4WednesdayChange_MMI "true";
BA_ "Unavailable_Value" SG_ 1780 ChargeCal4WednesdayChange_MMI "0b0";
BA_ "Event" SG_ 1781 ChargeCal5DurationChange_MMI "true";
BA_ "Event" SG_ 1781 ChargeCal5DurationChange_MMI "true";
BA_ "Event" SG_ 1781 ChargeCal5DurationChange_MMI "true";
BA_ "Event" SG_ 1781 ChargeCal5DurationChange_MMI "true";
BA_ "Unavailable_Value" SG_ 1781 ChargeCal5DurationChange_MMI "0x7FF";
BA_ "Event" SG_ 1781 ChargeCal5BeginHourChange_MMI "true";
BA_ "Event" SG_ 1781 ChargeCal5BeginHourChange_MMI "true";
BA_ "Event" SG_ 1781 ChargeCal5BeginHourChange_MMI "true";
BA_ "Event" SG_ 1781 ChargeCal5BeginHourChange_MMI "true";
BA_ "Unavailable_Value" SG_ 1781 ChargeCal5BeginHourChange_MMI "0x1F";
BA_ "Event" SG_ 1781 ChargeCal5TuesdayChange_MMI "true";
BA_ "Event" SG_ 1781 ChargeCal5TuesdayChange_MMI "true";
BA_ "Event" SG_ 1781 ChargeCal5TuesdayChange_MMI "true";
BA_ "Event" SG_ 1781 ChargeCal5TuesdayChange_MMI "true";
BA_ "Unavailable_Value" SG_ 1781 ChargeCal5TuesdayChange_MMI "0b0";
BA_ "Event" SG_ 1781 ChargeCal5MondayChange_MMI "true";
BA_ "Event" SG_ 1781 ChargeCal5MondayChange_MMI "true";
BA_ "Event" SG_ 1781 ChargeCal5MondayChange_MMI "true";
BA_ "Event" SG_ 1781 ChargeCal5MondayChange_MMI "true";
BA_ "Unavailable_Value" SG_ 1781 ChargeCal5MondayChange_MMI "0b0";
BA_ "Event" SG_ 1781 ChargeCal5BeginMinChange_MMI "true";
BA_ "Event" SG_ 1781 ChargeCal5BeginMinChange_MMI "true";
BA_ "Event" SG_ 1781 ChargeCal5BeginMinChange_MMI "true";
BA_ "Event" SG_ 1781 ChargeCal5BeginMinChange_MMI "true";
BA_ "Unavailable_Value" SG_ 1781 ChargeCal5BeginMinChange_MMI "0x3F";
BA_ "Event" SG_ 1781 ChargeDelayedRequestValue "true";
BA_ "Event" SG_ 1781 ChargeDelayedRequestValue "true";
BA_ "Event" SG_ 1781 ChargeDelayedRequestValue "true";
BA_ "Event" SG_ 1781 ChargeDelayedRequestValue "true";
BA_ "Unavailable_Value" SG_ 1781 ChargeDelayedRequestValue "0x7FF";
BA_ "Event" SG_ 1781 ChargeCal5SundayChange_MMI "true";
BA_ "Event" SG_ 1781 ChargeCal5SundayChange_MMI "true";
BA_ "Event" SG_ 1781 ChargeCal5SundayChange_MMI "true";
BA_ "Event" SG_ 1781 ChargeCal5SundayChange_MMI "true";
BA_ "Unavailable_Value" SG_ 1781 ChargeCal5SundayChange_MMI "0b0";
BA_ "Event" SG_ 1781 ChargeCal5SaturdayChange_MMI "true";
BA_ "Event" SG_ 1781 ChargeCal5SaturdayChange_MMI "true";
BA_ "Event" SG_ 1781 ChargeCal5SaturdayChange_MMI "true";
BA_ "Event" SG_ 1781 ChargeCal5SaturdayChange_MMI "true";
BA_ "Unavailable_Value" SG_ 1781 ChargeCal5SaturdayChange_MMI "0b0";
BA_ "Event" SG_ 1781 ChargeCal5FridayChange_MMI "true";
BA_ "Event" SG_ 1781 ChargeCal5FridayChange_MMI "true";
BA_ "Event" SG_ 1781 ChargeCal5FridayChange_MMI "true";
BA_ "Event" SG_ 1781 ChargeCal5FridayChange_MMI "true";
BA_ "Unavailable_Value" SG_ 1781 ChargeCal5FridayChange_MMI "0b0";
BA_ "Event" SG_ 1781 ChargeCal5ThursdayChange_MMI "true";
BA_ "Event" SG_ 1781 ChargeCal5ThursdayChange_MMI "true";
BA_ "Event" SG_ 1781 ChargeCal5ThursdayChange_MMI "true";
BA_ "Event" SG_ 1781 ChargeCal5ThursdayChange_MMI "true";
BA_ "Unavailable_Value" SG_ 1781 ChargeCal5ThursdayChange_MMI "0b0";
BA_ "Event" SG_ 1781 ChargeCal5WednesdayChange_MMI "true";
BA_ "Event" SG_ 1781 ChargeCal5WednesdayChange_MMI "true";
BA_ "Event" SG_ 1781 ChargeCal5WednesdayChange_MMI "true";
BA_ "Event" SG_ 1781 ChargeCal5WednesdayChange_MMI "true";
BA_ "Unavailable_Value" SG_ 1781 ChargeCal5WednesdayChange_MMI "0b0";
BA_ "Event" SG_ 1781 EcoTripResetRequest "true";
BA_ "Event" SG_ 1781 EcoTripResetRequest "true";
BA_ "Event" SG_ 1781 EcoTripResetRequest "true";
BA_ "Event" SG_ 1781 EcoTripResetRequest "true";
BA_ "Unavailable_Value" SG_ 1781 EcoTripResetRequest "0b0";
BA_ "Event" SG_ 1781 SC_UserElecPriceSetNbSlot "true";
BA_ "Event" SG_ 1781 SC_UserElecPriceSetNbSlot "true";
BA_ "Event" SG_ 1781 SC_UserElecPriceSetNbSlot "true";
BA_ "Event" SG_ 1781 SC_UserElecPriceSetNbSlot "true";
BA_ "Unavailable_Value" SG_ 1781 SC_UserElecPriceSetNbSlot "0x1F";
BA_ "Event" SG_ 1781 ChargeDelayedRequest "true";
BA_ "Event" SG_ 1781 ChargeDelayedRequest "true";
BA_ "Event" SG_ 1781 ChargeDelayedRequest "true";
BA_ "Event" SG_ 1781 ChargeDelayedRequest "true";
BA_ "Unavailable_Value" SG_ 1781 ChargeDelayedRequest "0b0";
BA_ "Event" SG_ 1781 ChargeAlwaysRequest "true";
BA_ "Event" SG_ 1781 ChargeAlwaysRequest "true";
BA_ "Event" SG_ 1781 ChargeAlwaysRequest "true";
BA_ "Event" SG_ 1781 ChargeAlwaysRequest "true";
BA_ "Unavailable_Value" SG_ 1781 ChargeAlwaysRequest "0b0";
BA_ "Event" SG_ 1781 SC_UserElecPriceSetSlotDuration "true";
BA_ "Event" SG_ 1781 SC_UserElecPriceSetSlotDuration "true";
BA_ "Event" SG_ 1781 SC_UserElecPriceSetSlotDuration "true";
BA_ "Event" SG_ 1781 SC_UserElecPriceSetSlotDuration "true";
BA_ "Unavailable_Value" SG_ 1781 SC_UserElecPriceSetSlotDuration "0x1F";
BA_ "Event" SG_ 1781 SC_UserElecPriceSetRelativeCost "true";
BA_ "Event" SG_ 1781 SC_UserElecPriceSetRelativeCost "true";
BA_ "Event" SG_ 1781 SC_UserElecPriceSetRelativeCost "true";
BA_ "Event" SG_ 1781 SC_UserElecPriceSetRelativeCost "true";
BA_ "Unavailable_Value" SG_ 1781 SC_UserElecPriceSetRelativeCost "0xF";
BA_ "Event" SG_ 1781 FuelSaveClearHistoRequest "true";
BA_ "Event" SG_ 1781 FuelSaveClearHistoRequest "true";
BA_ "Event" SG_ 1781 FuelSaveClearHistoRequest "true";
BA_ "Event" SG_ 1781 FuelSaveClearHistoRequest "true";
BA_ "Unavailable_Value" SG_ 1781 FuelSaveClearHistoRequest "0b0";
BA_ "Event" SG_ 1782 PreSoakCal1ArrivalHourChange_MMI "true";
BA_ "Event" SG_ 1782 PreSoakCal1ArrivalHourChange_MMI "true";
BA_ "Event" SG_ 1782 PreSoakCal1ArrivalHourChange_MMI "true";
BA_ "Event" SG_ 1782 PreSoakCal1ArrivalHourChange_MMI "true";
BA_ "Unavailable_Value" SG_ 1782 PreSoakCal1ArrivalHourChange_MMI "0x1F";
BA_ "Event" SG_ 1782 PreSoakCal1ArrivalMinChange_MMI "true";
BA_ "Event" SG_ 1782 PreSoakCal1ArrivalMinChange_MMI "true";
BA_ "Event" SG_ 1782 PreSoakCal1ArrivalMinChange_MMI "true";
BA_ "Event" SG_ 1782 PreSoakCal1ArrivalMinChange_MMI "true";
BA_ "Unavailable_Value" SG_ 1782 PreSoakCal1ArrivalMinChange_MMI "0x3F";
BA_ "Event" SG_ 1782 PreSoakCal1FridayChange_MMI "true";
BA_ "Event" SG_ 1782 PreSoakCal1FridayChange_MMI "true";
BA_ "Event" SG_ 1782 PreSoakCal1FridayChange_MMI "true";
BA_ "Event" SG_ 1782 PreSoakCal1FridayChange_MMI "true";
BA_ "Unavailable_Value" SG_ 1782 PreSoakCal1FridayChange_MMI "0b0";
BA_ "Event" SG_ 1782 PreSoakCal1ThursdayChange_MMI "true";
BA_ "Event" SG_ 1782 PreSoakCal1ThursdayChange_MMI "true";
BA_ "Event" SG_ 1782 PreSoakCal1ThursdayChange_MMI "true";
BA_ "Event" SG_ 1782 PreSoakCal1ThursdayChange_MMI "true";
BA_ "Unavailable_Value" SG_ 1782 PreSoakCal1ThursdayChange_MMI "0b0";
BA_ "Event" SG_ 1782 PreSoakCal1WednesdayChange_MMI "true";
BA_ "Event" SG_ 1782 PreSoakCal1WednesdayChange_MMI "true";
BA_ "Event" SG_ 1782 PreSoakCal1WednesdayChange_MMI "true";
BA_ "Event" SG_ 1782 PreSoakCal1WednesdayChange_MMI "true";
BA_ "Unavailable_Value" SG_ 1782 PreSoakCal1WednesdayChange_MMI "0b0";
BA_ "Event" SG_ 1782 PreSoakCal1TuesdayChange_MMI "true";
BA_ "Event" SG_ 1782 PreSoakCal1TuesdayChange_MMI "true";
BA_ "Event" SG_ 1782 PreSoakCal1TuesdayChange_MMI "true";
BA_ "Event" SG_ 1782 PreSoakCal1TuesdayChange_MMI "true";
BA_ "Unavailable_Value" SG_ 1782 PreSoakCal1TuesdayChange_MMI "0b0";
BA_ "Event" SG_ 1782 PreSoakCal1MondayChange_MMI "true";
BA_ "Event" SG_ 1782 PreSoakCal1MondayChange_MMI "true";
BA_ "Event" SG_ 1782 PreSoakCal1MondayChange_MMI "true";
BA_ "Event" SG_ 1782 PreSoakCal1MondayChange_MMI "true";
BA_ "Unavailable_Value" SG_ 1782 PreSoakCal1MondayChange_MMI "0b0";
BA_ "Event" SG_ 1782 PreSoakCal2ArrivalMinChange_MMI "true";
BA_ "Event" SG_ 1782 PreSoakCal2ArrivalMinChange_MMI "true";
BA_ "Event" SG_ 1782 PreSoakCal2ArrivalMinChange_MMI "true";
BA_ "Event" SG_ 1782 PreSoakCal2ArrivalMinChange_MMI "true";
BA_ "Unavailable_Value" SG_ 1782 PreSoakCal2ArrivalMinChange_MMI "0x3F";
BA_ "Event" SG_ 1782 PreSoakCal1SundayChange_MMI "true";
BA_ "Event" SG_ 1782 PreSoakCal1SundayChange_MMI "true";
BA_ "Event" SG_ 1782 PreSoakCal1SundayChange_MMI "true";
BA_ "Event" SG_ 1782 PreSoakCal1SundayChange_MMI "true";
BA_ "Unavailable_Value" SG_ 1782 PreSoakCal1SundayChange_MMI "0b0";
BA_ "Event" SG_ 1782 PreSoakCal1SaturdayChange_MMI "true";
BA_ "Event" SG_ 1782 PreSoakCal1SaturdayChange_MMI "true";
BA_ "Event" SG_ 1782 PreSoakCal1SaturdayChange_MMI "true";
BA_ "Event" SG_ 1782 PreSoakCal1SaturdayChange_MMI "true";
BA_ "Unavailable_Value" SG_ 1782 PreSoakCal1SaturdayChange_MMI "0b0";
BA_ "Event" SG_ 1782 PreSoakCal2WednesdayChange_MMI "true";
BA_ "Event" SG_ 1782 PreSoakCal2WednesdayChange_MMI "true";
BA_ "Event" SG_ 1782 PreSoakCal2WednesdayChange_MMI "true";
BA_ "Event" SG_ 1782 PreSoakCal2WednesdayChange_MMI "true";
BA_ "Unavailable_Value" SG_ 1782 PreSoakCal2WednesdayChange_MMI "0b0";
BA_ "Event" SG_ 1782 PreSoakCal2TuesdayChange_MMI "true";
BA_ "Event" SG_ 1782 PreSoakCal2TuesdayChange_MMI "true";
BA_ "Event" SG_ 1782 PreSoakCal2TuesdayChange_MMI "true";
BA_ "Event" SG_ 1782 PreSoakCal2TuesdayChange_MMI "true";
BA_ "Unavailable_Value" SG_ 1782 PreSoakCal2TuesdayChange_MMI "0b0";
BA_ "Event" SG_ 1782 PreSoakCal2MondayChange_MMI "true";
BA_ "Event" SG_ 1782 PreSoakCal2MondayChange_MMI "true";
BA_ "Event" SG_ 1782 PreSoakCal2MondayChange_MMI "true";
BA_ "Event" SG_ 1782 PreSoakCal2MondayChange_MMI "true";
BA_ "Unavailable_Value" SG_ 1782 PreSoakCal2MondayChange_MMI "0b0";
BA_ "Event" SG_ 1782 PreSoakCal2ArrivalHourChange_MMI "true";
BA_ "Event" SG_ 1782 PreSoakCal2ArrivalHourChange_MMI "true";
BA_ "Event" SG_ 1782 PreSoakCal2ArrivalHourChange_MMI "true";
BA_ "Event" SG_ 1782 PreSoakCal2ArrivalHourChange_MMI "true";
BA_ "Unavailable_Value" SG_ 1782 PreSoakCal2ArrivalHourChange_MMI "0x1F";
BA_ "Event" SG_ 1782 PreSoakCal3ArrivalMinChange_MMI "true";
BA_ "Event" SG_ 1782 PreSoakCal3ArrivalMinChange_MMI "true";
BA_ "Event" SG_ 1782 PreSoakCal3ArrivalMinChange_MMI "true";
BA_ "Event" SG_ 1782 PreSoakCal3ArrivalMinChange_MMI "true";
BA_ "Unavailable_Value" SG_ 1782 PreSoakCal3ArrivalMinChange_MMI "0x3F";
BA_ "Event" SG_ 1782 PreSoakCal2SundayChange_MMI "true";
BA_ "Event" SG_ 1782 PreSoakCal2SundayChange_MMI "true";
BA_ "Event" SG_ 1782 PreSoakCal2SundayChange_MMI "true";
BA_ "Event" SG_ 1782 PreSoakCal2SundayChange_MMI "true";
BA_ "Unavailable_Value" SG_ 1782 PreSoakCal2SundayChange_MMI "0b0";
BA_ "Event" SG_ 1782 PreSoakCal2SaturdayChange_MMI "true";
BA_ "Event" SG_ 1782 PreSoakCal2SaturdayChange_MMI "true";
BA_ "Event" SG_ 1782 PreSoakCal2SaturdayChange_MMI "true";
BA_ "Event" SG_ 1782 PreSoakCal2SaturdayChange_MMI "true";
BA_ "Unavailable_Value" SG_ 1782 PreSoakCal2SaturdayChange_MMI "0b0";
BA_ "Event" SG_ 1782 PreSoakCal2FridayChange_MMI "true";
BA_ "Event" SG_ 1782 PreSoakCal2FridayChange_MMI "true";
BA_ "Event" SG_ 1782 PreSoakCal2FridayChange_MMI "true";
BA_ "Event" SG_ 1782 PreSoakCal2FridayChange_MMI "true";
BA_ "Unavailable_Value" SG_ 1782 PreSoakCal2FridayChange_MMI "0b0";
BA_ "Event" SG_ 1782 PreSoakCal2ThursdayChange_MMI "true";
BA_ "Event" SG_ 1782 PreSoakCal2ThursdayChange_MMI "true";
BA_ "Event" SG_ 1782 PreSoakCal2ThursdayChange_MMI "true";
BA_ "Event" SG_ 1782 PreSoakCal2ThursdayChange_MMI "true";
BA_ "Unavailable_Value" SG_ 1782 PreSoakCal2ThursdayChange_MMI "0b0";
BA_ "Event" SG_ 1782 PreSoakCal3MondayChange_MMI "true";
BA_ "Event" SG_ 1782 PreSoakCal3MondayChange_MMI "true";
BA_ "Event" SG_ 1782 PreSoakCal3MondayChange_MMI "true";
BA_ "Event" SG_ 1782 PreSoakCal3MondayChange_MMI "true";
BA_ "Unavailable_Value" SG_ 1782 PreSoakCal3MondayChange_MMI "0b0";
BA_ "Event" SG_ 1782 PreSoakCal3ArrivalHourChange_MMI "true";
BA_ "Event" SG_ 1782 PreSoakCal3ArrivalHourChange_MMI "true";
BA_ "Event" SG_ 1782 PreSoakCal3ArrivalHourChange_MMI "true";
BA_ "Event" SG_ 1782 PreSoakCal3ArrivalHourChange_MMI "true";
BA_ "Unavailable_Value" SG_ 1782 PreSoakCal3ArrivalHourChange_MMI "0x1F";
BA_ "Event" SG_ 1782 PreSoakCalAllChange_MMI "true";
BA_ "Event" SG_ 1782 PreSoakCalAllChange_MMI "true";
BA_ "Event" SG_ 1782 PreSoakCalAllChange_MMI "true";
BA_ "Event" SG_ 1782 PreSoakCalAllChange_MMI "true";
BA_ "Unavailable_Value" SG_ 1782 PreSoakCalAllChange_MMI "0b00";
BA_ "Event" SG_ 1782 PreSoakCal3SundayChange_MMI "true";
BA_ "Event" SG_ 1782 PreSoakCal3SundayChange_MMI "true";
BA_ "Event" SG_ 1782 PreSoakCal3SundayChange_MMI "true";
BA_ "Event" SG_ 1782 PreSoakCal3SundayChange_MMI "true";
BA_ "Unavailable_Value" SG_ 1782 PreSoakCal3SundayChange_MMI "0b0";
BA_ "Event" SG_ 1782 PreSoakCal3SaturdayChange_MMI "true";
BA_ "Event" SG_ 1782 PreSoakCal3SaturdayChange_MMI "true";
BA_ "Event" SG_ 1782 PreSoakCal3SaturdayChange_MMI "true";
BA_ "Event" SG_ 1782 PreSoakCal3SaturdayChange_MMI "true";
BA_ "Unavailable_Value" SG_ 1782 PreSoakCal3SaturdayChange_MMI "0b0";
BA_ "Event" SG_ 1782 PreSoakCal3FridayChange_MMI "true";
BA_ "Event" SG_ 1782 PreSoakCal3FridayChange_MMI "true";
BA_ "Event" SG_ 1782 PreSoakCal3FridayChange_MMI "true";
BA_ "Event" SG_ 1782 PreSoakCal3FridayChange_MMI "true";
BA_ "Unavailable_Value" SG_ 1782 PreSoakCal3FridayChange_MMI "0b0";
BA_ "Event" SG_ 1782 PreSoakCal3ThursdayChange_MMI "true";
BA_ "Event" SG_ 1782 PreSoakCal3ThursdayChange_MMI "true";
BA_ "Event" SG_ 1782 PreSoakCal3ThursdayChange_MMI "true";
BA_ "Event" SG_ 1782 PreSoakCal3ThursdayChange_MMI "true";
BA_ "Unavailable_Value" SG_ 1782 PreSoakCal3ThursdayChange_MMI "0b0";
BA_ "Event" SG_ 1782 PreSoakCal3WednesdayChange_MMI "true";
BA_ "Event" SG_ 1782 PreSoakCal3WednesdayChange_MMI "true";
BA_ "Event" SG_ 1782 PreSoakCal3WednesdayChange_MMI "true";
BA_ "Event" SG_ 1782 PreSoakCal3WednesdayChange_MMI "true";
BA_ "Unavailable_Value" SG_ 1782 PreSoakCal3WednesdayChange_MMI "0b0";
BA_ "Event" SG_ 1782 PreSoakCal3TuesdayChange_MMI "true";
BA_ "Event" SG_ 1782 PreSoakCal3TuesdayChange_MMI "true";
BA_ "Event" SG_ 1782 PreSoakCal3TuesdayChange_MMI "true";
BA_ "Event" SG_ 1782 PreSoakCal3TuesdayChange_MMI "true";
BA_ "Unavailable_Value" SG_ 1782 PreSoakCal3TuesdayChange_MMI "0b0";
BA_ "Event" SG_ 1783 PreSoakCal4ArrivalHourChange_MMI "true";
BA_ "Event" SG_ 1783 PreSoakCal4ArrivalHourChange_MMI "true";
BA_ "Event" SG_ 1783 PreSoakCal4ArrivalHourChange_MMI "true";
BA_ "Event" SG_ 1783 PreSoakCal4ArrivalHourChange_MMI "true";
BA_ "Unavailable_Value" SG_ 1783 PreSoakCal4ArrivalHourChange_MMI "0x1F";
BA_ "Event" SG_ 1783 PreSoakCal4ArrivalMinChange_MMI "true";
BA_ "Event" SG_ 1783 PreSoakCal4ArrivalMinChange_MMI "true";
BA_ "Event" SG_ 1783 PreSoakCal4ArrivalMinChange_MMI "true";
BA_ "Event" SG_ 1783 PreSoakCal4ArrivalMinChange_MMI "true";
BA_ "Unavailable_Value" SG_ 1783 PreSoakCal4ArrivalMinChange_MMI "0x3F";
BA_ "Event" SG_ 1783 PreSoakCal4FridayChange_MMI "true";
BA_ "Event" SG_ 1783 PreSoakCal4FridayChange_MMI "true";
BA_ "Event" SG_ 1783 PreSoakCal4FridayChange_MMI "true";
BA_ "Event" SG_ 1783 PreSoakCal4FridayChange_MMI "true";
BA_ "Unavailable_Value" SG_ 1783 PreSoakCal4FridayChange_MMI "0b0";
BA_ "Event" SG_ 1783 PreSoakCal4ThursdayChange_MMI "true";
BA_ "Event" SG_ 1783 PreSoakCal4ThursdayChange_MMI "true";
BA_ "Event" SG_ 1783 PreSoakCal4ThursdayChange_MMI "true";
BA_ "Event" SG_ 1783 PreSoakCal4ThursdayChange_MMI "true";
BA_ "Unavailable_Value" SG_ 1783 PreSoakCal4ThursdayChange_MMI "0b0";
BA_ "Event" SG_ 1783 PreSoakCal4WednesdayChange_MMI "true";
BA_ "Event" SG_ 1783 PreSoakCal4WednesdayChange_MMI "true";
BA_ "Event" SG_ 1783 PreSoakCal4WednesdayChange_MMI "true";
BA_ "Event" SG_ 1783 PreSoakCal4WednesdayChange_MMI "true";
BA_ "Unavailable_Value" SG_ 1783 PreSoakCal4WednesdayChange_MMI "0b0";
BA_ "Event" SG_ 1783 PreSoakCal4TuesdayChange_MMI "true";
BA_ "Event" SG_ 1783 PreSoakCal4TuesdayChange_MMI "true";
BA_ "Event" SG_ 1783 PreSoakCal4TuesdayChange_MMI "true";
BA_ "Event" SG_ 1783 PreSoakCal4TuesdayChange_MMI "true";
BA_ "Unavailable_Value" SG_ 1783 PreSoakCal4TuesdayChange_MMI "0b0";
BA_ "Event" SG_ 1783 PreSoakCal4MondayChange_MMI "true";
BA_ "Event" SG_ 1783 PreSoakCal4MondayChange_MMI "true";
BA_ "Event" SG_ 1783 PreSoakCal4MondayChange_MMI "true";
BA_ "Event" SG_ 1783 PreSoakCal4MondayChange_MMI "true";
BA_ "Unavailable_Value" SG_ 1783 PreSoakCal4MondayChange_MMI "0b0";
BA_ "Event" SG_ 1783 PreSoakCal5ArrivalMinChange_MMI "true";
BA_ "Event" SG_ 1783 PreSoakCal5ArrivalMinChange_MMI "true";
BA_ "Event" SG_ 1783 PreSoakCal5ArrivalMinChange_MMI "true";
BA_ "Event" SG_ 1783 PreSoakCal5ArrivalMinChange_MMI "true";
BA_ "Unavailable_Value" SG_ 1783 PreSoakCal5ArrivalMinChange_MMI "0x3F";
BA_ "Event" SG_ 1783 PreSoakCal4SundayChange_MMI "true";
BA_ "Event" SG_ 1783 PreSoakCal4SundayChange_MMI "true";
BA_ "Event" SG_ 1783 PreSoakCal4SundayChange_MMI "true";
BA_ "Event" SG_ 1783 PreSoakCal4SundayChange_MMI "true";
BA_ "Unavailable_Value" SG_ 1783 PreSoakCal4SundayChange_MMI "0b0";
BA_ "Event" SG_ 1783 PreSoakCal4SaturdayChange_MMI "true";
BA_ "Event" SG_ 1783 PreSoakCal4SaturdayChange_MMI "true";
BA_ "Event" SG_ 1783 PreSoakCal4SaturdayChange_MMI "true";
BA_ "Event" SG_ 1783 PreSoakCal4SaturdayChange_MMI "true";
BA_ "Unavailable_Value" SG_ 1783 PreSoakCal4SaturdayChange_MMI "0b0";
BA_ "Event" SG_ 1783 PreSoakCal5WednesdayChange_MMI "true";
BA_ "Event" SG_ 1783 PreSoakCal5WednesdayChange_MMI "true";
BA_ "Event" SG_ 1783 PreSoakCal5WednesdayChange_MMI "true";
BA_ "Event" SG_ 1783 PreSoakCal5WednesdayChange_MMI "true";
BA_ "Unavailable_Value" SG_ 1783 PreSoakCal5WednesdayChange_MMI "0b0";
BA_ "Event" SG_ 1783 PreSoakCal5TuesdayChange_MMI "true";
BA_ "Event" SG_ 1783 PreSoakCal5TuesdayChange_MMI "true";
BA_ "Event" SG_ 1783 PreSoakCal5TuesdayChange_MMI "true";
BA_ "Event" SG_ 1783 PreSoakCal5TuesdayChange_MMI "true";
BA_ "Unavailable_Value" SG_ 1783 PreSoakCal5TuesdayChange_MMI "0b0";
BA_ "Event" SG_ 1783 PreSoakCal5MondayChange_MMI "true";
BA_ "Event" SG_ 1783 PreSoakCal5MondayChange_MMI "true";
BA_ "Event" SG_ 1783 PreSoakCal5MondayChange_MMI "true";
BA_ "Event" SG_ 1783 PreSoakCal5MondayChange_MMI "true";
BA_ "Unavailable_Value" SG_ 1783 PreSoakCal5MondayChange_MMI "0b0";
BA_ "Event" SG_ 1783 PreSoakCal5ArrivalHourChange_MMI "true";
BA_ "Event" SG_ 1783 PreSoakCal5ArrivalHourChange_MMI "true";
BA_ "Event" SG_ 1783 PreSoakCal5ArrivalHourChange_MMI "true";
BA_ "Event" SG_ 1783 PreSoakCal5ArrivalHourChange_MMI "true";
BA_ "Unavailable_Value" SG_ 1783 PreSoakCal5ArrivalHourChange_MMI "0x1F";
BA_ "Unavailable_Value" SG_ 1783 GainECOdistanceDisplay "0x1FFF";
BA_ "Event" SG_ 1783 PreSoakCal5SundayChange_MMI "true";
BA_ "Event" SG_ 1783 PreSoakCal5SundayChange_MMI "true";
BA_ "Event" SG_ 1783 PreSoakCal5SundayChange_MMI "true";
BA_ "Event" SG_ 1783 PreSoakCal5SundayChange_MMI "true";
BA_ "Unavailable_Value" SG_ 1783 PreSoakCal5SundayChange_MMI "0b0";
BA_ "Event" SG_ 1783 PreSoakCal5SaturdayChange_MMI "true";
BA_ "Event" SG_ 1783 PreSoakCal5SaturdayChange_MMI "true";
BA_ "Event" SG_ 1783 PreSoakCal5SaturdayChange_MMI "true";
BA_ "Event" SG_ 1783 PreSoakCal5SaturdayChange_MMI "true";
BA_ "Unavailable_Value" SG_ 1783 PreSoakCal5SaturdayChange_MMI "0b0";
BA_ "Event" SG_ 1783 PreSoakCal5FridayChange_MMI "true";
BA_ "Event" SG_ 1783 PreSoakCal5FridayChange_MMI "true";
BA_ "Event" SG_ 1783 PreSoakCal5FridayChange_MMI "true";
BA_ "Event" SG_ 1783 PreSoakCal5FridayChange_MMI "true";
BA_ "Unavailable_Value" SG_ 1783 PreSoakCal5FridayChange_MMI "0b0";
BA_ "Event" SG_ 1783 PreSoakCal5ThursdayChange_MMI "true";
BA_ "Event" SG_ 1783 PreSoakCal5ThursdayChange_MMI "true";
BA_ "Event" SG_ 1783 PreSoakCal5ThursdayChange_MMI "true";
BA_ "Event" SG_ 1783 PreSoakCal5ThursdayChange_MMI "true";
BA_ "Unavailable_Value" SG_ 1783 PreSoakCal5ThursdayChange_MMI "0b0";
BA_ "Event" SG_ 1789 VolumAlarmActivationState "true";
BA_ "Event" SG_ 1789 VolumAlarmActivationState "true";
BA_ "Event" SG_ 1789 VolumAlarmActivationState "true";
BA_ "Event" SG_ 1789 VolumAlarmActivationState "true";
BA_ "Unavailable_Value" SG_ 1789 VolumAlarmActivationState "0b000";
BA_ "Event" SG_ 1789 RESPreSoak_NextDriverArrivalTime_v2 "true";
BA_ "Event" SG_ 1789 RESPreSoak_NextDriverArrivalTime_v2 "true";
BA_ "Event" SG_ 1789 RESPreSoak_NextDriverArrivalTime_v2 "true";
BA_ "Event" SG_ 1789 RESPreSoak_NextDriverArrivalTime_v2 "true";
BA_ "Unavailable_Value" SG_ 1789 RESPreSoak_NextDriverArrivalTime_v2 "0x3FFF";
BA_ "Event" SG_ 1789 FOTA_ProgValueStatus "true";
BA_ "Event" SG_ 1789 FOTA_ProgValueStatus "true";
BA_ "Event" SG_ 1789 FOTA_ProgValueStatus "true";
BA_ "Event" SG_ 1789 FOTA_ProgValueStatus "true";
BA_ "Unavailable_Value" SG_ 1789 FOTA_ProgValueStatus "0x7FF";
BA_ "Event" SG_ 1789 FOTA_TimerExpiredStatus "true";
BA_ "Event" SG_ 1789 FOTA_TimerExpiredStatus "true";
BA_ "Event" SG_ 1789 FOTA_TimerExpiredStatus "true";
BA_ "Event" SG_ 1789 FOTA_TimerExpiredStatus "true";
BA_ "Unavailable_Value" SG_ 1789 FOTA_TimerExpiredStatus "0b0";
BA_ "Event" SG_ 1789 FOTA_ProgStatus "true";
BA_ "Event" SG_ 1789 FOTA_ProgStatus "true";
BA_ "Event" SG_ 1789 FOTA_ProgStatus "true";
BA_ "Event" SG_ 1789 FOTA_ProgStatus "true";
BA_ "Unavailable_Value" SG_ 1789 FOTA_ProgStatus "0b0";
BA_ "Event" SG_ 1789 ChargeDelayedValue_V2 "true";
BA_ "Event" SG_ 1789 ChargeDelayedValue_V2 "true";
BA_ "Event" SG_ 1789 ChargeDelayedValue_V2 "true";
BA_ "Event" SG_ 1789 ChargeDelayedValue_V2 "true";
BA_ "Unavailable_Value" SG_ 1789 ChargeDelayedValue_V2 "0x3FFF";
BA_ "Event" SG_ 1790 EPOIspotInstantPowerMeasured "true";
BA_ "Event" SG_ 1790 EPOIspotInstantPowerMeasured "true";
BA_ "Event" SG_ 1790 EPOIspotInstantPowerMeasured "true";
BA_ "Event" SG_ 1790 EPOIspotInstantPowerMeasured "true";
BA_ "Unavailable_Value" SG_ 1790 EPOIspotInstantPowerMeasured "0x1FF";
BA_ "Event" SG_ 1790 RST_BMSTrackAuthorization "true";
BA_ "Event" SG_ 1790 RST_BMSTrackAuthorization "true";
BA_ "Event" SG_ 1790 RST_BMSTrackAuthorization "true";
BA_ "Event" SG_ 1790 RST_BMSTrackAuthorization "true";
BA_ "Unavailable_Value" SG_ 1790 RST_BMSTrackAuthorization "0b0";
BA_ "Unavailable_Value" SG_ 1790 PnCchargeStationCompatibility "0b0";
BA_ "Event" SG_ 1791 FuelSaveSinceClearHistoZEV "true";
BA_ "Event" SG_ 1791 FuelSaveSinceClearHistoZEV "true";
BA_ "Event" SG_ 1791 FuelSaveSinceClearHistoZEV "true";
BA_ "Event" SG_ 1791 FuelSaveSinceClearHistoZEV "true";
BA_ "Unavailable_Value" SG_ 1791 FuelSaveSinceClearHistoZEV "0x3FFF";
BA_ "Unavailable_Value" SG_ 1812 DTOOL_to_CPANEL "null";
BA_ "Unavailable_Value" SG_ 1844 CPANEL_to_DTOOL "null";
BA_ "Unavailable_Value" SG_ 1863 DTOOL_to_NAV "null";
BA_ "Unavailable_Value" SG_ 1895 NAV_to_DTOOL "null";
BA_ "Event" SG_ 2563507968 SIGMA_CDM "true";
BA_ "Event" SG_ 2563507968 SIGMA_CDM "true";
BA_ "Event" SG_ 2563507968 SIGMA_CDM "true";
BA_ "Event" SG_ 2563507968 SIGMA_CDM "true";
BA_ "Event" SG_ 2563507968 SIGMA_DTCCDM "true";
BA_ "Event" SG_ 2563507968 SIGMA_DTCCDM "true";
BA_ "Event" SG_ 2563507968 SIGMA_DTCCDM "true";
BA_ "Event" SG_ 2563507968 SIGMA_DTCCDM "true";
BA_ "Event" SG_ 2563508019 SIGMA_PBD "true";
BA_ "Event" SG_ 2563508019 SIGMA_PBD "true";
BA_ "Event" SG_ 2563508019 SIGMA_PBD "true";
BA_ "Event" SG_ 2563508019 SIGMA_PBD "true";
BA_ "Event" SG_ 2563508019 SIGMA_DTCPBD "true";
BA_ "Event" SG_ 2563508019 SIGMA_DTCPBD "true";
BA_ "Event" SG_ 2563508019 SIGMA_DTCPBD "true";
BA_ "Event" SG_ 2563508019 SIGMA_DTCPBD "true";
BA_ "Event" SG_ 2563508021 SIGMA_RADAR "true";
BA_ "Event" SG_ 2563508021 SIGMA_RADAR "true";
BA_ "Event" SG_ 2563508021 SIGMA_RADAR "true";
BA_ "Event" SG_ 2563508021 SIGMA_RADAR "true";
BA_ "Event" SG_ 2563508021 SIGMA_DTCRADAR "true";
BA_ "Event" SG_ 2563508021 SIGMA_DTCRADAR "true";
BA_ "Event" SG_ 2563508021 SIGMA_DTCRADAR "true";
BA_ "Event" SG_ 2563508021 SIGMA_DTCRADAR "true";
BA_ "Event" SG_ 2563508022 SIGMA_PSCU "true";
BA_ "Event" SG_ 2563508022 SIGMA_PSCU "true";
BA_ "Event" SG_ 2563508022 SIGMA_PSCU "true";
BA_ "Event" SG_ 2563508022 SIGMA_PSCU "true";
BA_ "Event" SG_ 2563508022 SIGMA_DTCPSCU "true";
BA_ "Event" SG_ 2563508022 SIGMA_DTCPSCU "true";
BA_ "Event" SG_ 2563508022 SIGMA_DTCPSCU "true";
BA_ "Event" SG_ 2563508022 SIGMA_DTCPSCU "true";
BA_ "Event" SG_ 2563508030 SIGMA_SRad_RL "true";
BA_ "Event" SG_ 2563508030 SIGMA_SRad_RL "true";
BA_ "Event" SG_ 2563508030 SIGMA_SRad_RL "true";
BA_ "Event" SG_ 2563508030 SIGMA_SRad_RL "true";
BA_ "Event" SG_ 2563508030 SIGMA_DTCSRad_RL "true";
BA_ "Event" SG_ 2563508030 SIGMA_DTCSRad_RL "true";
BA_ "Event" SG_ 2563508030 SIGMA_DTCSRad_RL "true";
BA_ "Event" SG_ 2563508030 SIGMA_DTCSRad_RL "true";
BA_ "Event" SG_ 2563508042 SIGMA_ANC "true";
BA_ "Event" SG_ 2563508042 SIGMA_ANC "true";
BA_ "Event" SG_ 2563508042 SIGMA_ANC "true";
BA_ "Event" SG_ 2563508042 SIGMA_ANC "true";
BA_ "Event" SG_ 2563508042 SIGMA_DTCANC "true";
BA_ "Event" SG_ 2563508042 SIGMA_DTCANC "true";
BA_ "Event" SG_ 2563508042 SIGMA_DTCANC "true";
BA_ "Event" SG_ 2563508042 SIGMA_DTCANC "true";
BA_ "Event" SG_ 2563508064 SIGMA_VDC "true";
BA_ "Event" SG_ 2563508064 SIGMA_VDC "true";
BA_ "Event" SG_ 2563508064 SIGMA_VDC "true";
BA_ "Event" SG_ 2563508064 SIGMA_VDC "true";
BA_ "Event" SG_ 2563508064 SIGMA_DTCVDC "true";
BA_ "Event" SG_ 2563508064 SIGMA_DTCVDC "true";
BA_ "Event" SG_ 2563508064 SIGMA_DTCVDC "true";
BA_ "Event" SG_ 2563508064 SIGMA_DTCVDC "true";
BA_ "Event" SG_ 2563508066 SIGMA_EPS "true";
BA_ "Event" SG_ 2563508066 SIGMA_EPS "true";
BA_ "Event" SG_ 2563508066 SIGMA_EPS "true";
BA_ "Event" SG_ 2563508066 SIGMA_EPS "true";
BA_ "Event" SG_ 2563508066 SIGMA_DTCEPS "true";
BA_ "Event" SG_ 2563508066 SIGMA_DTCEPS "true";
BA_ "Event" SG_ 2563508066 SIGMA_DTCEPS "true";
BA_ "Event" SG_ 2563508066 SIGMA_DTCEPS "true";
BA_ "Event" SG_ 2563508067 SIGMA_METER "true";
BA_ "Event" SG_ 2563508067 SIGMA_METER "true";
BA_ "Event" SG_ 2563508067 SIGMA_METER "true";
BA_ "Event" SG_ 2563508067 SIGMA_METER "true";
BA_ "Event" SG_ 2563508067 SIGMA_DTCMETER "true";
BA_ "Event" SG_ 2563508067 SIGMA_DTCMETER "true";
BA_ "Event" SG_ 2563508067 SIGMA_DTCMETER "true";
BA_ "Event" SG_ 2563508067 SIGMA_DTCMETER "true";
BA_ "Event" SG_ 2563508068 SIGMA_HVAC "true";
BA_ "Event" SG_ 2563508068 SIGMA_HVAC "true";
BA_ "Event" SG_ 2563508068 SIGMA_HVAC "true";
BA_ "Event" SG_ 2563508068 SIGMA_HVAC "true";
BA_ "Event" SG_ 2563508068 SIGMA_DTCHVAC "true";
BA_ "Event" SG_ 2563508068 SIGMA_DTCHVAC "true";
BA_ "Event" SG_ 2563508068 SIGMA_DTCHVAC "true";
BA_ "Event" SG_ 2563508068 SIGMA_DTCHVAC "true";
BA_ "Event" SG_ 2563508069 SIGMA_BCM "true";
BA_ "Event" SG_ 2563508069 SIGMA_BCM "true";
BA_ "Event" SG_ 2563508069 SIGMA_BCM "true";
BA_ "Event" SG_ 2563508069 SIGMA_BCM "true";
BA_ "Unavailable_Value" SG_ 2563508069 SIGMA_BCM "null";
BA_ "Event" SG_ 2563508069 SIGMA_DTCBCM "true";
BA_ "Event" SG_ 2563508069 SIGMA_DTCBCM "true";
BA_ "Event" SG_ 2563508069 SIGMA_DTCBCM "true";
BA_ "Event" SG_ 2563508069 SIGMA_DTCBCM "true";
BA_ "Event" SG_ 2563508071 SIGMA_IVI "true";
BA_ "Event" SG_ 2563508071 SIGMA_IVI "true";
BA_ "Event" SG_ 2563508071 SIGMA_IVI "true";
BA_ "Event" SG_ 2563508071 SIGMA_IVI "true";
BA_ "Unavailable_Value" SG_ 2563508071 SIGMA_IVI "null";
BA_ "Event" SG_ 2563508071 SIGMA_DTCIVI "true";
BA_ "Event" SG_ 2563508071 SIGMA_DTCIVI "true";
BA_ "Event" SG_ 2563508071 SIGMA_DTCIVI "true";
BA_ "Event" SG_ 2563508071 SIGMA_DTCIVI "true";
BA_ "Event" SG_ 2563508072 SIGMA_4WD "true";
BA_ "Event" SG_ 2563508072 SIGMA_4WD "true";
BA_ "Event" SG_ 2563508072 SIGMA_4WD "true";
BA_ "Event" SG_ 2563508072 SIGMA_4WD "true";
BA_ "Event" SG_ 2563508072 SIGMA_DTC4WD "true";
BA_ "Event" SG_ 2563508072 SIGMA_DTC4WD "true";
BA_ "Event" SG_ 2563508072 SIGMA_DTC4WD "true";
BA_ "Event" SG_ 2563508072 SIGMA_DTC4WD "true";
BA_ "Event" SG_ 2563508077 SIGMA_USM "true";
BA_ "Event" SG_ 2563508077 SIGMA_USM "true";
BA_ "Event" SG_ 2563508077 SIGMA_USM "true";
BA_ "Event" SG_ 2563508077 SIGMA_USM "true";
BA_ "Unavailable_Value" SG_ 2563508077 SIGMA_USM "null";
BA_ "Event" SG_ 2563508077 SIGMA_DTCUSM "true";
BA_ "Event" SG_ 2563508077 SIGMA_DTCUSM "true";
BA_ "Event" SG_ 2563508077 SIGMA_DTCUSM "true";
BA_ "Event" SG_ 2563508077 SIGMA_DTCUSM "true";
BA_ "Event" SG_ 2563508078 SIGMA_SONAR "true";
BA_ "Event" SG_ 2563508078 SIGMA_SONAR "true";
BA_ "Event" SG_ 2563508078 SIGMA_SONAR "true";
BA_ "Event" SG_ 2563508078 SIGMA_SONAR "true";
BA_ "Event" SG_ 2563508078 SIGMA_DTCSONAR "true";
BA_ "Event" SG_ 2563508078 SIGMA_DTCSONAR "true";
BA_ "Event" SG_ 2563508078 SIGMA_DTCSONAR "true";
BA_ "Event" SG_ 2563508078 SIGMA_DTCSONAR "true";
BA_ "Event" SG_ 2563508079 SIGMA_DSMU "true";
BA_ "Event" SG_ 2563508079 SIGMA_DSMU "true";
BA_ "Event" SG_ 2563508079 SIGMA_DSMU "true";
BA_ "Event" SG_ 2563508079 SIGMA_DSMU "true";
BA_ "Event" SG_ 2563508079 SIGMA_DTCDSMU "true";
BA_ "Event" SG_ 2563508079 SIGMA_DTCDSMU "true";
BA_ "Event" SG_ 2563508079 SIGMA_DTCDSMU "true";
BA_ "Event" SG_ 2563508079 SIGMA_DTCDSMU "true";
BA_ "Event" SG_ 2563508082 SIGMA_ACU "true";
BA_ "Event" SG_ 2563508082 SIGMA_ACU "true";
BA_ "Event" SG_ 2563508082 SIGMA_ACU "true";
BA_ "Event" SG_ 2563508082 SIGMA_ACU "true";
BA_ "Event" SG_ 2563508082 SIGMA_DTCACU "true";
BA_ "Event" SG_ 2563508082 SIGMA_DTCACU "true";
BA_ "Event" SG_ 2563508082 SIGMA_DTCACU "true";
BA_ "Event" SG_ 2563508082 SIGMA_DTCACU "true";
BA_ "Event" SG_ 2563508093 SIGMA_ADAS "true";
BA_ "Event" SG_ 2563508093 SIGMA_ADAS "true";
BA_ "Event" SG_ 2563508093 SIGMA_ADAS "true";
BA_ "Event" SG_ 2563508093 SIGMA_ADAS "true";
BA_ "Event" SG_ 2563508093 SIGMA_DTCADAS "true";
BA_ "Event" SG_ 2563508093 SIGMA_DTCADAS "true";
BA_ "Event" SG_ 2563508093 SIGMA_DTCADAS "true";
BA_ "Event" SG_ 2563508093 SIGMA_DTCADAS "true";
BA_ "Event" SG_ 2563508099 SIGMA_A_IVC "true";
BA_ "Event" SG_ 2563508099 SIGMA_A_IVC "true";
BA_ "Event" SG_ 2563508099 SIGMA_A_IVC "true";
BA_ "Event" SG_ 2563508099 SIGMA_A_IVC "true";
BA_ "Event" SG_ 2563508099 SIGMA_DTCA_IVC "true";
BA_ "Event" SG_ 2563508099 SIGMA_DTCA_IVC "true";
BA_ "Event" SG_ 2563508099 SIGMA_DTCA_IVC "true";
BA_ "Event" SG_ 2563508099 SIGMA_DTCA_IVC "true";
BA_ "Event" SG_ 2563508108 SIGMA_INV_ME "true";
BA_ "Event" SG_ 2563508108 SIGMA_INV_ME "true";
BA_ "Event" SG_ 2563508108 SIGMA_INV_ME "true";
BA_ "Event" SG_ 2563508108 SIGMA_INV_ME "true";
BA_ "Event" SG_ 2563508108 SIGMA_DTCINV_ME "true";
BA_ "Event" SG_ 2563508108 SIGMA_DTCINV_ME "true";
BA_ "Event" SG_ 2563508108 SIGMA_DTCINV_ME "true";
BA_ "Event" SG_ 2563508108 SIGMA_DTCINV_ME "true";
BA_ "Event" SG_ 2563508115 SIGMA_OBC_AC "true";
BA_ "Event" SG_ 2563508115 SIGMA_OBC_AC "true";
BA_ "Event" SG_ 2563508115 SIGMA_OBC_AC "true";
BA_ "Event" SG_ 2563508115 SIGMA_OBC_AC "true";
BA_ "Event" SG_ 2563508115 SIGMA_DTCOBC_AC "true";
BA_ "Event" SG_ 2563508115 SIGMA_DTCOBC_AC "true";
BA_ "Event" SG_ 2563508115 SIGMA_DTCOBC_AC "true";
BA_ "Event" SG_ 2563508115 SIGMA_DTCOBC_AC "true";
BA_ "Event" SG_ 2563508122 SIGMA_HEVC "true";
BA_ "Event" SG_ 2563508122 SIGMA_HEVC "true";
BA_ "Event" SG_ 2563508122 SIGMA_HEVC "true";
BA_ "Event" SG_ 2563508122 SIGMA_HEVC "true";
BA_ "Event" SG_ 2563508122 SIGMA_DTCHEVC "true";
BA_ "Event" SG_ 2563508122 SIGMA_DTCHEVC "true";
BA_ "Event" SG_ 2563508122 SIGMA_DTCHEVC "true";
BA_ "Event" SG_ 2563508122 SIGMA_DTCHEVC "true";
BA_ "Event" SG_ 2563508130 SIGMA_AUDIOamp "true";
BA_ "Event" SG_ 2563508130 SIGMA_AUDIOamp "true";
BA_ "Event" SG_ 2563508130 SIGMA_AUDIOamp "true";
BA_ "Event" SG_ 2563508130 SIGMA_AUDIOamp "true";
BA_ "Event" SG_ 2563508130 SIGMA_DTCAUDIOamp "true";
BA_ "Event" SG_ 2563508130 SIGMA_DTCAUDIOamp "true";
BA_ "Event" SG_ 2563508130 SIGMA_DTCAUDIOamp "true";
BA_ "Event" SG_ 2563508130 SIGMA_DTCAUDIOamp "true";
BA_ "Event" SG_ 2563508133 SIGMA_HNS "true";
BA_ "Event" SG_ 2563508133 SIGMA_HNS "true";
BA_ "Event" SG_ 2563508133 SIGMA_HNS "true";
BA_ "Event" SG_ 2563508133 SIGMA_HNS "true";
BA_ "Event" SG_ 2563508133 SIGMA_DTCHNS "true";
BA_ "Event" SG_ 2563508133 SIGMA_DTCHNS "true";
BA_ "Event" SG_ 2563508133 SIGMA_DTCHNS "true";
BA_ "Event" SG_ 2563508133 SIGMA_DTCHNS "true";
BA_ "Event" SG_ 2563508153 SIGMA_HFM "true";
BA_ "Event" SG_ 2563508153 SIGMA_HFM "true";
BA_ "Event" SG_ 2563508153 SIGMA_HFM "true";
BA_ "Event" SG_ 2563508153 SIGMA_HFM "true";
BA_ "Unavailable_Value" SG_ 2563508153 SIGMA_HFM "null";
BA_ "Event" SG_ 2563508153 SIGMA_DTCHFM "true";
BA_ "Event" SG_ 2563508153 SIGMA_DTCHFM "true";
BA_ "Event" SG_ 2563508153 SIGMA_DTCHFM "true";
BA_ "Event" SG_ 2563508153 SIGMA_DTCHFM "true";
BA_ "Event" SG_ 2563508154 SIGMA_AVM "true";
BA_ "Event" SG_ 2563508154 SIGMA_AVM "true";
BA_ "Event" SG_ 2563508154 SIGMA_AVM "true";
BA_ "Event" SG_ 2563508154 SIGMA_AVM "true";
BA_ "Event" SG_ 2563508154 SIGMA_DTCAVM "true";
BA_ "Event" SG_ 2563508154 SIGMA_DTCAVM "true";
BA_ "Event" SG_ 2563508154 SIGMA_DTCAVM "true";
BA_ "Event" SG_ 2563508154 SIGMA_DTCAVM "true";
BA_ "Event" SG_ 2563508157 SIGMA_SCU "true";
BA_ "Event" SG_ 2563508157 SIGMA_SCU "true";
BA_ "Event" SG_ 2563508157 SIGMA_SCU "true";
BA_ "Event" SG_ 2563508157 SIGMA_SCU "true";
BA_ "Event" SG_ 2563508157 SIGMA_DTCSCU "true";
BA_ "Event" SG_ 2563508157 SIGMA_DTCSCU "true";
BA_ "Event" SG_ 2563508157 SIGMA_DTCSCU "true";
BA_ "Event" SG_ 2563508157 SIGMA_DTCSCU "true";
BA_ "Event" SG_ 2563508181 SIGMA_SRad_RR "true";
BA_ "Event" SG_ 2563508181 SIGMA_SRad_RR "true";
BA_ "Event" SG_ 2563508181 SIGMA_SRad_RR "true";
BA_ "Event" SG_ 2563508181 SIGMA_SRad_RR "true";
BA_ "Event" SG_ 2563508181 SIGMA_DTCSRad_RR "true";
BA_ "Event" SG_ 2563508181 SIGMA_DTCSRad_RR "true";
BA_ "Event" SG_ 2563508181 SIGMA_DTCSRad_RR "true";
BA_ "Event" SG_ 2563508181 SIGMA_DTCSRad_RR "true";
BA_ "Event" SG_ 2563508189 SIGMA_FrCamera "true";
BA_ "Event" SG_ 2563508189 SIGMA_FrCamera "true";
BA_ "Event" SG_ 2563508189 SIGMA_FrCamera "true";
BA_ "Event" SG_ 2563508189 SIGMA_FrCamera "true";
BA_ "Event" SG_ 2563508189 SIGMA_DTCFrCamera "true";
BA_ "Event" SG_ 2563508189 SIGMA_DTCFrCamera "true";
BA_ "Event" SG_ 2563508189 SIGMA_DTCFrCamera "true";
BA_ "Event" SG_ 2563508189 SIGMA_DTCFrCamera "true";
BA_ "Event" SG_ 2563508200 SIGMA_ECM "true";
BA_ "Event" SG_ 2563508200 SIGMA_ECM "true";
BA_ "Event" SG_ 2563508200 SIGMA_ECM "true";
BA_ "Event" SG_ 2563508200 SIGMA_ECM "true";
BA_ "Event" SG_ 2563508200 SIGMA_DTCECM "true";
BA_ "Event" SG_ 2563508200 SIGMA_DTCECM "true";
BA_ "Event" SG_ 2563508200 SIGMA_DTCECM "true";
BA_ "Event" SG_ 2563508200 SIGMA_DTCECM "true";
BA_ "Event" SG_ 2563508201 SIGMA_ATCU "true";
BA_ "Event" SG_ 2563508201 SIGMA_ATCU "true";
BA_ "Event" SG_ 2563508201 SIGMA_ATCU "true";
BA_ "Event" SG_ 2563508201 SIGMA_ATCU "true";
BA_ "Event" SG_ 2563508201 SIGMA_DTCATCU "true";
BA_ "Event" SG_ 2563508201 SIGMA_DTCATCU "true";
BA_ "Event" SG_ 2563508201 SIGMA_DTCATCU "true";
BA_ "Event" SG_ 2563508201 SIGMA_DTCATCU "true";
BA_ "Event" SG_ 2563508205 SIGMA_BMS_HV "true";
BA_ "Event" SG_ 2563508205 SIGMA_BMS_HV "true";
BA_ "Event" SG_ 2563508205 SIGMA_BMS_HV "true";
BA_ "Event" SG_ 2563508205 SIGMA_BMS_HV "true";
BA_ "Event" SG_ 2563508205 SIGMA_DTCBMS_HV "true";
BA_ "Event" SG_ 2563508205 SIGMA_DTCBMS_HV "true";
BA_ "Event" SG_ 2563508205 SIGMA_DTCBMS_HV "true";
BA_ "Event" SG_ 2563508205 SIGMA_DTCBMS_HV "true";
BA_ "Event" SG_ 2563508207 SIGMA_INV_HSG "true";
BA_ "Event" SG_ 2563508207 SIGMA_INV_HSG "true";
BA_ "Event" SG_ 2563508207 SIGMA_INV_HSG "true";
BA_ "Event" SG_ 2563508207 SIGMA_INV_HSG "true";
BA_ "Event" SG_ 2563508207 SIGMA_DTCINV_HSG "true";
BA_ "Event" SG_ 2563508207 SIGMA_DTCINV_HSG "true";
BA_ "Event" SG_ 2563508207 SIGMA_DTCINV_HSG "true";
BA_ "Event" SG_ 2563508207 SIGMA_DTCINV_HSG "true";
BA_ "Event" SG_ 2563567883 SIGMA_BMS_12V "true";
BA_ "Event" SG_ 2563567883 SIGMA_BMS_12V "true";
BA_ "Event" SG_ 2563567883 SIGMA_BMS_12V "true";
BA_ "Event" SG_ 2563567883 SIGMA_BMS_12V "true";
BA_ "Event" SG_ 2563567883 SIGMA_DTCBMS_12V "true";
BA_ "Event" SG_ 2563567883 SIGMA_DTCBMS_12V "true";
BA_ "Event" SG_ 2563567883 SIGMA_DTCBMS_12V "true";
BA_ "Event" SG_ 2563567883 SIGMA_DTCBMS_12V "true";
BA_ "Event" SG_ 2563567951 SIGMA_EPS_sub "true";
BA_ "Event" SG_ 2563567951 SIGMA_EPS_sub "true";
BA_ "Event" SG_ 2563567951 SIGMA_EPS_sub "true";
BA_ "Event" SG_ 2563567951 SIGMA_EPS_sub "true";
BA_ "Event" SG_ 2563567951 SIGMA_DTCEPS_sub "true";
BA_ "Event" SG_ 2563567951 SIGMA_DTCEPS_sub "true";
BA_ "Event" SG_ 2563567951 SIGMA_DTCEPS_sub "true";
BA_ "Event" SG_ 2563567951 SIGMA_DTCEPS_sub "true";
BA_ "Event" SG_ 2563567968 SIGMA_HUD "true";
BA_ "Event" SG_ 2563567968 SIGMA_HUD "true";
BA_ "Event" SG_ 2563567968 SIGMA_HUD "true";
BA_ "Event" SG_ 2563567968 SIGMA_HUD "true";
BA_ "Event" SG_ 2563567968 SIGMA_DTCHUD "true";
BA_ "Event" SG_ 2563567968 SIGMA_DTCHUD "true";
BA_ "Event" SG_ 2563567968 SIGMA_DTCHUD "true";
BA_ "Event" SG_ 2563567968 SIGMA_DTCHUD "true";
BA_ "Event" SG_ 2563568024 SIGMA_HPCU "true";
BA_ "Event" SG_ 2563568024 SIGMA_HPCU "true";
BA_ "Event" SG_ 2563568024 SIGMA_HPCU "true";
BA_ "Event" SG_ 2563568024 SIGMA_HPCU "true";
BA_ "Event" SG_ 2563568024 SIGMA_DTCHPCU "true";
BA_ "Event" SG_ 2563568024 SIGMA_DTCHPCU "true";
BA_ "Event" SG_ 2563568024 SIGMA_DTCHPCU "true";
BA_ "Event" SG_ 2563568024 SIGMA_DTCHPCU "true";
BA_ "Event" SG_ 2563568093 SIGMA_DCDC_HV "true";
BA_ "Event" SG_ 2563568093 SIGMA_DCDC_HV "true";
BA_ "Event" SG_ 2563568093 SIGMA_DCDC_HV "true";
BA_ "Event" SG_ 2563568093 SIGMA_DCDC_HV "true";
BA_ "Event" SG_ 2563568093 SIGMA_DTCDCDC_HV "true";
BA_ "Event" SG_ 2563568093 SIGMA_DTCDCDC_HV "true";
BA_ "Event" SG_ 2563568093 SIGMA_DTCDCDC_HV "true";
BA_ "Event" SG_ 2563568093 SIGMA_DTCDCDC_HV "true";
BA_ "Event" SG_ 2563568098 SIGMA_EBA "true";
BA_ "Event" SG_ 2563568098 SIGMA_EBA "true";
BA_ "Event" SG_ 2563568098 SIGMA_EBA "true";
BA_ "Event" SG_ 2563568098 SIGMA_EBA "true";
BA_ "Event" SG_ 2563568098 SIGMA_DTCEBA "true";
BA_ "Event" SG_ 2563568098 SIGMA_DTCEBA "true";
BA_ "Event" SG_ 2563568098 SIGMA_DTCEBA "true";
BA_ "Event" SG_ 2563568098 SIGMA_DTCEBA "true";
BA_ "Event" SG_ 2563568101 SIGMA_INV_RE "true";
BA_ "Event" SG_ 2563568101 SIGMA_INV_RE "true";
BA_ "Event" SG_ 2563568101 SIGMA_INV_RE "true";
BA_ "Event" SG_ 2563568101 SIGMA_INV_RE "true";
BA_ "Event" SG_ 2563568101 SIGMA_DTCINV_RE "true";
BA_ "Event" SG_ 2563568101 SIGMA_DTCINV_RE "true";
BA_ "Event" SG_ 2563568101 SIGMA_DTCINV_RE "true";
BA_ "Event" SG_ 2563568101 SIGMA_DTCINV_RE "true";
BA_ "Event" SG_ 2563568148 SIGMA_BSG "true";
BA_ "Event" SG_ 2563568148 SIGMA_BSG "true";
BA_ "Event" SG_ 2563568148 SIGMA_BSG "true";
BA_ "Event" SG_ 2563568148 SIGMA_BSG "true";
BA_ "Event" SG_ 2563568148 SIGMA_DTCBSG "true";
BA_ "Event" SG_ 2563568148 SIGMA_DTCBSG "true";
BA_ "Event" SG_ 2563568148 SIGMA_DTCBSG "true";
BA_ "Event" SG_ 2563568148 SIGMA_DTCBSG "true";
BA_ "Event" SG_ 2563568163 SIGMA_SRad_FL "true";
BA_ "Event" SG_ 2563568163 SIGMA_SRad_FL "true";
BA_ "Event" SG_ 2563568163 SIGMA_SRad_FL "true";
BA_ "Event" SG_ 2563568163 SIGMA_SRad_FL "true";
BA_ "Event" SG_ 2563568163 SIGMA_DTCSRad_FL "true";
BA_ "Event" SG_ 2563568163 SIGMA_DTCSRad_FL "true";
BA_ "Event" SG_ 2563568163 SIGMA_DTCSRad_FL "true";
BA_ "Event" SG_ 2563568163 SIGMA_DTCSRad_FL "true";
BA_ "Event" SG_ 2563568164 SIGMA_SRad_FR "true";
BA_ "Event" SG_ 2563568164 SIGMA_SRad_FR "true";
BA_ "Event" SG_ 2563568164 SIGMA_SRad_FR "true";
BA_ "Event" SG_ 2563568164 SIGMA_SRad_FR "true";
BA_ "Event" SG_ 2563568164 SIGMA_DTCSRad_FR "true";
BA_ "Event" SG_ 2563568164 SIGMA_DTCSRad_FR "true";
BA_ "Event" SG_ 2563568164 SIGMA_DTCSRad_FR "true";
BA_ "Event" SG_ 2563568164 SIGMA_DTCSRad_FR "true";
BA_ "Event" SG_ 2563568233 SIGMA_DMC "true";
BA_ "Event" SG_ 2563568233 SIGMA_DMC "true";
BA_ "Event" SG_ 2563568233 SIGMA_DMC "true";
BA_ "Event" SG_ 2563568233 SIGMA_DMC "true";
BA_ "Event" SG_ 2563568233 SIGMA_DTCDMC "true";
BA_ "Event" SG_ 2563568233 SIGMA_DTCDMC "true";
BA_ "Event" SG_ 2563568233 SIGMA_DTCDMC "true";
BA_ "Event" SG_ 2563568233 SIGMA_DTCDMC "true";
BA_ "Event" SG_ 2563568236 SIGMA_SRVM "true";
BA_ "Event" SG_ 2563568236 SIGMA_SRVM "true";
BA_ "Event" SG_ 2563568236 SIGMA_SRVM "true";
BA_ "Event" SG_ 2563568236 SIGMA_SRVM "true";
BA_ "Event" SG_ 2563568236 SIGMA_DTCSRVM "true";
BA_ "Event" SG_ 2563568236 SIGMA_DTCSRVM "true";
BA_ "Event" SG_ 2563568236 SIGMA_DTCSRVM "true";
BA_ "Event" SG_ 2563568236 SIGMA_DTCSRVM "true";
BA_ "Event" SG_ 2563568288 SIGMA_BLM_RPK "true";
BA_ "Event" SG_ 2563568288 SIGMA_BLM_RPK "true";
BA_ "Event" SG_ 2563568288 SIGMA_BLM_RPK "true";
BA_ "Event" SG_ 2563568288 SIGMA_BLM_RPK "true";
BA_ "Event" SG_ 2563568288 SIGMA_DTCBLM_RPK "true";
BA_ "Event" SG_ 2563568288 SIGMA_DTCBLM_RPK "true";
BA_ "Event" SG_ 2563568288 SIGMA_DTCBLM_RPK "true";
BA_ "Event" SG_ 2563568288 SIGMA_DTCBLM_RPK "true";
BA_ "Event" SG_ 2563568290 SIGMA_SCCM "true";
BA_ "Event" SG_ 2563568290 SIGMA_SCCM "true";
BA_ "Event" SG_ 2563568290 SIGMA_SCCM "true";
BA_ "Event" SG_ 2563568290 SIGMA_SCCM "true";
BA_ "Event" SG_ 2563568290 SIGMA_DTCSCCM "true";
BA_ "Event" SG_ 2563568290 SIGMA_DTCSCCM "true";
BA_ "Event" SG_ 2563568290 SIGMA_DTCSCCM "true";
BA_ "Event" SG_ 2563568290 SIGMA_DTCSCCM "true";
BA_ "Unavailable_Value" SG_ 2609102848 CGW_WakeUp_Signal "0x83C0";
BA_ "Unavailable_Value" SG_ 2615050482 FTOOLS_IVCtoSWMC "null";
BA_ "Unavailable_Value" SG_ 2615070962 FTOOLS_SWMCtoCGW "null";
BA_ "Unavailable_Value" SG_ 2615079552 FTOOLS_SWMCtoIVC "null";
BA_ "Unavailable_Value" SG_ 2615079632 FTOOLS_CGWtoSWMC "null";
VAL_ 1629 FAP_ChangeViewRequest 1 "Request" 0 "No request";
VAL_ 1629 FAP_SwitchGrayOutRequest02 1 "Requested" 0 "Not requested";
VAL_ 1629 FAP_SwitchGrayOutRequest01 1 "Requested" 0 "Not requested";
VAL_ 1629 FAP_SwitchGrayOutRequest04 1 "Requested" 0 "Not requested";
VAL_ 1629 FAP_SwitchGrayOutRequest03 1 "Requested" 0 "Not requested";
VAL_ 1629 FAP_SwitchGrayOutRequest06 1 "Requested" 0 "Not requested";
VAL_ 1629 FAP_SwitchGrayOutRequest05 1 "Requested" 0 "Not requested";
VAL_ 1629 FAP_SwitchGrayOutRequest08 1 "Requested" 0 "Not requested";
VAL_ 1629 FAP_SwitchGrayOutRequest07 1 "Requested" 0 "Not requested";
VAL_ 1629 FAP_SwitchGrayOutRequest12 1 "Requested" 0 "Not requested";
VAL_ 1629 FAP_SwitchGrayOutRequest11 1 "Requested" 0 "Not requested";
VAL_ 1629 FAP_SwitchGrayOutRequest10 1 "Requested" 0 "Not requested";
VAL_ 1629 FAP_SwitchGrayOutRequest09 1 "Requested" 0 "Not requested";
VAL_ 1629 FAP_CameraIndicatorRequest 7 "Reserved" 6 "Reserved" 5 "Reserved" 4 "Front Wide View" 3 "Rear Wide View" 2 "Rear View" 1 "Front View" 0 "No Displayed";
VAL_ 1630 FAP_SoundLevelControl 3 "Not used" 2 "Attenuate" 1 "Mute" 0 "No request";
VAL_ 1630 FAP_SoundPatternRequest 15 "Sound pattern 15" 14 "Sound pattern 14" 13 "Sound pattern 13" 12 "Sound pattern 12" 11 "Sound pattern 11" 10 "Sound pattern 10" 9 "Sound pattern 9" 8 "Sound pattern 8" 7 "Sound pattern 7" 6 "Sound pattern 6" 5 "Sound pattern 5" 4 "Sound pattern 4" 3 "Sound pattern 3" 2 "Sound pattern 2" 1 "Sound pattern 1" 0 "No sound selection";
VAL_ 1630 FAP_SoundDirection 15 "Reserved" 14 "Reserved" 13 "Reserved" 12 "Reserved" 11 "Reserved" 10 "Reserved" 9 "Right" 8 "Left" 7 "Arround" 6 "Right rear" 5 "Left rear" 4 "Rear" 3 "Right front" 2 "Left front" 1 "Front" 0 "No request";
VAL_ 1630 FAP_Setting04 3 "State 3 displayed" 2 "State 2 displayed" 1 "State 1 displayed" 0 "No display";
VAL_ 1630 FAP_Setting03 3 "State 3 displayed" 2 "State 2 displayed" 1 "State 1 displayed" 0 "No display";
VAL_ 1630 FAP_Setting02 3 "State 3 displayed" 2 "State 2 displayed" 1 "State 1 displayed" 0 "No display";
VAL_ 1630 FAP_Setting01 3 "State 3 displayed" 2 "State 2 displayed" 1 "State 1 displayed" 0 "No display";
VAL_ 1630 FAP_Setting08 3 "State 3 displayed" 2 "State 2 displayed" 1 "State 1 displayed" 0 "No display";
VAL_ 1630 FAP_Setting07 3 "State 3 displayed" 2 "State 2 displayed" 1 "State 1 displayed" 0 "No display";
VAL_ 1630 FAP_Setting06 3 "State 3 displayed" 2 "State 2 displayed" 1 "State 1 displayed" 0 "No display";
VAL_ 1630 FAP_Setting05 3 "State 3 displayed" 2 "State 2 displayed" 1 "State 1 displayed" 0 "No display";
VAL_ 1630 FAP_PurposeSwitchAvailability 1 "Available purpose switch" 0 "Ignore purpose switch";
VAL_ 1630 FAP_ModeChangeRequest 3 "Not used" 2 "Exit parking request" 1 "Entry parking request" 0 "No request";
VAL_ 1630 FAP_Setting10 3 "State 3 displayed" 2 "State 2 displayed" 1 "State 1 displayed" 0 "No display";
VAL_ 1630 FAP_Setting09 3 "State 3 displayed" 2 "State 2 displayed" 1 "State 1 displayed" 0 "No display";
VAL_ 1636 PBD_ActivationState 7 "Not Used" 6 "Not Used" 5 "Not Used" 4 "Antipinch_movement_ongoing" 3 "Movement_delayed" 2 "Closing_movement_ongoing" 1 "Opening_movement_ongoing" 0 "No activation";
VAL_ 1636 PBD_ResponseState 7 "Not Used" 6 "Antipinch_detected" 5 "Obstacle_detected" 4 "Failure_detected" 3 "ActivationRequest_Rejected_Underqualified" 2 "ActivationRequest_Completed" 1 "ActivationRequest_Accepted" 0 "No activation";
VAL_ 1636 PBD_AuthorizationState 7 "Not Used" 6 "Not Used" 5 "Not Used" 4 "PBDFailure_AllMovementsInhibited" 3 "PBDFailure_LatchReleaseAuthorized" 2 "PBDMainSwitchoff_LatchReleaseAuthorized" 1 "PBDAuthorized_AllMovementsAuthorized" 0 "PBDNotAuthorized_AllMovementsInhibited";
VAL_ 1637 SteeringSettingState_v2 15 "Not used" 14 "Not used" 13 "Drive Mode" 12 "Mode EPS 13" 11 "Mode EPS 12" 10 "Mode EPS 11 Quick / Sport" 9 "Mode EPS 10 Quick / Confort" 8 "Mode EPS 9 Quick / Normal" 7 "Mode EPS 8" 6 "Mode EPS 7 Casual / Sport" 5 "Mode EPS 6 Casual / Confort" 4 "Mode EPS 5 Casual / Normal" 3 "Mode EPS 4" 2 "Mode EPS 3 Normal / Sport" 1 "Mode EPS 2 Normal / Confort" 0 "Mode EPS 1 Normal / Normal";
VAL_ 1637 PowerTrainSettingState 15 "Not used" 14 "Not used" 13 "Mode 14" 12 "Mode 13" 11 "Mode 12" 10 "Mode 11" 9 "Mode 10" 8 "Mode 9" 7 "Mode 8" 6 "Mode 7" 5 "Mode 6" 4 "Mode 5" 3 "Mode 4 (Snow)" 2 "Mode 3 (Eco)" 1 "Mode 2 (Sport)" 0 "Mode 1 (Standard)";
VAL_ 1637 AWDSettingState 7 "Not used" 6 "Not used" 5 "Mode 6" 4 "Mode 5" 3 "Mode 4" 2 "Mode 3" 1 "Mode 2" 0 "Mode 1";
VAL_ 1637 SuspensionSettingState 7 "Not used" 6 "Not used" 5 "Mode VADA 6 (Race)" 4 "Mode VADA 5" 3 "Mode VADA 4" 2 "Mode VADA 3 (Sport)" 1 "Mode VADA 2 (Comfort)" 0 "Mode VADA 1 (Normal)";
VAL_ 1637 DriveModeState 31 "Unavailable" 30 "Mode 30" 29 "Mode 29" 28 "Mode 28" 27 "Mode 27" 26 "Mode 26" 25 "Mode 25" 24 "Mode 24" 23 "Mode 23" 22 "Mode 22" 21 "Mode 21" 20 "Mode 20" 19 "Mode 19" 18 "Mode 18" 17 "Mode 17" 16 "Mode 16" 15 "Mode 15" 14 "Mode 14" 13 "Mode 13" 12 "Mode 12" 11 "Mode 11" 10 "Mode 10" 9 "Mode 9" 8 "Mode 8" 7 "Mode 7" 6 "Mode 6" 5 "Mode 5" 4 "Mode 4" 3 "Mode 3" 2 "Mode 2" 1 "Mode 1" 0 "Mode 0";
VAL_ 1639 AllRouteSegmentsRequest 1 "Send all route segment request" 0 "No Request";
VAL_ 1640 SCdurabilityInhibition 1 "Smartcharging inhibited" 0 "No smartcharging inhibition";
VAL_ 1645 AEB_FCWactivationState2 3 "AEB ON / FCW ON" 2 "Not used" 1 "AEB OFF / FCW ON" 0 "AEB OFF / FCW OFF";
VAL_ 1645 AEB_CyclistAlertRequest2 1 "AEB cyclist alert" 0 "No AEB cyclist alert";
VAL_ 1645 AEB_PedestrianAlertRequest2 1 "AEB PEDESTRIAN alert" 0 "No AEB PEDESTRIAN alert";
VAL_ 1645 AEB_VehicleAlertRequest2 3 "AEB vehicle Alert reminder" 2 "AEB vehicle Collision alert" 1 "AEB vehicle Approach alert" 0 "No AEB vehicle alert";
VAL_ 1645 DW_ActivationState_TM 1 "DW activated" 0 "DW deactivated";
VAL_ 1645 FCW_SensibilityState 3 "Late" 2 "Standard" 1 "Early" 0 "Unavailable";
VAL_ 1658 FAP_ScreenPressDetected 3 "Not used" 2 "Invalid" 1 "Detected" 0 "No detected";
VAL_ 1658 FAP_SwitchLongPressDetected 1 "detected" 0 "Not detected";
VAL_ 1658 FAP_ActivationRequest 1 "Requested" 0 "Not Requested";
VAL_ 1658 FAP_HMIavailability 3 "All Preparation complete" 2 "Complete Sound Preparation and Start Display Preparation" 1 "Complete Display Preparation and Start Sound Preparation" 0 "Under Preparation";
VAL_ 1658 FAP_VoiceStatus 3 "Not used" 2 "Voice can't be playes" 1 "Voice is played" 0 "No voice";
VAL_ 1659 UserIdentification_IKeyLink 7 "Not used" 6 "Not used" 5 "Not used" 4 "Key No. 4" 3 "Key No. 3" 2 "Key No. 2" 1 "Key No. 1" 0 "No request";
VAL_ 1660 RearSeatsLockStatus 3 "Not Used" 2 "Thermal comfort unlock display" 1 "Thermal comfort lockdisplay" 0 "Unavailable";
VAL_ 1660 SecondRowRightSeatStatus 7 "Ventilated High display" 6 "Ventilated Middle display" 5 "Ventilated Low display" 4 "Heater High display" 3 "Heater Middle display" 2 "Heater Low display" 1 "OFF display" 0 "Unvailable";
VAL_ 1660 SecondRowLeftSeatStatus 7 "Ventilated High display" 6 "Ventilated Middle display" 5 "Ventilated Low display" 4 "Heater High display" 3 "Heater Middle display" 2 "Heater Low display" 1 "OFF display" 0 "Unvailable";
VAL_ 1660 ClimAutoRecyclingDisplayStatus 1 "Function available" 0 "Function not available";
VAL_ 1660 ClimACDisplayStatus 1 "Function available" 0 "Function not available";
VAL_ 1660 ThirdRowRightSeatStatus 7 "Ventilated High display" 6 "Ventilated Middle display" 5 "Ventilated Low display" 4 "Heater High display" 3 "Heater Middle display" 2 "Heater Low display" 1 "OFF display" 0 "Unvailable";
VAL_ 1660 ThirdRowLeftSeatStatus 7 "Ventilated High display" 6 "Ventilated Middle display" 5 "Ventilated Low display" 4 "Heater High display" 3 "Heater Middle display" 2 "Heater Low display" 1 "OFF display" 0 "Unvailable";
VAL_ 1660 ClimEVHeaterDisplayStatus 1 "Function available" 0 "Function not available";
VAL_ 1660 ClimDriverZoneDisplayStatus 1 "Function available" 0 "Function not available";
VAL_ 1660 ClimDriverZoneDisplay 3 "Not used" 2 "Driver zone OFF" 1 "Driver zone ON" 0 "No display";
VAL_ 1660 ClimClearnessDisplayStatus 1 "Function available" 0 "Function not available";
VAL_ 1660 ClimBlowingLevelDisplayStatus 1 "Function available" 0 "Function not available";
VAL_ 1660 ClimBlowingAutoDisplay 3 "Not used" 2 "Blowing auto OFF" 1 "Blowing auto ON" 0 "No display";
VAL_ 1660 ClimHumidityDisplayStatus 1 "Function available" 0 "Function not available";
VAL_ 1660 ClimForestSettingDisplayStatus 1 "Function available" 0 "Function not available";
VAL_ 1660 ClimForestDisplayStatus 1 "Function available" 0 "Function not available";
VAL_ 1660 ClimForestDisplay 3 "Not used" 2 "Forest OFF" 1 "Forest ON" 0 "No display";
VAL_ 1660 ClimFlowDistrDisplayStatus 1 "Function available" 0 "Function not available";
VAL_ 1660 ClimEVHeaterDisplay 3 "Not Used" 2 "EV heater OFF" 1 "EV heater ON" 0 "No display";
VAL_ 1660 ClimLinkDefrostAndClearnesDisp 3 "Not used" 2 "HFS and Rear def link to Clearness OFF" 1 "HFS and Rear def link to Clearness ON" 0 "No display";
VAL_ 1660 ClimHumiditySensorSensitivDisp 7 "not used" 6 "OFF" 5 "Level 5" 4 "Level 4" 3 "Level 3" 2 "Level 2" 1 "Level 1" 0 "No display";
VAL_ 1660 ClimHumidityDisplay 7 "Not used" 6 "Not used" 5 "Not used" 4 "Humidity High" 3 "Humidity Mid" 2 "Humidity Low" 1 "Humidity OFF" 0 "No display";
VAL_ 1660 ClimRightAutoDisplay 3 "Not Used" 2 "Auto OFF" 1 "Auto ON" 0 "No display";
VAL_ 1660 ClimOFFModeDisplayStatus 1 "Function available" 0 "Function not available";
VAL_ 1660 ClimLinkMaxFanSpeedAutoDisplay 7 "not used" 6 "OFF" 5 "Level 5" 4 "Level 4" 3 "Level 3" 2 "Level 2" 1 "Level 1" 0 "No display";
VAL_ 1660 ClimLinkFreshRecyAndAutoDisplay 3 "Not used" 2 "Air intake link to Auto OFF" 1 "Air intake link to Auto ON" 0 "No display";
VAL_ 1660 ClimRightFlowDistrDisplayStatus 1 "Function available" 0 "Function not available";
VAL_ 1660 ClimRightBlowingLevelDispStatus 1 "Function available" 0 "Function not available";
VAL_ 1660 ClimRightBlowingLevelDisplay 15 "Blower OFF" 14 "Level 14" 13 "Level 13" 12 "Level 12" 11 "Level 11" 10 "Level 10" 9 "Level 9" 8 "Level 8" 7 "Level 7" 6 "Level 6" 5 "Level 5" 4 "Level 4" 3 "Level 3" 2 "Level 2" 1 "Level 1" 0 "No display";
VAL_ 1660 ClimRightBlowingAutoDisplay 3 "Not used" 2 "Blowing auto OFF" 1 "Blowing auto ON" 0 "No display";
VAL_ 1660 ClimTempDisplayStatus 1 "Function available" 0 "Function not available";
VAL_ 1660 ClimSyncDisplayStatus 1 "Function available" 0 "Function not available";
VAL_ 1660 ClimSyncDisplay 3 "Not Used" 2 "Sync mode OFF" 1 "Sync mode ON" 0 "No display";
VAL_ 1660 ClimRightTempDisplayStatus 1 "Function available" 0 "Function not available";
VAL_ 1660 ClimRightFlowDistrDisplay 7 "Defrost + Vent + Feet" 6 "Defrost + Vent" 5 "Defrost + Feet" 4 "Defrost" 3 "Feet + Vent" 2 "Vent" 1 "Feet" 0 "No display";
VAL_ 1661 ITM_AirIntakeOperationType 3 "Not Used" 2 "Direct setting" 1 "FRE & REC" 0 "Push by push";
VAL_ 1661 ITM_RecyclingModeRequest 7 "Not Used" 6 "Not Used" 5 "Auto + Recycling" 4 "Auto + fresh" 3 "Recycling" 2 "Auto" 1 "Fresh" 0 "No request";
VAL_ 1662 PassengerSeatMemoRecall 7 "Not used" 6 "Recall of memorization 6" 5 "Recall of memorization 5" 4 "Recall of memorization 4" 3 "Recall of memorization 3" 2 "Recall of memorization 2" 1 "Recall of memorization 1" 0 "No recall";
VAL_ 1662 PassengerSeatMemoRequest 7 "Reset Request" 6 "Request of memorization 6" 5 "Request of memorization 5" 4 "Request of memorization 4" 3 "Request of memorization 3" 2 "Request of memorization 2" 1 "Request of memorization 1" 0 "No request of memorization";
VAL_ 1662 SecondRowRightSeatRequest 15 "Not Used" 14 "Not Used" 13 "Not Used" 12 "Not Used" 11 "Not Used" 10 "Not Used" 9 "Not Used" 8 "Reset request" 7 "Ventilated High request" 6 "Ventilated Middle request" 5 "Ventilated Low request" 4 "Heater High request" 3 "Heater Middle request" 2 "Heater Low request" 1 "OFF request" 0 "No request";
VAL_ 1662 SecondRowLeftSeatRequest 15 "Not Used" 14 "Not Used" 13 "Not Used" 12 "Not Used" 11 "Not Used" 10 "Not Used" 9 "Not Used" 8 "Reset request" 7 "Ventilated High request" 6 "Ventilated Middle request" 5 "Ventilated Low request" 4 "Heater High request" 3 "Heater Middle request" 2 "Heater Low request" 1 "OFF request" 0 "No request";
VAL_ 1662 ThirdRowRightSeatRequest 15 "Not Used" 14 "Not Used" 13 "Not Used" 12 "Not Used" 11 "Not Used" 10 "Not Used" 9 "Not Used" 8 "Reset request" 7 "Ventilated High request" 6 "Ventilated Middle request" 5 "Ventilated Low request" 4 "Heater High request" 3 "Heater Middle request" 2 "Heater Low request" 1 "OFF request" 0 "No request";
VAL_ 1662 ThirdRowLeftSeatRequest 15 "Not Used" 14 "Not Used" 13 "Not Used" 12 "Not Used" 11 "Not Used" 10 "Not Used" 9 "Not Used" 8 "Reset request" 7 "Ventilated High request" 6 "Ventilated Middle request" 5 "Ventilated Low request" 4 "Heater High request" 3 "Heater Middle request" 2 "Heater Low request" 1 "OFF request" 0 "No request";
VAL_ 1662 WirelessChargeActivationReq 3 "Not used" 2 "Deactivation request" 1 "Activation request" 0 "No request";
VAL_ 1662 RearSeatsLockRequest 3 "Reset request" 2 "Thermal comfort unlock request" 1 "Thermal comfort lock request" 0 "No request";
VAL_ 1662 ClimHumiditySensorSensitivitReq 7 "Reset request" 6 "OFF request" 5 "Level 5" 4 "Level 4" 3 "Level 3" 2 "Level 2" 1 "Level 1" 0 "No request";
VAL_ 1662 TimeFormatDisplay 1 "12h format" 0 "24h format";
VAL_ 1662 ClimFPrightBlowingRequest 15 "Blower OFF" 14 "Level 14" 13 "Level 13" 12 "Level 12" 11 "Level 11" 10 "Level 10" 9 "Level 9" 8 "Level 8" 7 "Level 7" 6 "Level 6" 5 "Level 5" 4 "Level 4" 3 "Level 3" 2 "Level 2" 1 "Level 1" 0 "No Request";
VAL_ 1662 ClimLinkPriorityFLSeatAutoReq 7 "Reset request" 6 "OFF request" 5 "Level 5" 4 "Level 4" 3 "Level 3" 2 "Level 2" 1 "Level 1" 0 "No request";
VAL_ 1662 ClimLinkMaxFanSpeedAutoReq 7 "Reset request" 6 "OFF request" 5 "Level 5" 4 "Level 4" 3 "Level 3" 2 "Level 2" 1 "Level 1" 0 "No request";
VAL_ 1662 ClimLinkPriorityFRSeatAutoReq 7 "Reset request" 6 "OFF request" 5 "Level 5" 4 "Level 4" 3 "Level 3" 2 "Level 2" 1 "Level 1" 0 "No request";
VAL_ 1681 BCI_TemporaryOFFRequest 1 "Deactivation requested" 0 "Not requested";
VAL_ 1681 IVI_ChangeLayoutRequest 31 "Layout 31" 30 "Layout 30" 29 "Layout 29" 28 "Layout 28" 27 "Layout 27" 26 "Layout 26" 25 "Layout 25" 24 "Layout 24" 23 "Layout 23" 22 "Layout 22" 21 "Layout 21" 20 "Layout 20" 19 "Layout 19" 18 "Layout 18" 17 "Layout 17" 16 "Layout 16" 15 "Layout 15" 14 "Layout 14" 13 "Layout 13" 12 "Layout 12" 11 "Layout 11" 10 "Layout 10" 9 "Layout 9" 8 "Layout 8" 7 "Layout 7" 6 "Layout 6" 5 "Layout 5" 4 "Layout 4" 3 "Layout 3" 2 "Layout 2" 1 "Layout 1" 0 "No request";
VAL_ 1681 IVI_LayoutDisplayedStatus 31 "Layout 31" 30 "Layout 30" 29 "Layout 29" 28 "Layout 28" 27 "Layout 27" 26 "Layout 26" 25 "Layout 25" 24 "Layout 24" 23 "Layout 23" 22 "Layout 22" 21 "Layout 21" 20 "Layout 20" 19 "Layout 19" 18 "Layout 18" 17 "Layout 17" 16 "Layout 16" 15 "Layout 15" 14 "Layout 14" 13 "Layout 13" 12 "Layout 12" 11 "Layout 11" 10 "Layout 10" 9 "Layout 9" 8 "Layout 8" 7 "Layout 7" 6 "Layout 6" 5 "Layout 5" 4 "Layout 4" 3 "Layout 3" 2 "Layout 2" 1 "Layout 1" 0 "No display";
VAL_ 1682 ClimHeatedSteeringWheelDisplay 3 "Not used" 2 "Heated Steering Wheel OFF" 1 "Heated Steering Wheel ON" 0 "No display";
VAL_ 1682 ClimDualModeDisplay_v2 3 "Not used" 2 "Dual Mode OFF" 1 "Dual Mode ON" 0 "No Display";
VAL_ 1684 APA_WarningDisplayRequest 63 "Not used" 62 "message62" 61 "message61" 60 "message60" 59 "message59" 58 "message58" 57 "message57" 56 "message56" 55 "message55" 54 "message54" 53 "message53" 52 "message52" 51 "message51" 50 "message50" 49 "message49" 48 "message48" 47 "message47" 46 "message46" 45 "message45" 44 "message44" 43 "message43" 42 "message42" 41 "message41" 40 "message40" 39 "message39" 38 "message38" 37 "message37" 36 "message36" 35 "message35" 34 "message34" 33 "message33" 32 "message32" 31 "message31" 30 "message30" 29 "message29" 28 "message28" 27 "message27" 26 "message26" 25 "message25" 24 "message24" 23 "message23" 22 "message22" 21 "message21" 20 "message20" 19 "message19" 18 "message18" 17 "message17" 16 "message16" 15 "message15" 14 "message14" 13 "message13" 12 "message12" 11 "message11" 10 "message10" 9 "message9" 8 "message8" 7 "message7" 6 "message6" 5 "message5" 4 "message4" 3 "message3" 2 "message2" 1 "message1" 0 "no message";
VAL_ 1684 HFP_MapContentDisplay2 3 "Guidance Display" 2 "ParkOutConfirmation Display" 1 "Scanning Display" 0 "Empty Display";
VAL_ 1684 APA_ViewMaskRequest 1 "Request" 0 "No request";
VAL_ 1684 APA_ScanInfo 7 "Not used" 6 "Not used" 5 "Not used" 4 "SlotLeftRight" 3 "SlotRight" 2 "SlotLeft" 1 "Scan" 0 "No display";
VAL_ 1685 CGW_FOTABusyFlag 1 "CGW FOTA Ready" 0 "CGW FOTA Busy";
VAL_ 1685 CGW_FOTAstatus_v2 31 "Invalid" 30 "Not used" 29 "Not used" 28 "Not used" 27 "Rollback complete" 26 "Rollback in progress" 25 "Cancel complete" 24 "Cancel failed" 23 "Cancel in progress" 22 "FOTA CLIENT related cancel complete" 21 "FOTA CLIENT related Error detected" 20 "Finishing in progress" 19 "Activation complete" 18 "Configuration complete" 17 "Configuration install in progress" 16 "Component version check in progress" 15 "Reboot in progress" 14 "Switch in progress State" 13 "Vehicle Condition check in progress" 12 "Ready for activation State" 11 "Installation complete State" 10 "Installation in progress State" 9 "Parameters check in progress State" 8 "Gateway Package Distribution complete" 7 "Gateway Package Integrity check in progress" 6 "Gateway Package Distribution in progress" 5 "Menu Package Integrity check complete" 4 "Menu Package Integrity check in progress" 3 "Menu Package distribution in progress" 2 "Inventory read complete" 1 "Inventory read in progress" 0 "Idle";
VAL_ 1695 VehicleID 0 "Table Value16392";
VAL_ 1697 ADASISv2_METADATA 0 "Table Value30476";
VAL_ 1703 ProgrammedChargeStatus 3 "Not Used" 2 "Programmed charge by Calendar" 1 "Delayed charge" 0 "Always authorized charge";
VAL_ 1724 ChargeTimeIndexReachibility 15 "Not used" 14 "Not used" 13 "Not used" 12 "Not used" 11 "Not used" 10 "Not used" 9 "Not used" 8 "Index Data 8" 7 "Index Data 7" 6 "Index Data 6" 5 "Index Data 5" 4 "Index Data 4" 3 "Index Data 3" 2 "Index Data 2" 1 "Index Data 1" 0 "No Index Data";
VAL_ 1742 PreferedLaneAssist_State 3 "Unavailable" 2 "Not Used" 1 "LKA" 0 "LDW";
VAL_ 1755 HVbatteryCoolingInProgressStatus 1 "Battery cooling in progress" 0 "No display";
VAL_ 1755 HVbatteryCoolingActivationState 1 "Battery cooling desactivated" 0 "Battery cooling activated";
VAL_ 1755 ClimHVpowerLimitationDisp_HEVC 7 "Not used" 6 "Not used" 5 "Not used" 4 "Downgraded charging time alert" 3 "No Thermal Comfort available" 2 "SOC decreasing warning" 1 "Thermal Comfort available" 0 "No display";
VAL_ 1755 HVbatteryWarmingState 1 "Battery warming ON" 0 "Battery warming OFF";
VAL_ 1779 ChargeCal1TuesdayChange_MMI 1 "Selected day" 0 "Unselected day";
VAL_ 1779 ChargeCal1MondayChange_MMI 1 "Selected day" 0 "Unselected day";
VAL_ 1779 ChargeCal1SundayChange_MMI 1 "Selected day" 0 "Unselected day";
VAL_ 1779 ChargeCal1SaturdayChange_MMI 1 "Selected day" 0 "Unselected day";
VAL_ 1779 ChargeCal1FridayChange_MMI 1 "Selected day" 0 "Unselected day";
VAL_ 1779 ChargeCal1ThursdayChange_MMI 1 "Selected day" 0 "Unselected day";
VAL_ 1779 ChargeCal1WednesdayChange_MMI 1 "Selected day" 0 "Unselected day";
VAL_ 1779 ChargeCal2TuesdayChange_MMI 1 "Selected day" 0 "Unselected day";
VAL_ 1779 ChargeCal2MondayChange_MMI 1 "Selected day" 0 "Unselected day";
VAL_ 1779 ChargeCalAllChange_MMI 3 "Not used" 2 "Reset all charge calendars request" 1 "Change all charge calendars request" 0 "No Request";
VAL_ 1779 ChargeCal2SundayChange_MMI 1 "Selected day" 0 "Unselected day";
VAL_ 1779 ChargeCal2SaturdayChange_MMI 1 "Selected day" 0 "Unselected day";
VAL_ 1779 ChargeCal2FridayChange_MMI 1 "Selected day" 0 "Unselected day";
VAL_ 1779 ChargeCal2ThursdayChange_MMI 1 "Selected day" 0 "Unselected day";
VAL_ 1779 ChargeCal2WednesdayChange_MMI 1 "Selected day" 0 "Unselected day";
VAL_ 1780 ChargeCal3TuesdayChange_MMI 1 "Selected day" 0 "Unselected day";
VAL_ 1780 ChargeCal3MondayChange_MMI 1 "Selected day" 0 "Unselected day";
VAL_ 1780 ChargeCal3SundayChange_MMI 1 "Selected day" 0 "Unselected day";
VAL_ 1780 ChargeCal3SaturdayChange_MMI 1 "Selected day" 0 "Unselected day";
VAL_ 1780 ChargeCal3FridayChange_MMI 1 "Selected day" 0 "Unselected day";
VAL_ 1780 ChargeCal3ThursdayChange_MMI 1 "Selected day" 0 "Unselected day";
VAL_ 1780 ChargeCal3WednesdayChange_MMI 1 "Selected day" 0 "Unselected day";
VAL_ 1780 ChargeCal4TuesdayChange_MMI 1 "Selected day" 0 "Unselected day";
VAL_ 1780 ChargeCal4MondayChange_MMI 1 "Selected day" 0 "Unselected day";
VAL_ 1780 ChargeCal4SundayChange_MMI 1 "Selected day" 0 "Unselected day";
VAL_ 1780 ChargeCal4SaturdayChange_MMI 1 "Selected day" 0 "Unselected day";
VAL_ 1780 ChargeCal4FridayChange_MMI 1 "Selected day" 0 "Unselected day";
VAL_ 1780 ChargeCal4ThursdayChange_MMI 1 "Selected day" 0 "Unselected day";
VAL_ 1780 ChargeCal4WednesdayChange_MMI 1 "Selected day" 0 "Unselected day";
VAL_ 1781 ChargeCal5TuesdayChange_MMI 1 "Selected day" 0 "Unselected day";
VAL_ 1781 ChargeCal5MondayChange_MMI 1 "Selected day" 0 "Unselected day";
VAL_ 1781 ChargeCal5SundayChange_MMI 1 "Selected day" 0 "Unselected day";
VAL_ 1781 ChargeCal5SaturdayChange_MMI 1 "Selected day" 0 "Unselected day";
VAL_ 1781 ChargeCal5FridayChange_MMI 1 "Selected day" 0 "Unselected day";
VAL_ 1781 ChargeCal5ThursdayChange_MMI 1 "Selected day" 0 "Unselected day";
VAL_ 1781 ChargeCal5WednesdayChange_MMI 1 "Selected day" 0 "Unselected day";
VAL_ 1781 EcoTripResetRequest 1 "Reset request" 0 "No Reset request";
VAL_ 1781 ChargeDelayedRequest 1 "Delayed charge request" 0 "No request";
VAL_ 1781 ChargeAlwaysRequest 1 "Always charge request" 0 "No request";
VAL_ 1781 FuelSaveClearHistoRequest 1 "Reset request" 0 "No Reset request";
VAL_ 1782 PreSoakCal1FridayChange_MMI 1 "Selected day" 0 "Unselected day";
VAL_ 1782 PreSoakCal1ThursdayChange_MMI 1 "Selected day" 0 "Unselected day";
VAL_ 1782 PreSoakCal1WednesdayChange_MMI 1 "Selected day" 0 "Unselected day";
VAL_ 1782 PreSoakCal1TuesdayChange_MMI 1 "Selected day" 0 "Unselected day";
VAL_ 1782 PreSoakCal1MondayChange_MMI 1 "Selected day" 0 "Unselected day";
VAL_ 1782 PreSoakCal1SundayChange_MMI 1 "Selected day" 0 "Unselected day";
VAL_ 1782 PreSoakCal1SaturdayChange_MMI 1 "Selected day" 0 "Unselected day";
VAL_ 1782 PreSoakCal2WednesdayChange_MMI 1 "Selected day" 0 "Unselected day";
VAL_ 1782 PreSoakCal2TuesdayChange_MMI 1 "Selected day" 0 "Unselected day";
VAL_ 1782 PreSoakCal2MondayChange_MMI 1 "Selected day" 0 "Unselected day";
VAL_ 1782 PreSoakCal2SundayChange_MMI 1 "Selected day" 0 "Unselected day";
VAL_ 1782 PreSoakCal2SaturdayChange_MMI 1 "Selected day" 0 "Unselected day";
VAL_ 1782 PreSoakCal2FridayChange_MMI 1 "Selected day" 0 "Unselected day";
VAL_ 1782 PreSoakCal2ThursdayChange_MMI 1 "Selected day" 0 "Unselected day";
VAL_ 1782 PreSoakCal3MondayChange_MMI 1 "Selected day" 0 "Unselected day";
VAL_ 1782 PreSoakCalAllChange_MMI 3 "Not used" 2 "Reset all presoak calendars request" 1 "Change all presoak calendars request" 0 "No Request";
VAL_ 1782 PreSoakCal3SundayChange_MMI 1 "Selected day" 0 "Unselected day";
VAL_ 1782 PreSoakCal3SaturdayChange_MMI 1 "Selected day" 0 "Unselected day";
VAL_ 1782 PreSoakCal3FridayChange_MMI 1 "Selected day" 0 "Unselected day";
VAL_ 1782 PreSoakCal3ThursdayChange_MMI 1 "Selected day" 0 "Unselected day";
VAL_ 1782 PreSoakCal3WednesdayChange_MMI 1 "Selected day" 0 "Unselected day";
VAL_ 1782 PreSoakCal3TuesdayChange_MMI 1 "Selected day" 0 "Unselected day";
VAL_ 1783 PreSoakCal4FridayChange_MMI 1 "Selected day" 0 "Unselected day";
VAL_ 1783 PreSoakCal4ThursdayChange_MMI 1 "Selected day" 0 "Unselected day";
VAL_ 1783 PreSoakCal4WednesdayChange_MMI 1 "Selected day" 0 "Unselected day";
VAL_ 1783 PreSoakCal4TuesdayChange_MMI 1 "Selected day" 0 "Unselected day";
VAL_ 1783 PreSoakCal4MondayChange_MMI 1 "Selected day" 0 "Unselected day";
VAL_ 1783 PreSoakCal4SundayChange_MMI 1 "Selected day" 0 "Unselected day";
VAL_ 1783 PreSoakCal4SaturdayChange_MMI 1 "Selected day" 0 "Unselected day";
VAL_ 1783 PreSoakCal5WednesdayChange_MMI 1 "Selected day" 0 "Unselected day";
VAL_ 1783 PreSoakCal5TuesdayChange_MMI 1 "Selected day" 0 "Unselected day";
VAL_ 1783 PreSoakCal5MondayChange_MMI 1 "Selected day" 0 "Unselected day";
VAL_ 1783 PreSoakCal5SundayChange_MMI 1 "Selected day" 0 "Unselected day";
VAL_ 1783 PreSoakCal5SaturdayChange_MMI 1 "Selected day" 0 "Unselected day";
VAL_ 1783 PreSoakCal5FridayChange_MMI 1 "Selected day" 0 "Unselected day";
VAL_ 1783 PreSoakCal5ThursdayChange_MMI 1 "Selected day" 0 "Unselected day";
VAL_ 1789 VolumAlarmActivationState 7 "Not used" 6 "Not used" 5 "Not used" 4 "Intrusion Sensor Deactivated" 3 "Intrusion Sensor Activated" 2 "Intrusion Sensor Deactivated Once" 1 "Intrusion Sensor Deactivated Ask On Exit" 0 "Unavailable";
VAL_ 1789 FOTA_TimerExpiredStatus 1 "Timer expired" 0 "No timer expired";
VAL_ 1789 FOTA_ProgStatus 1 "Timer Set" 0 "No Timer";
VAL_ 1790 RST_BMSTrackAuthorization 1 "BMS Track Allowed" 0 "BMS Track Forbidden";
VAL_ 1790 PnCchargeStationCompatibility 1 "Compatible" 0 "No Display";
VAL_ 2563507968 SIGMA_CDM 0 "Table Value16461";
VAL_ 2563507968 SIGMA_DTCCDM 0 "Table Value26862";
VAL_ 2563508019 SIGMA_PBD 0 "Table Value16399";
VAL_ 2563508019 SIGMA_DTCPBD 0 "Table Value26865";
VAL_ 2563508021 SIGMA_RADAR 0 "Table Value16466";
VAL_ 2563508021 SIGMA_DTCRADAR 0 "Table Value26884";
VAL_ 2563508022 SIGMA_PSCU 0 "Table Value16465";
VAL_ 2563508022 SIGMA_DTCPSCU 0 "Table Value26866";
VAL_ 2563508030 SIGMA_SRad_RL 0 "Table Value16470";
VAL_ 2563508030 SIGMA_DTCSRad_RL 0 "Table Value26868";
VAL_ 2563508042 SIGMA_ANC 0 "Table Value16458";
VAL_ 2563508042 SIGMA_DTCANC 0 "Table Value26859";
VAL_ 2563508064 SIGMA_VDC 0 "Table Value16380";
VAL_ 2563508064 SIGMA_DTCVDC 0 "Table Value26886";
VAL_ 2563508066 SIGMA_EPS 0 "Table Value16377";
VAL_ 2563508066 SIGMA_DTCEPS 0 "Table Value26879";
VAL_ 2563508067 SIGMA_METER 0 "Table Value16379";
VAL_ 2563508067 SIGMA_DTCMETER 0 "Table Value26883";
VAL_ 2563508068 SIGMA_HVAC 0 "Table Value28686";
VAL_ 2563508068 SIGMA_DTCHVAC 0 "Table Value28682";
VAL_ 2563508069 SIGMA_BCM 0 "Table Value16381";
VAL_ 2563508069 SIGMA_DTCBCM 0 "Table Value26877";
VAL_ 2563508071 SIGMA_IVI 0 "Table Value16383";
VAL_ 2563508071 SIGMA_DTCIVI 0 "Table Value26882";
VAL_ 2563508072 SIGMA_4WD 0 "Table Value28679";
VAL_ 2563508072 SIGMA_DTC4WD 0 "Table Value28678";
VAL_ 2563508077 SIGMA_USM 0 "Table Value16384";
VAL_ 2563508077 SIGMA_DTCUSM 0 "Table Value26885";
VAL_ 2563508078 SIGMA_SONAR 0 "Table Value28703";
VAL_ 2563508078 SIGMA_DTCSONAR 0 "Table Value28702";
VAL_ 2563508079 SIGMA_DSMU 0 "Table Value16462";
VAL_ 2563508079 SIGMA_DTCDSMU 0 "Table Value26863";
VAL_ 2563508082 SIGMA_ACU 0 "Table Value16374";
VAL_ 2563508082 SIGMA_DTCACU 0 "Table Value26874";
VAL_ 2563508093 SIGMA_ADAS 0 "Table Value16457";
VAL_ 2563508093 SIGMA_DTCADAS 0 "Table Value26875";
VAL_ 2563508099 SIGMA_A_IVC 0 "Table Value16456";
VAL_ 2563508099 SIGMA_DTCA_IVC 0 "Table Value26858";
VAL_ 2563508108 SIGMA_INV_ME 0 "Table Value27356";
VAL_ 2563508108 SIGMA_DTCINV_ME 0 "Table Value27351";
VAL_ 2563508115 SIGMA_OBC_AC 0 "Table Value28687";
VAL_ 2563508115 SIGMA_DTCOBC_AC 0 "Table Value28683";
VAL_ 2563508122 SIGMA_HEVC 0 "Table Value27338";
VAL_ 2563508122 SIGMA_DTCHEVC 0 "Table Value27347";
VAL_ 2563508130 SIGMA_AUDIOamp 0 "Table Value16459";
VAL_ 2563508130 SIGMA_DTCAUDIOamp 0 "Table Value26860";
VAL_ 2563508133 SIGMA_HNS 0 "Table Value27353";
VAL_ 2563508133 SIGMA_DTCHNS 0 "Table Value27348";
VAL_ 2563508153 SIGMA_HFM 0 "Table Value16382";
VAL_ 2563508153 SIGMA_DTCHFM 0 "Table Value26881";
VAL_ 2563508154 SIGMA_AVM 0 "Table Value27338";
VAL_ 2563508154 SIGMA_DTCAVM 0 "Table Value27343";
VAL_ 2563508157 SIGMA_SCU 0 "Table Value28688";
VAL_ 2563508157 SIGMA_DTCSCU 0 "Table Value28684";
VAL_ 2563508181 SIGMA_SRad_RR 0 "Table Value16471";
VAL_ 2563508181 SIGMA_DTCSRad_RR 0 "Table Value26871";
VAL_ 2563508189 SIGMA_FrCamera 0 "Table Value16378";
VAL_ 2563508189 SIGMA_DTCFrCamera 0 "Table Value26880";
VAL_ 2563508200 SIGMA_ECM 0 "Table Value16376";
VAL_ 2563508200 SIGMA_DTCECM 0 "Table Value26878";
VAL_ 2563508201 SIGMA_ATCU 0 "Table Value16375";
VAL_ 2563508201 SIGMA_DTCATCU 0 "Table Value26876";
VAL_ 2563508205 SIGMA_BMS_HV 0 "Table Value27340";
VAL_ 2563508205 SIGMA_DTCBMS_HV 0 "Table Value27344";
VAL_ 2563508207 SIGMA_INV_HSG 0 "Table Value27355";
VAL_ 2563508207 SIGMA_DTCINV_HSG 0 "Table Value27350";
VAL_ 2563567883 SIGMA_BMS_12V 0 "Table Value16460";
VAL_ 2563567883 SIGMA_DTCBMS_12V 0 "Table Value26861";
VAL_ 2563567951 SIGMA_EPS_sub 0 "Table Value28685";
VAL_ 2563567951 SIGMA_DTCEPS_sub 0 "Table Value28681";
VAL_ 2563567968 SIGMA_HUD 0 "Table Value27354";
VAL_ 2563567968 SIGMA_DTCHUD 0 "Table Value27349";
VAL_ 2563568024 SIGMA_HPCU 0 "Table Value55692";
VAL_ 2563568024 SIGMA_DTCHPCU 0 "Table Value55693";
VAL_ 2563568093 SIGMA_DCDC_HV 0 "Table Value28677";
VAL_ 2563568093 SIGMA_DTCDCDC_HV 0 "Table Value28680";
VAL_ 2563568098 SIGMA_EBA 0 "Table Value16463";
VAL_ 2563568098 SIGMA_DTCEBA 0 "Table Value26864";
VAL_ 2563568101 SIGMA_INV_RE 0 "Table Value27357";
VAL_ 2563568101 SIGMA_DTCINV_RE 0 "Table Value27352";
VAL_ 2563568148 SIGMA_BSG 0 "Table Value27341";
VAL_ 2563568148 SIGMA_DTCBSG 0 "Table Value27345";
VAL_ 2563568163 SIGMA_SRad_FL 0 "Table Value16468";
VAL_ 2563568163 SIGMA_DTCSRad_FL 0 "Table Value26869";
VAL_ 2563568164 SIGMA_SRad_FR 0 "Table Value16469";
VAL_ 2563568164 SIGMA_DTCSRad_FR 0 "Table Value26870";
VAL_ 2563568233 SIGMA_DMC 0 "Table Value27342";
VAL_ 2563568233 SIGMA_DTCDMC 0 "Table Value27346";
VAL_ 2563568236 SIGMA_SRVM 0 "Table Value16398";
VAL_ 2563568236 SIGMA_DTCSRVM 0 "Table Value26872";
VAL_ 2563568288 SIGMA_BLM_RPK 0 "Table Value55679";
VAL_ 2563568288 SIGMA_DTCBLM_RPK 0 "Table Value55690";
VAL_ 2563568290 SIGMA_SCCM 0 "Table Value16467";
VAL_ 2563568290 SIGMA_DTCSCCM 0 "Table Value26867";
VAL_ 2609102848 CGW_WakeUp_Signal 0 "Table Value16477";
VAL_ 2615050482 FTOOLS_IVCtoSWMC 0 "Table Value16359";
VAL_ 2615070962 FTOOLS_SWMCtoCGW 0 "Table Value16360";
VAL_ 2615079552 FTOOLS_SWMCtoIVC 0 "Table Value16361";
VAL_ 2615079632 FTOOLS_CGWtoSWMC 0 "Table Value16357";
